[part 1 of 2: packages /EcuInstances to /CommunicationClusters/BODY3]
AUTOSAR XML (schema 00049)
# Copyright (c) 2023 Mercedes-Benz AG
package /EcuInstances
  ecu instance RBTM_FL:
    variation-point=post-build-variant-condition{matching-criterion=SideAllocation, value=0}
    associated-com-i-pdu-group=[TxMess_RBTM_FL_BODY3, RBTM_FL_BODY3_Tx_PNC_All_Active, RBTM_FL_BODY3_Tx_PNC_20, RBTM_FL_BODY3_Rx_PNC_All_Active, RBTM_FL_BODY3_Rx_PNC_20]
    com-configuration-gw-time-base=0.005
    com-configuration-rx-time-base=0.005
    com-configuration-tx-time-base=0.005
    pn-reset-time=1.1
    pnc-prepare-sleep-timer=1.3
    pnc-synchronous-wakeup=false
    sleep-mode-supported=true
    wake-up-over-bus-supported=true
    can communication controller RBTM_FL_BODY3: wake-up-by-controller-supported=true, can-controller-attributes=can-controller-configuration-requirements={max-number-of-time-quanta-per-bit=20, max-sample-point=81.25, max-sync-jump-width=20, min-number-of-time-quanta-per-bit=15, min-sample-point=80, min-sync-jump-width=18.75}
    can communication connector RBTM_FL_BODY3_8uqv9blm85ehm0msat385m76v: comm-controller=RBTM_FL_BODY3, create-ecu-wakeup-source=false, pnc-gateway-type=NONE, pnc-wakeup-data-mask=268435712
  ecu instance RBTM_FL:  # RBTM_FR
    variation-point=post-build-variant-condition{matching-criterion=SideAllocation, value=1}
    associated-com-i-pdu-group=[TxMess_RBTM_FR_BODY3, RBTM_FR_BODY3_Tx_PNC_All_Active, RBTM_FR_BODY3_Tx_PNC_20, RBTM_FR_BODY3_Rx_PNC_All_Active, RBTM_FR_BODY3_Rx_PNC_20]
    com-configuration-gw-time-base=0.005
    com-configuration-rx-time-base=0.005
    com-configuration-tx-time-base=0.005
    pn-reset-time=1.1
    pnc-prepare-sleep-timer=1.3
    pnc-synchronous-wakeup=false
    sleep-mode-supported=true
    wake-up-over-bus-supported=true
    can communication controller RBTM_FR_BODY3: wake-up-by-controller-supported=true, can-controller-attributes=can-controller-configuration-requirements={max-number-of-time-quanta-per-bit=20, max-sample-point=81.25, max-sync-jump-width=20, min-number-of-time-quanta-per-bit=15, min-sample-point=80, min-sync-jump-width=18.75}
    can communication connector RBTM_FR_BODY3_4xwwtd59665s787n6ctawh7k8: comm-controller=RBTM_FR_BODY3, create-ecu-wakeup-source=false, pnc-gateway-type=NONE, pnc-wakeup-data-mask=268435712
package /Systems
  system SYSTEM_XDIS: category=SYSTEM_EXTRACT, container-i-pdu-header-byte-order=big-endian, ecu-extract-version=2023.29.00, pnc-vector-length=7, pnc-vector-offset=1, system-version=2023.29.00
package /SystemSignals
  36 x system signal:
    CRC_DPC_Md_Rq_ESP_Pr5_ST3: data-constr=c16_CRC_woSNA  # CRC-Checksumme der Signal Gruppe gemäß AUTOSAR Profil 5 / CRC-checksum of signal group according to AUTOSAR Profile 5
    CRC_PT4_PTCoor9_Pr5_ST3: data-constr=c16_CRC_woSNA  # CRC-Checksumme der Signal Gruppe gemäß AUTOSAR Profil 5 / CRC-checksum of signal group according to AUTOSAR Profile 5
    DPC_GlobalMd_Rq_ST3: compu-method=c04_DPC_GlobalMd_Rq, data-constr=c04_DPC_GlobalMd_Rq  # Fahrprogrammwahl: Anforderung Global / Driving program control: global mode request
    DPC_GlobalMd_TrgRq_ST3: compu-method=c02_Ndef_False_True_ST3, data-constr=c02_Ndef_False_True_ST3  # Fahrprogrammwahl: Global erneut anfordern / Driving program control: global mode trigger request
    DPC_Md_ABC_Preview_Rq_ST3: compu-method=c02_NDef_On_Off, data-constr=c02_NDef_On_Off  # Fahrprogrammwahl: Anforderung ABC Preview / Driving program control mode: ABC Preview request
    DPC_Md_ESP_Rq_ST3: compu-method=c04_DPC_Md_ESP_Rq_ST3, data-constr=c04_DPC_Md_ESP_Rq_ST3  # Fahrprogrammwahl: Anforderung ESP / Driving program control ESP request
    DPC_Md_eSPC_Carv_Rq_ST3: compu-method=c02_NDef_On_Off, data-constr=c02_NDef_On_Off  # Fahrprogrammwahl: eSPC Carving Anforderung / Driving program control mode: eSPC Carving request
    DPC_Md_ExhstFlap_Rq_ST3: compu-method=c03_DPC_Md_ExhaustFlap, data-constr=c03_DPC_Md_ExhaustFlap  # Fahrprogrammwahl: Anforderung Abgasklappe Modus / Driving program control: ExhaustFlap mode request
    DPC_Md_Ht_Rq_ST3: compu-method=c02_NDef_ECO_Comfort, data-constr=c02_NDef_ECO_Comfort  # Fahrprogrammwahl: Anforderung Heizung / Driving program control: heating request
    DPC_Md_PwrFreeD_Plus_Rq_ST3: compu-method=c02_NDef_On_Off, data-constr=c02_NDef_On_Off  # Fahrprogrammwahl: Anforderung "Kraftfrei in D +" / Driving program control: "Power free in D +" request
    DPC_Md_SSA_Rq_ST3: compu-method=c02_DPC_Md_SSA, data-constr=c02_DPC_Md_SSA  # Fahrprogrammwahl: Anforderung Stopp/Start-Automatik / Driving program control: stop start automatic mode request
    DPC_Md_St_Rq_ST3: compu-method=c03_DPC_Md_St, data-constr=c03_DPC_Md_St  # Fahrprogrammwahl: Anforderung Lenkung / Driving program control: steering mode request
    DPC_Md_Susp_Rq_ST3: compu-method=c05_DPC_Md_Susp_V2, data-constr=c05_DPC_Md_Susp_V2  # Fahrprogrammwahl: Anforderung Federung/Dmpfung / Driving program control: suspension mode request
    DPC_Md_SuspLvl_Rq_ST3: compu-method=c03_m2_p3_1_Init, data-constr=c03_m2_p3_1_Init  # Fahrprogrammwahl: Anforderung Fahrzeugniveau / Driving program control: suspension level mode request
    DPC_Md_Tx_Rq_ST3: compu-method=c04_NDef_Man_Auto, data-constr=c04_NDef_Man_Auto  # Fahrprogrammwahl: Antwort Getriebe (nur AMG) / Driving program control: transmission mode response (only AMG)
    PT4_PTCoor_AccelPdlPosn_D_Raw_ST3: compu-method=c08_perc_0_100_0k4, data-constr=c08_perc_0_100_0k4  # Pedalrohwert Fahrer / Accelerator pedal possition raw value (Driver)
    PT4_PTCoor_ClutchPdlPosn_CPC_ST3: compu-method=c08_perc_0_100_0k5, data-constr=c08_perc_0_100_0k5  # Kupplungspedalweg-Sensor Position (Sensor Signal aber zwei Schalter für VAN) / Clutch pedal position (sensor signal, but VAN uses 2 switches to generate this signal in some variants)
    PT4_PTCoor_DAS_Health_Stat_ST3: compu-method=c10_PT4_PTCoor_DAS_Hlth_Stat
    PT4_PTCoor_EcoRcmnd_VehHighSpd_ST3: compu-method=c08_km_p_h_30_250_1_NoRcmnd, data-constr=c08_km_p_h_30_250_1_NoRcmnd  # ECO Fahrprogramm empfohlene Höchstgeschwindigkeit / ECO drive program recommended top speed
    PT4_PTCoor_EcoRcmnd_VehSpd_ST3: compu-method=c08_km_p_h_30_250_1_NoRcmnd, data-constr=c08_km_p_h_30_250_1_NoRcmnd  # ECO Fahrprogramm empfohlene Geschwindigkeit / ECO drive program recommended speed
    PT4_PTCoor_EmgPath_Enbl_ST3: compu-method=c02_Ndef_False_True_ST3, data-constr=c02_Ndef_False_True_ST3  # Notfallpfad Parksperre verfügbar / Park lock emergency path enabled
    PT4_PTCoor_EmgPath_Volt_ST3: compu-method=c08_V_0_25k4_0k1, data-constr=c08_V_0_25k4_0k1  # Spannung Notfallpfad Parksperre / Park lock emergency path voltage
    PT4_PTCoor_EngRPM_ST3: compu-method=c14_rpm_0_16382_1, data-constr=c14_rpm_0_16382_1  # Motordrehzahl / Actual engine rpm
    PT4_PTCoor_KickDnSw_Psd_ST3: compu-method=c02_Ndef_False_True_ST3, data-constr=c02_Ndef_False_True_ST3  # Kickdown betätigt / Kickdown switch pressed
    PT4_PTCoor_LHOM_PkLk_ST3: compu-method=c02_Ndef_False_True_ST3, data-constr=c02_Ndef_False_True_ST3  # Limp-Home Status Parksperre / limp-home mode park lock
    PT4_PTCoor_ShftTcase_Enbl_ST3: compu-method=c02_NDef_Off_On_ST3, data-constr=c02_NDef_Off_On_ST3  # Schaltvorgang Tcase seitens Schaltprogramm erlaubt / shifting process Tcase on the part of shift program permits
    PT4_PTCoor_SSA_StopWarn_ST3: compu-method=c02_Ndef_False_True_ST3, data-constr=c02_Ndef_False_True_ST3  # ASS Vorwarnung Motorstopp / Stop/Start automatic pre-warning engine stop
    PT4_PTCoor_TrsmCtrl_OutRPM_ST3: compu-method=c12_rpm_0_16376_4, data-constr=c12_rpm_0_16376_4  # Aktuelle Getriebeausgangsdrehzahl / Actual transmission output rpm
    PT4_PTCoor_TxBurnOut_Stat_ST3: compu-method=c02_TxBurnOut_Stat, data-constr=c02_TxBurnOut_Stat  # Burnout Status des Getriebes(Nur in AMG Modellen verfügbar) / Burnout state of Transmission(Only provided in AMG models)
    PT4_PTCoor_VehFixMaxSpd_ST3: compu-method=c09_km_p_h_0_500_1, data-constr=c09_km_p_h_0_500_1  # Antriebsstrangbedingte Fahrzeug-Maximalgeschwindigkeit (Anzeigegeschwindigkeit) / Powertrain dependant vehicle fixed maximum speed (display speed)
    PT4_PTCoor_VEPM_DCDC_BuckSuprt_Stat_ST3: compu-method=c03_DCDCBuckSuprtStat_ST3, data-constr=c03_DCDCBuckSuprtStat_ST3  # Status DCDC-Wandler LV-Unterstützung / DCDC converter buck support state
    Rsrv1_DPC_Md_Rq_ESP_Pr5_ST3: data-constr=Rsrv05  # Reserviert für zukünftige Verwendung / Reserved for future use
    Rsrv2_DPC_Md_Rq_ESP_Pr5_ST3: data-constr=Rsrv24  # Reserviert für zukünftige Verwendung / Reserved for future use
    Rsrv4_PT4_PTCoor9_Pr5_ST3: data-constr=Rsrv27  # Reserviert für zukünftige Verwendung / Reserved for future use
    SQC_DPC_Md_Rq_ESP_Pr5_ST3: compu-method=none_1_0, data-constr=c08_0_255_1_SNA_na  # Sequenzzähler / Sequence counter
    SQC_PT4_PTCoor9_Pr5_ST3: compu-method=none_1_0, data-constr=c08_0_255_1_SNA_na  # Sequenzzähler / Sequence counter
package /SystemSignalGroups
  60 x system signal group:
    ADAS_Meta_ST3: system-signal=[ADAS_Meta_CountryCode_ST3, ADAS_Meta_CycCnt_ST3, ADAS_Meta_DrvSide_ST3, ADAS_Meta_HwVer_ST3, ADAS_Meta_MapProvid_ST3, ADAS_Meta_MapVerQuar_ST3, ADAS_Meta_MapVerYear_ST3, ADAS_Meta_ProtVer_Major_ST3, ADAS_Meta_ProtVer_Minor_ST3, ADAS_Meta_ProtVer_MinorSub_ST3, ADAS_Meta_RegionCode_ST3, ADAS_Meta_SpdUnits_ST3]  # ADAS Metadaten / ADAS meta data
    ADAS_Meta_ST3_40sly585w5zu8pqjwib3nr7y7: system-signal=[ADAS_Meta_CountryCode_ST3, ADAS_Meta_CycCnt_ST3, ADAS_Meta_DrvSide_ST3, ADAS_Meta_HwVer_ST3, ADAS_Meta_MapProvid_ST3, ADAS_Meta_MapVerQuar_ST3, ADAS_Meta_MapVerYear_ST3, ADAS_Meta_ProtVer_Major_ST3, ADAS_Meta_ProtVer_Minor_ST3, ADAS_Meta_ProtVer_MinorSub_ST3, ADAS_Meta_RegionCode_ST3, ADAS_Meta_SpdUnits_ST3]  # ADAS Metadaten (degraded) / ADAS meta data (degraded)
    ADAS_Posn_ST3: system-signal=[ADAS_Posn_Age_ST3, ADAS_Posn_CurLane_ST3, ADAS_Posn_CycCnt_ST3, ADAS_Posn_Idx_ST3, ADAS_Posn_MsgTyp_ST3, ADAS_Posn_Offset_ST3, ADAS_Posn_PathIdx_ST3, ADAS_Posn_PosConfdc_ST3, ADAS_Posn_PosProbb_ST3, ADAS_Posn_RelHead_ST3, ADAS_Posn_Spd_ST3]  # ADAS Position
    ADAS_Posn_ST3_cre9f2x2lehhx0k4gxnl4u9sg: system-signal=[ADAS_Posn_Age_ST3, ADAS_Posn_CurLane_ST3, ADAS_Posn_CycCnt_ST3, ADAS_Posn_Idx_ST3, ADAS_Posn_MsgTyp_ST3, ADAS_Posn_Offset_ST3, ADAS_Posn_PathIdx_ST3, ADAS_Posn_PosConfdc_ST3, ADAS_Posn_PosProbb_ST3, ADAS_Posn_RelHead_ST3, ADAS_Posn_Spd_ST3]  # ADAS Position (degraded)
    ADAS_Profile_Short_CurvLn_ST3: system-signal=[ADAS_ProfShort_AccurClass_CL_ST3, ADAS_ProfShort_CtrlPoint_CL_ST3, ADAS_ProfShort_CycCnt_CL_ST3, ADAS_ProfShort_Dist1_CL_ST3, ADAS_ProfShort_MsgTyp_CL_ST3, ADAS_ProfShort_Offset_CL_ST3, ADAS_ProfShort_PathIdx_CL_ST3, ADAS_ProfShort_ReTr_CL_ST3, ADAS_ProfShort_Updt_CL_ST3, ADAS_ProfShort_Value0_CL_ST3, ADAS_ProfShort_Value1_CL_ST3]  # ADAS Kurzcharakteristik Curvature Linear / ADAS short profile Curvature Linear
    ADAS_Profile_Short_CurvLn_ST3_96e9ejcafisp13h7moqj5malh: system-signal=[ADAS_ProfShort_AccurClass_CL_ST3, ADAS_ProfShort_CtrlPoint_CL_ST3, ADAS_ProfShort_CycCnt_CL_ST3, ADAS_ProfShort_Dist1_CL_ST3, ADAS_ProfShort_MsgTyp_CL_ST3, ADAS_ProfShort_Offset_CL_ST3, ADAS_ProfShort_PathIdx_CL_ST3, ADAS_ProfShort_ReTr_CL_ST3, ADAS_ProfShort_Updt_CL_ST3, ADAS_ProfShort_Value0_CL_ST3, ADAS_ProfShort_Value1_CL_ST3]  # ADAS Kurzcharakteristik Curvature Linear (degraded) / ADAS short profile Curvature Linear (degraded)
    Bckl_Sw_Fx_Stat_Pr5_ST3: system-signal=[Bckl_Sw_D_Stat_ST3, Bckl_Sw_FP_Stat_ST3, CRC_Bckl_Sw_Fx_Stat_Pr5_ST3, Rsrv1_Bckl_Sw_Fx_Stat_ST3, SQC_Bckl_Sw_Fx_Stat_Pr5_ST3]  # Bckl Sw Fx Status ST3 / Bckl Sw Fx state ST3
    Bckl_Sw_Fx_Stat_Pr5_ST3_dihag5a55iw4h5qk539fx0kup: system-signal=[Bckl_Sw_D_Stat_ST3, Bckl_Sw_FP_Stat_ST3, CRC_Bckl_Sw_Fx_Stat_Pr5_ST3, Rsrv1_Bckl_Sw_Fx_Stat_ST3, SQC_Bckl_Sw_Fx_Stat_Pr5_ST3]  # Bckl Sw Fx Status ST3 (degraded) / Bckl Sw Fx state ST3 (degraded)
    CLkS_DrRltch_Stat_Pr5_ST3: system-signal=[CRC_CLkS_DrRltch_Stat_Pr5_ST3, DrRLtch_FL_Stat_ST3, DrRLtch_FR_Stat_ST3, DrRLtch_RL_Stat_ST3, DrRLtch_RR_Stat_ST3, SQC_CLkS_DrRltch_Stat_Pr5_ST3]  # Zentralverriegelung Status Drehfalle Türen / Central Locking System Rotary latch doors state
    CLkS_DrRltch_Stat_Pr5_ST3_7at68qvnk0r9npofyykyfq82v: system-signal=[CRC_CLkS_DrRltch_Stat_Pr5_ST3, DrRLtch_FL_Stat_ST3, DrRLtch_FR_Stat_ST3, DrRLtch_RL_Stat_ST3, DrRLtch_RR_Stat_ST3, SQC_CLkS_DrRltch_Stat_Pr5_ST3]  # Zentralverriegelung Status Drehfalle Türen (degraded) / Central Locking System Rotary latch doors state (degraded)
    Develop8_Rq_RBTM_FL_ST3: system-signal=[Develop_Rq_RBTM_FL_01_ST3, Develop_Rq_RBTM_FL_02_ST3, Develop_Rq_RBTM_FL_03_ST3, Develop_Rq_RBTM_FL_04_ST3, Develop_Rq_RBTM_FL_05_ST3, Develop_Rq_RBTM_FL_06_ST3, Develop_Rq_RBTM_FL_07_ST3, Develop_Rq_RBTM_FL_08_ST3]  # Development Request
    Develop8_Rq_RBTM_FL_ST3_48g6nu8rjjp9s4bhq1x3pz06u: system-signal=[Develop_Rq_RBTM_FL_01_ST3, Develop_Rq_RBTM_FL_02_ST3, Develop_Rq_RBTM_FL_03_ST3, Develop_Rq_RBTM_FL_04_ST3, Develop_Rq_RBTM_FL_05_ST3, Develop_Rq_RBTM_FL_06_ST3, Develop_Rq_RBTM_FL_07_ST3, Develop_Rq_RBTM_FL_08_ST3]  # Development Request (degraded)
    Develop8_Rs_RBTM_FL_ST3: system-signal=[Develop_Rs_RBTM_FL_01_ST3, Develop_Rs_RBTM_FL_02_ST3, Develop_Rs_RBTM_FL_03_ST3, Develop_Rs_RBTM_FL_04_ST3, Develop_Rs_RBTM_FL_05_ST3, Develop_Rs_RBTM_FL_06_ST3, Develop_Rs_RBTM_FL_07_ST3, Develop_Rs_RBTM_FL_08_ST3]  # Development Response
    Develop8_Rs_RBTM_FL_ST3_7jg1r8p1skn6yj1t9z2s157vt: system-signal=[Develop_Rs_RBTM_FL_01_ST3, Develop_Rs_RBTM_FL_02_ST3, Develop_Rs_RBTM_FL_03_ST3, Develop_Rs_RBTM_FL_04_ST3, Develop_Rs_RBTM_FL_05_ST3, Develop_Rs_RBTM_FL_06_ST3, Develop_Rs_RBTM_FL_07_ST3, Develop_Rs_RBTM_FL_08_ST3]  # Development Response (degraded)
    DI_Odo_Pr5_ST3: system-signal=[CRC_DI_Odo_Pr5_ST3, Odo_ST3, SQC_DI_Odo_Pr5_ST3]  # DriverInformation Odometer
    DI_Odo_Pr5_ST3_e68xmtlkywxgxsdwekdjjhw3t: system-signal=[CRC_DI_Odo_Pr5_ST3, Odo_ST3, SQC_DI_Odo_Pr5_ST3]  # DriverInformation Odometer (degraded)
    DPC_Md_Rq_ESP_Pr5_ST3: system-signal=[CRC_DPC_Md_Rq_ESP_Pr5_ST3, DPC_GlobalMd_Rq_ST3, DPC_GlobalMd_TrgRq_ST3, DPC_Md_ABC_Preview_Rq_ST3, DPC_Md_ESP_Rq_ST3, DPC_Md_eSPC_Carv_Rq_ST3, DPC_Md_ExhstFlap_Rq_ST3, DPC_Md_Ht_Rq_ST3, DPC_Md_PT_Rq_ST3, DPC_Md_PwrFreeD_Plus_Rq_ST3, DPC_Md_SSA_Rq_ST3, DPC_Md_St_Rq_ST3, DPC_Md_Susp_Rq_ST3, DPC_Md_SuspLvl_Rq_ST3, DPC_Md_Tx_Rq_ST3, Rsrv1_DPC_Md_Rq_ESP_Pr5_ST3, Rsrv2_DPC_Md_Rq_ESP_Pr5_ST3, SQC_DPC_Md_Rq_ESP_Pr5_ST3]  # Dynamic select Anforderung Pr 5 ST3 / Dynamic select request Pr 5 ST3
    DPC_Md_Rq_ESP_Pr5_ST3_dcsny138uwpesz5bmssj1scqi: system-signal=DPC_Md_PT_Rq_ST3  # Dynamic select Anforderung Pr 5 ST3 (degraded) / Dynamic select request Pr 5 ST3 (degraded)
    ELC_Lvr_Stat_Pr5_ST3: system-signal=[CRC_ELC_Lvr_Stat_Pr5_ST3, ELC_HiBmLvr_Stat_ST3, ELC_TurnIndLvr_Stat_ST3, Rsrv1_ELC_Lvr_Stat_Pr5_ST3, SQC_ELC_Lvr_Stat_Pr5_ST3]  # Status Bedienhebel Außenlicht / Exterior light lever state
    ELC_Lvr_Stat_Pr5_ST3_7b68ktfwrvsk1oyozi7cntryn: system-signal=[CRC_ELC_Lvr_Stat_Pr5_ST3, ELC_HiBmLvr_Stat_ST3, ELC_TurnIndLvr_Stat_ST3, Rsrv1_ELC_Lvr_Stat_Pr5_ST3, SQC_ELC_Lvr_Stat_Pr5_ST3]  # Status Bedienhebel Außenlicht (degraded) / Exterior light lever state (degraded)
    EVC_CfgList_01_08_Pr5_ST3: system-signal=[CRC_EVC_CfgList_01_08_Pr5_ST3, EVC_CfgList_01_08_Stat_ST3, EVC_List01_BodyStyle_ST3, EVC_List02_VehLine_ST3, EVC_List03_StStyle_ST3, EVC_List04_YrOfModf_2_ST3, EVC_List05_YrOfModf_1_ST3, EVC_List06_Country_ST3, EVC_List07_TxStyle_ST3, EVC_List08_HL_Style_ST3, SQC_EVC_CfgList_01_08_Pr5_ST3]  # EVC Cfg List 01 08 Pr 5 ST3
    EVC_CfgList_01_08_Pr5_ST3_co3q1mwsf7pwxo2ix5jryc04x: system-signal=[CRC_EVC_CfgList_01_08_Pr5_ST3, EVC_CfgList_01_08_Stat_ST3, EVC_List01_BodyStyle_ST3, EVC_List02_VehLine_ST3, EVC_List03_StStyle_ST3, EVC_List04_YrOfModf_2_ST3, EVC_List05_YrOfModf_1_ST3, EVC_List06_Country_ST3, EVC_List07_TxStyle_ST3, EVC_List08_HL_Style_ST3, SQC_EVC_CfgList_01_08_Pr5_ST3]  # EVC Cfg List 01 08 Pr 5 ST3 (degraded)
    Ign_Stat_Pr5_ST3: system-signal=[CRC_Ign_Stat_Pr5_ST3, ISw_Stat_ST3, KG_StartSw_Psd_ST3, SQC_Ign_Stat_Pr5_ST3, Veh_Op_Mode_ST3]  # Zuendungsstatus / Ignition state
    Ign_Stat_Pr5_ST3_csgs1dv6drms80o1i9p49677w: system-signal=[CRC_Ign_Stat_Pr5_ST3, ISw_Stat_ST3, KG_StartSw_Psd_ST3, SQC_Ign_Stat_Pr5_ST3, Veh_Op_Mode_ST3]  # Zuendungsstatus (degraded) / Ignition state (degraded)
    Meas8_RBTM_FL_ST3: system-signal=[Meas_RBTM_FL_01_ST3, Meas_RBTM_FL_02_ST3, Meas_RBTM_FL_03_ST3, Meas_RBTM_FL_04_ST3, Meas_RBTM_FL_05_ST3, Meas_RBTM_FL_06_ST3, Meas_RBTM_FL_07_ST3, Meas_RBTM_FL_08_ST3]  # Messbotschaft / Measurement
    Meas8_RBTM_FL_ST3_72jyquhuktrmjm0hkqempja37: system-signal=[Meas_RBTM_FL_01_ST3, Meas_RBTM_FL_02_ST3, Meas_RBTM_FL_03_ST3, Meas_RBTM_FL_04_ST3, Meas_RBTM_FL_05_ST3, Meas_RBTM_FL_06_ST3, Meas_RBTM_FL_07_ST3, Meas_RBTM_FL_08_ST3]  # Messbotschaft (degraded) / Measurement (degraded)
    ORC_Impact2_Pr5_ST3: system-signal=[CRC_ORC_Impact2_Pr5_ST3, Impact_minor_ST3, Impact_P_ST3, Impact_R1_ST3, Impact_R2_ST3, Impact_Y_ST3, SQC_ORC_Impact2_Pr5_ST3, VehPosn_ST3]  # ORC Impact 2 ST3
    ORC_Impact2_Pr5_ST3_b9l09rrslyv7vj3o92j69irnd: system-signal=[CRC_ORC_Impact2_Pr5_ST3, Impact_minor_ST3, Impact_P_ST3, Impact_R1_ST3, Impact_R2_ST3, Impact_Y_ST3, SQC_ORC_Impact2_Pr5_ST3, VehPosn_ST3]  # ORC Impact 2 ST3 (degraded)
    ORC_Impact3_Pr5_ST3: system-signal=[CRC_ORC_Impact3_Pr5_ST3, Impact_F1_ST3, Impact_F2_ST3, Impact_F3_ST3, Impact_RO_type1_ST3, Impact_RO_type2_ST3, Impact_S1_ST3, Impact_S2_ST3, Impact_X_ST3, SQC_ORC_Impact3_Pr5_ST3]  # ORC Impact 3 ST3
    ORC_Impact3_Pr5_ST3_c4pqnkonfjwv3uiohsxhe9dwu: system-signal=[CRC_ORC_Impact3_Pr5_ST3, Impact_F1_ST3, Impact_F2_ST3, Impact_F3_ST3, Impact_RO_type1_ST3, Impact_RO_type2_ST3, Impact_S1_ST3, Impact_S2_ST3, Impact_X_ST3, SQC_ORC_Impact3_Pr5_ST3]  # ORC Impact 3 ST3 (degraded)
    PresfAct_Adj_Pr5_ST3: system-signal=[CRC_PresfAct_Adj_Pr5_ST3, Presf_Enbl_ST3, Presf_Fric_Fctr_Lo_ST3, Presf_FricCoeff_Estim_ST3, Presf_Lvl_ST3, Presf_Snd_Rq_ST3, PresfAccelReset_NotExcd_ST3, PresfAct_Adj_Rq_ST3, PresfAct_TensSupp_Rq_ST3, Rsrv6_Presf_Adj_ST3, SQC_PresfAct_Adj_Pr5_ST3]  # Presf Aktor Steuerung ST3 / Presf Actuator adjustment ST3
    PresfAct_Adj_Pr5_ST3_2joar1a41xrgjqab60epnbplm: system-signal=[CRC_PresfAct_Adj_Pr5_ST3, Presf_Enbl_ST3, Presf_Fric_Fctr_Lo_ST3, Presf_FricCoeff_Estim_ST3, Presf_Lvl_ST3, Presf_Snd_Rq_ST3, PresfAccelReset_NotExcd_ST3, PresfAct_Adj_Rq_ST3, PresfAct_TensSupp_Rq_ST3, Rsrv6_Presf_Adj_ST3, SQC_PresfAct_Adj_Pr5_ST3]  # Presf Aktor Steuerung ST3 (degraded) / Presf Actuator adjustment ST3 (degraded)
    PT4_PTCoor4_Pr5_ST3: system-signal=[CRC_PT4_PTCoor4_Pr5_ST3, PT4_PTCoor_EngStartPN14_Stat_ST3, PT4_PTCoor_PT_Rdy_ST3, PT4_PTCoor_SSA_EngSp_ST3, Rsrv1_PT4_PTCoor_PT_Rdy_Pr5_ST3, SQC_PT4_PTCoor4_Pr5_ST3]
    PT4_PTCoor4_Pr5_ST3_af4fxb1ykieox3itqdfzs0kpb: system-signal=[CRC_PT4_PTCoor4_Pr5_ST3, PT4_PTCoor_EngStartPN14_Stat_ST3, PT4_PTCoor_PT_Rdy_ST3, PT4_PTCoor_SSA_EngSp_ST3, Rsrv1_PT4_PTCoor_PT_Rdy_Pr5_ST3, SQC_PT4_PTCoor4_Pr5_ST3]  # PT4_PTCoor4_Pr5_ST3 (degraded)
    PT4_PTCoor9_Pr5_ST3: system-signal=[CRC_PT4_PTCoor9_Pr5_ST3, PT4_PTCoor_Accel_Md_ST3, PT4_PTCoor_AccelPdlPosn_D_Raw_ST3, PT4_PTCoor_ClutchPdlPosn_CPC_ST3, PT4_PTCoor_DAS_Health_Stat_ST3, PT4_PTCoor_EcoRcmnd_VehHighSpd_ST3, PT4_PTCoor_EcoRcmnd_VehSpd_ST3, PT4_PTCoor_EmgPath_Enbl_ST3, PT4_PTCoor_EmgPath_Volt_ST3, PT4_PTCoor_EngRPM_ST3, PT4_PTCoor_KickDnSw_Psd_ST3, PT4_PTCoor_LHOM_PkLk_ST3, PT4_PTCoor_ShftTcase_Enbl_ST3, PT4_PTCoor_SSA_StopWarn_ST3, PT4_PTCoor_TrsmCtrl_OutRPM_ST3, PT4_PTCoor_TxBurnOut_Stat_ST3, PT4_PTCoor_VehFixMaxSpd_ST3, PT4_PTCoor_VEPM_DCDC_BuckSuprt_Stat_ST3, Rsrv4_PT4_PTCoor9_Pr5_ST3, SQC_PT4_PTCoor9_Pr5_ST3]  # PT4 PT Coor 9 Pr 5 ST3
    PT4_PTCoor9_Pr5_ST3_6r95o81sst3tk9w2lzz600cw3: system-signal=PT4_PTCoor_Accel_Md_ST3  # PT4 PT Coor 9 Pr 5 ST3 (degraded)
    PT4_PTCoor_DrvPosn_Gear_Pr5_ST3: system-signal=[CRC_PT4_PTCoor_DrvPosn_Gear_Pr5_ST3, PT4_PTCoor_DrvPosn_Disp_Rq_ST3, PT4_PTCoor_DrvPosn_N_Actv_ST3, PT4_PTCoor_DrvPosn_Stat_ST3, PT4_PTCoor_DrvPosn_Target_ST3, PT4_PTCoor_Gr_ST3, PT4_PTCoor_Gr_Target_ST3, PT4_PTCoor_ShW_MnTrctAxl_D_Allowed_ST3, PT4_PTCoor_ShW_MnTrctAxl_N_Allowed_ST3, PT4_PTCoor_ShW_MnTrctAxl_P_Allow_Drv_ST3, PT4_PTCoor_ShW_MnTrctAxl_P_Allowed_ST3, PT4_PTCoor_ShW_MnTrctAxl_R_Allowed_ST3, PT4_PTCoor_SSA_Standby_Stat_ST3, Rsrv1_PT4_PTCoor_DrvPosn_Gear_Pr5_ST3, SQC_PT4_PTCoor_DrvPosn_Gear_Pr5_ST3]  # PT4 PT Coor Drv Position Gear Pr 5 ST3 / PT4 PT Coor Drv position Gear Pr 5 ST3
    PT4_PTCoor_DrvPosn_Gear_Pr5_ST3_5p8cvrni3ypvuac33rj2asfy9: system-signal=[CRC_PT4_PTCoor_DrvPosn_Gear_Pr5_ST3, PT4_PTCoor_DrvPosn_Disp_Rq_ST3, PT4_PTCoor_DrvPosn_N_Actv_ST3, PT4_PTCoor_DrvPosn_Stat_ST3, PT4_PTCoor_DrvPosn_Target_ST3, PT4_PTCoor_Gr_ST3, PT4_PTCoor_Gr_Target_ST3, PT4_PTCoor_ShW_MnTrctAxl_D_Allowed_ST3, PT4_PTCoor_ShW_MnTrctAxl_N_Allowed_ST3, PT4_PTCoor_ShW_MnTrctAxl_P_Allow_Drv_ST3, PT4_PTCoor_ShW_MnTrctAxl_P_Allowed_ST3, PT4_PTCoor_ShW_MnTrctAxl_R_Allowed_ST3, PT4_PTCoor_SSA_Standby_Stat_ST3, Rsrv1_PT4_PTCoor_DrvPosn_Gear_Pr5_ST3, SQC_PT4_PTCoor_DrvPosn_Gear_Pr5_ST3]  # PT4 PT Coor Drv Position Gear Pr 5 ST3 (degraded) / PT4 PT Coor Drv position Gear Pr 5 ST3 (degraded)
    ROE_RBTM_FL_ST3: system-signal=[ROE_0_RBTM_FL_ST3, ROE_1_RBTM_FL_ST3, ROE_2_RBTM_FL_ST3, ROE_3_RBTM_FL_ST3, ROE_4_RBTM_FL_ST3, ROE_5_RBTM_FL_ST3, ROE_6_RBTM_FL_ST3, ROE_7_RBTM_FL_ST3]  # Ereignis-Antwort / Response on Event
    ROE_RBTM_FL_ST3_6e0rxnifai2txra0wamb18g4m: system-signal=[ROE_0_RBTM_FL_ST3, ROE_1_RBTM_FL_ST3, ROE_2_RBTM_FL_ST3, ROE_3_RBTM_FL_ST3, ROE_4_RBTM_FL_ST3, ROE_5_RBTM_FL_ST3, ROE_6_RBTM_FL_ST3, ROE_7_RBTM_FL_ST3]  # Ereignis-Antwort (degraded) / Response on Event (degraded)
    SBeltTens_SP_Lvl_Pr5_ST3: system-signal=[CRC_SBeltTens_SP_Lvl_Pr5_ST3, RBTMFL_SP_Lvl_Rq_ST35, RBTMFR_SP_Lvl_Rq_ST35, Rsrv0_SBeltTens_SP_Lvl_Pr5_ST3, SQC_SBeltTens_SP_Lvl_Pr5_ST3]  # Seat Belt Tensioner SP Lvl ST3
    SBeltTens_SP_Lvl_Pr5_ST3_4tqpkri37441o5ht9g9ekmyzh: system-signal=[CRC_SBeltTens_SP_Lvl_Pr5_ST3, RBTMFL_SP_Lvl_Rq_ST35, RBTMFR_SP_Lvl_Rq_ST35, Rsrv0_SBeltTens_SP_Lvl_Pr5_ST3, SQC_SBeltTens_SP_Lvl_Pr5_ST3]  # Seat Belt Tensioner SP Lvl ST3 (degraded)
    VSS_TP_Auth_ST3: system-signal=[VSS_TP_Auth_0_ST3, VSS_TP_Auth_1_ST3, VSS_TP_Auth_2_ST3, VSS_TP_Auth_3_ST3, VSS_TP_Auth_4_ST3, VSS_TP_Auth_5_ST3, VSS_TP_Auth_6_ST3, VSS_TP_Auth_7_ST3]  # VSS-Transportprotokoll für Authentifizierung / Vehicle Security System Transport Protocol for authentication broadcast
    VSS_TP_Auth_ST3_6j4id7sghlvlbroli4wjozjik: system-signal=[VSS_TP_Auth_0_ST3, VSS_TP_Auth_1_ST3, VSS_TP_Auth_2_ST3, VSS_TP_Auth_3_ST3, VSS_TP_Auth_4_ST3, VSS_TP_Auth_5_ST3, VSS_TP_Auth_6_ST3, VSS_TP_Auth_7_ST3]  # VSS-Transportprotokoll für Authentifizierung (degraded) / Vehicle Security System Transport Protocol for authentication broadcast (degraded)
    VSS_TP_RealTmOffset_ST3: system-signal=[VSS_TP_RealTmOffset_0_ST3, VSS_TP_RealTmOffset_1_ST3, VSS_TP_RealTmOffset_2_ST3, VSS_TP_RealTmOffset_3_ST3, VSS_TP_RealTmOffset_4_ST3, VSS_TP_RealTmOffset_5_ST3, VSS_TP_RealTmOffset_6_ST3, VSS_TP_RealTmOffset_7_ST3]  # VSS-Transportprotokoll für Echtzeit-Offset / Vehicle Security System Transport Protocol for real time offset broadcast
    VSS_TP_RealTmOffset_ST3_1t7vc44gftc0wv35k5kgc2in9: system-signal=[VSS_TP_RealTmOffset_0_ST3, VSS_TP_RealTmOffset_1_ST3, VSS_TP_RealTmOffset_2_ST3, VSS_TP_RealTmOffset_3_ST3, VSS_TP_RealTmOffset_4_ST3, VSS_TP_RealTmOffset_5_ST3, VSS_TP_RealTmOffset_6_ST3, VSS_TP_RealTmOffset_7_ST3]  # VSS-Transportprotokoll für Echtzeit-Offset (degraded) / Vehicle Security System Transport Protocol for real time offset broadcast (degraded)
    VSS_TP_SecTickCount_Lvl2_ST3: system-signal=[VSS_TP_SecTickCount_Lvl2_0_ST3, VSS_TP_SecTickCount_Lvl2_1_ST3, VSS_TP_SecTickCount_Lvl2_2_ST3, VSS_TP_SecTickCount_Lvl2_3_ST3, VSS_TP_SecTickCount_Lvl2_4_ST3, VSS_TP_SecTickCount_Lvl2_5_ST3, VSS_TP_SecTickCount_Lvl2_6_ST3, VSS_TP_SecTickCount_Lvl2_7_ST3]  # VSS-Transportprotokoll für sichere Zeit Stufe 2 / Vehicle Security System Transport Protocol for secure tick count level #2
    VSS_TP_SecTickCount_Lvl2_ST3_9eubq13iosat764o0lqh5xb6r: system-signal=[VSS_TP_SecTickCount_Lvl2_0_ST3, VSS_TP_SecTickCount_Lvl2_1_ST3, VSS_TP_SecTickCount_Lvl2_2_ST3, VSS_TP_SecTickCount_Lvl2_3_ST3, VSS_TP_SecTickCount_Lvl2_4_ST3, VSS_TP_SecTickCount_Lvl2_5_ST3, VSS_TP_SecTickCount_Lvl2_6_ST3, VSS_TP_SecTickCount_Lvl2_7_ST3]  # VSS-Transportprotokoll für sichere Zeit Stufe 2 (degraded) / Vehicle Security System Transport Protocol for secure tick count level #2 (degraded)
    VSS_TP_SharedSecret_ST3: system-signal=[VSS_TP_SharedSecret_0_ST3, VSS_TP_SharedSecret_1_ST3, VSS_TP_SharedSecret_2_ST3, VSS_TP_SharedSecret_3_ST3, VSS_TP_SharedSecret_4_ST3, VSS_TP_SharedSecret_5_ST3, VSS_TP_SharedSecret_6_ST3, VSS_TP_SharedSecret_7_ST3]  # VSS-Transportprotokoll für gemeinsames Geheimnis / Vehicle Security System Transport Protocol for shared secret broadcast
    VSS_TP_SharedSecret_ST3_8pj4t8t4rm3tw3pk5hj7vonti: system-signal=[VSS_TP_SharedSecret_0_ST3, VSS_TP_SharedSecret_1_ST3, VSS_TP_SharedSecret_2_ST3, VSS_TP_SharedSecret_3_ST3, VSS_TP_SharedSecret_4_ST3, VSS_TP_SharedSecret_5_ST3, VSS_TP_SharedSecret_6_ST3, VSS_TP_SharedSecret_7_ST3]  # VSS-Transportprotokoll für gemeinsames Geheimnis (degraded) / Vehicle Security System Transport Protocol for shared secret broadcast (degraded)
    VSS_TP_VIN_ST3: system-signal=[VSS_TP_VIN_0_ST3, VSS_TP_VIN_1_ST3, VSS_TP_VIN_2_ST3, VSS_TP_VIN_3_ST3, VSS_TP_VIN_4_ST3, VSS_TP_VIN_5_ST3, VSS_TP_VIN_6_ST3, VSS_TP_VIN_7_ST3]  # VSS-Transportprotokoll für Fahrzeugidentifikationsnummer / Vehicle Security System Transport Protocol for Vehicle Identification Number
    VSS_TP_VIN_ST3_bz1xsv84cxzl09j028gn39p69: system-signal=[VSS_TP_VIN_0_ST3, VSS_TP_VIN_1_ST3, VSS_TP_VIN_2_ST3, VSS_TP_VIN_3_ST3, VSS_TP_VIN_4_ST3, VSS_TP_VIN_5_ST3, VSS_TP_VIN_6_ST3, VSS_TP_VIN_7_ST3]  # VSS-Transportprotokoll für Fahrzeugidentifikationsnummer (degraded) / Vehicle Security System Transport Protocol for Vehicle Identification Number (degraded)
    Develop8_Rq_RBTM_FR_ST3: system-signal=[Develop_Rq_RBTM_FR_01_ST3, Develop_Rq_RBTM_FR_02_ST3, Develop_Rq_RBTM_FR_03_ST3, Develop_Rq_RBTM_FR_04_ST3, Develop_Rq_RBTM_FR_05_ST3, Develop_Rq_RBTM_FR_06_ST3, Develop_Rq_RBTM_FR_07_ST3, Develop_Rq_RBTM_FR_08_ST3]  # Development Request
    Develop8_Rq_RBTM_FR_ST3_bcqj2sqez8u9spf5qxmu4a35u: system-signal=[Develop_Rq_RBTM_FR_01_ST3, Develop_Rq_RBTM_FR_02_ST3, Develop_Rq_RBTM_FR_03_ST3, Develop_Rq_RBTM_FR_04_ST3, Develop_Rq_RBTM_FR_05_ST3, Develop_Rq_RBTM_FR_06_ST3, Develop_Rq_RBTM_FR_07_ST3, Develop_Rq_RBTM_FR_08_ST3]  # Development Request (degraded)
    Develop8_Rs_RBTM_FR_ST3: system-signal=[Develop_Rs_RBTM_FR_01_ST3, Develop_Rs_RBTM_FR_02_ST3, Develop_Rs_RBTM_FR_03_ST3, Develop_Rs_RBTM_FR_04_ST3, Develop_Rs_RBTM_FR_05_ST3, Develop_Rs_RBTM_FR_06_ST3, Develop_Rs_RBTM_FR_07_ST3, Develop_Rs_RBTM_FR_08_ST3]  # Development Response
    Develop8_Rs_RBTM_FR_ST3_5t18pq0a13t698v0vsj7yvmmm: system-signal=[Develop_Rs_RBTM_FR_01_ST3, Develop_Rs_RBTM_FR_02_ST3, Develop_Rs_RBTM_FR_03_ST3, Develop_Rs_RBTM_FR_04_ST3, Develop_Rs_RBTM_FR_05_ST3, Develop_Rs_RBTM_FR_06_ST3, Develop_Rs_RBTM_FR_07_ST3, Develop_Rs_RBTM_FR_08_ST3]  # Development Response (degraded)
    Meas8_RBTM_FR_ST3: system-signal=[Meas_RBTM_FR_01_ST3, Meas_RBTM_FR_02_ST3, Meas_RBTM_FR_03_ST3, Meas_RBTM_FR_04_ST3, Meas_RBTM_FR_05_ST3, Meas_RBTM_FR_06_ST3, Meas_RBTM_FR_07_ST3, Meas_RBTM_FR_08_ST3]  # Messbotschaft / Measurement
    Meas8_RBTM_FR_ST3_7ba3lhjy9fnhufd3n9dyw0p9p: system-signal=[Meas_RBTM_FR_01_ST3, Meas_RBTM_FR_02_ST3, Meas_RBTM_FR_03_ST3, Meas_RBTM_FR_04_ST3, Meas_RBTM_FR_05_ST3, Meas_RBTM_FR_06_ST3, Meas_RBTM_FR_07_ST3, Meas_RBTM_FR_08_ST3]  # Messbotschaft (degraded) / Measurement (degraded)
    ROE_RBTM_FR_ST3: system-signal=[ROE_0_RBTM_FR_ST3, ROE_1_RBTM_FR_ST3, ROE_2_RBTM_FR_ST3, ROE_3_RBTM_FR_ST3, ROE_4_RBTM_FR_ST3, ROE_5_RBTM_FR_ST3, ROE_6_RBTM_FR_ST3, ROE_7_RBTM_FR_ST3]  # Ereignis-Antwort / Response on Event
    ROE_RBTM_FR_ST3_3f1btonh6ivdn6ytgyuu9rtt1: system-signal=[ROE_0_RBTM_FR_ST3, ROE_1_RBTM_FR_ST3, ROE_2_RBTM_FR_ST3, ROE_3_RBTM_FR_ST3, ROE_4_RBTM_FR_ST3, ROE_5_RBTM_FR_ST3, ROE_6_RBTM_FR_ST3, ROE_7_RBTM_FR_ST3]  # Ereignis-Antwort (degraded) / Response on Event (degraded)
package /Pdus/BODY3/PKG_BODY3
  pdu Bckl_Sw_Fx_Stat_ST3: length=4, minimum-delay=0.02, transmission-mode-true-timing={cyclic-timing=time-period=0.2, event-controlled-timing=number-of-repetitions=0}, unused-bit-pattern=255  # Bckl Sw Fx Status ST3 / Bckl Sw Fx state ST3
    signal Bckl_Sw_D_Stat_ST3: start 24, 2 bit, little-endian, data-type-policy=OVERRIDE, i-signal-type=PRIMITIVE, init-value=3, base-type=uint8, invalid-value=3, compu-method=c02_Bckl_Sw_Stat, data-constr=c02_Bckl_Sw_Stat, transfer-property=TRIGGERED-ON-CHANGE, to RBTM_FL(timeout 1.1 s)  # Status Gurtschloss Fahrer / Buckle switch driver state
    signal Bckl_Sw_FP_Stat_ST3: start 26, 2 bit, little-endian, data-type-policy=OVERRIDE, i-signal-type=PRIMITIVE, init-value=3, base-type=uint8, invalid-value=3, compu-method=c02_Bckl_Sw_Stat, data-constr=c02_Bckl_Sw_Stat, transfer-property=TRIGGERED-ON-CHANGE, to RBTM_FL(timeout 1.1 s)  # Status Gurtschloss Beifahrer / Buckle switch front passenger state
    signal CRC_Bckl_Sw_Fx_Stat_Pr5_ST3: start 0, 16 bit, little-endian, data-type-policy=OVERRIDE, i-signal-type=PRIMITIVE, init-value=33522, base-type=uint16, data-constr=c16_CRC_woSNA, transfer-property=PENDING, to RBTM_FL(timeout 1.1 s)  # CRC-Checksumme der Signal Gruppe gemäß AUTOSAR Profil 5 / CRC-checksum of signal group according to AUTOSAR Profile 5
    signal SQC_Bckl_Sw_Fx_Stat_Pr5_ST3: start 16, 8 bit, little-endian, data-type-policy=OVERRIDE, i-signal-type=PRIMITIVE, init-value=0, base-type=uint8, compu-method=none_1_0, data-constr=c08_0_255_1_SNA_na, transfer-property=PENDING, to RBTM_FL(timeout 1.1 s)  # Sequenzzähler / Sequence counter
    signal Rsrv1_Bckl_Sw_Fx_Stat_ST3: start 28, 4 bit, little-endian, data-type-policy=OVERRIDE, i-signal-type=PRIMITIVE, init-value=15, base-type=uint8, invalid-value=15, data-constr=Rsrv04, transfer-property=PENDING, to RBTM_FL  # Reserviert für zukünftige Verwendung / Reserved for future use
    mapping Bckl_Sw_Fx_Stat_Pr5_ST3_dihag5a55iw4h5qk539fx0kup: i-signal-group=Bckl_Sw_Fx_Stat_Pr5_ST3_dihag5a55iw4h5qk539fx0kup, packing-byte-order=little-endian, transfer-property=TRIGGERED-ON-CHANGE
  pdu ELC_Lvr_Stat_ST3: length=4, minimum-delay=0.02, transmission-mode-true-timing={cyclic-timing=time-period=0.1, event-controlled-timing=number-of-repetitions=0}, unused-bit-pattern=255  # Status Bedienhebel Außenlicht / Exterior light lever state
    signal ELC_TurnIndLvr_Stat_ST3: start 24, 2 bit, little-endian, data-type-policy=OVERRIDE, i-signal-type=PRIMITIVE, init-value=0, base-type=uint8, invalid-value=3, compu-method=c02_TurnIndLvr_Stat, data-constr=c02_TurnIndLvr_Stat, to RBTM_FL(timeout 1.1 s)  # Status Blinkerhebel / Turn indicator lever state
    signal CRC_ELC_Lvr_Stat_Pr5_ST3: start 0, 16 bit, little-endian, data-type-policy=OVERRIDE, i-signal-type=PRIMITIVE, init-value=40318, base-type=uint16, data-constr=c16_CRC_woSNA, transfer-property=PENDING  # CRC-Checksumme der Signal Gruppe gemäß AUTOSAR Profil 5 / CRC-checksum of signal group according to AUTOSAR Profile 5
    signal ELC_HiBmLvr_Stat_ST3: start 26, 2 bit, little-endian, data-type-policy=OVERRIDE, i-signal-type=PRIMITIVE, init-value=0, base-type=uint8, invalid-value=3, compu-method=c02_HiBmLvr_Stat, data-constr=c02_HiBmLvr_Stat, transfer-property=PENDING  # Fernlichthebel Betätigung / High beam lever state
    signal Rsrv1_ELC_Lvr_Stat_Pr5_ST3: start 28, 4 bit, little-endian, data-type-policy=OVERRIDE, i-signal-type=PRIMITIVE, init-value=15, base-type=uint8, invalid-value=15, data-constr=Rsrv04, transfer-property=PENDING  # Reserviert für zukünftige Verwendung / Reserved for future use
    signal SQC_ELC_Lvr_Stat_Pr5_ST3: start 16, 8 bit, little-endian, data-type-policy=OVERRIDE, i-signal-type=PRIMITIVE, init-value=0, base-type=uint8, compu-method=none_1_0, data-constr=c08_0_255_1_SNA_na, transfer-property=PENDING  # Sequenzzähler / Sequence counter
    mapping ELC_Lvr_Stat_Pr5_ST3_7b68ktfwrvsk1oyozi7cntryn: i-signal-group=ELC_Lvr_Stat_Pr5_ST3_7b68ktfwrvsk1oyozi7cntryn, packing-byte-order=little-endian, transfer-property=TRIGGERED-ON-CHANGE
  pdu Ign_Stat_ST3: length=4, minimum-delay=0.02, transmission-mode-true-timing={cyclic-timing=time-period=0.1, event-controlled-timing=number-of-repetitions=0}, unused-bit-pattern=255  # Zuendungsstatus / Ignition state
    signal CRC_Ign_Stat_Pr5_ST3: start 0, 16 bit, little-endian, data-type-policy=OVERRIDE, i-signal-type=PRIMITIVE, init-value=20886, base-type=uint16, data-constr=c16_CRC_woSNA, transfer-property=PENDING, to RBTM_FL(timeout 1.05 s)  # CRC-Checksumme der Signal Gruppe gemäß AUTOSAR Profil 5 / CRC-checksum of signal group according to AUTOSAR Profile 5
    signal ISw_Stat_ST3: start 24, 3 bit, little-endian, data-type-policy=OVERRIDE, i-signal-type=PRIMITIVE, init-value=7, base-type=uint8, invalid-value=7, compu-method=c03_ISw_Stat, data-constr=c03_ISw_Stat, transfer-property=TRIGGERED-ON-CHANGE, to RBTM_FL(timeout 1.05 s)  # Klemmenstatus / Ignition switch state
    signal SQC_Ign_Stat_Pr5_ST3: start 16, 8 bit, little-endian, data-type-policy=OVERRIDE, i-signal-type=PRIMITIVE, init-value=0, base-type=uint8, compu-method=none_1_0, data-constr=c08_0_255_1_SNA_na, transfer-property=PENDING, to RBTM_FL(timeout 1.05 s)  # Sequenzzähler / Sequence counter
    signal KG_StartSw_Psd_ST3: start 31, 1 bit, little-endian, data-type-policy=OVERRIDE, i-signal-type=PRIMITIVE, init-value=0, base-type=boolean, transfer-property=PENDING, to RBTM_FL  # Keyless Go Starttaster betätigt / Keyless Go start switch pressed
    signal Veh_Op_Mode_ST3: start 27, 4 bit, little-endian, data-type-policy=OVERRIDE, i-signal-type=PRIMITIVE, init-value=0, base-type=uint8, invalid-value=15, compu-method=c04_VehOpMode, data-constr=c04_VehOpMode, transfer-property=PENDING, to RBTM_FL  # Fahrzeug Betriebsmodus / Operating Mode Vehicle
    mapping Ign_Stat_Pr5_ST3_csgs1dv6drms80o1i9p49677w: i-signal-group=Ign_Stat_Pr5_ST3_csgs1dv6drms80o1i9p49677w, packing-byte-order=little-endian, transfer-property=TRIGGERED-ON-CHANGE
  pdu Impact2_ST3: length=4, minimum-delay=0.02, transmission-mode-condition{data-filter={data-filter-type=MASKED-NEW-DIFFERS-X, mask=1, x=0}, i-signal-in-i-pdu=Impact_Y_ST3}, transmission-mode-false-timing=cyclic-timing=time-period=0.5, transmission-mode-true-timing=cyclic-timing=time-period=0.02, unused-bit-pattern=255  # ORC Impact 2 ST3
    signal Impact_Y_ST3: start 24, 1 bit, little-endian, data-type-policy=OVERRIDE, i-signal-type=PRIMITIVE, init-value=0, base-type=boolean, to RBTM_FL  # Beliebiges Crashereignis vorhanden (Red) / Any impact event (Redundancy)
    signal CRC_ORC_Impact2_Pr5_ST3: start 0, 16 bit, little-endian, data-type-policy=OVERRIDE, i-signal-type=PRIMITIVE, init-value=38142, base-type=uint16, data-constr=c16_CRC_woSNA  # CRC-Checksumme der Signal Gruppe gemäß AUTOSAR Profil 5 / CRC-checksum of signal group according to AUTOSAR Profile 5
    signal Impact_minor_ST3: start 25, 1 bit, little-endian, data-type-policy=OVERRIDE, i-signal-type=PRIMITIVE, init-value=0, base-type=boolean  # Bagatellunfall / minor impact
    signal Impact_P_ST3: start 28, 1 bit, little-endian, data-type-policy=OVERRIDE, i-signal-type=PRIMITIVE, init-value=0, base-type=boolean  # Fußgängeranprall / pedestrian collision
    signal Impact_R1_ST3: start 27, 1 bit, little-endian, data-type-policy=OVERRIDE, i-signal-type=PRIMITIVE, init-value=0, base-type=boolean  # Heckaufprall Stufe 1 / Collision rear level 1
    signal Impact_R2_ST3: start 26, 1 bit, little-endian, data-type-policy=OVERRIDE, i-signal-type=PRIMITIVE, init-value=0, base-type=boolean  # Heckaufprall Stufe 2 / Collision rear level 2
    signal SQC_ORC_Impact2_Pr5_ST3: start 16, 8 bit, little-endian, data-type-policy=OVERRIDE, i-signal-type=PRIMITIVE, init-value=0, base-type=uint8, compu-method=none_1_0, data-constr=c08_0_255_1_SNA_na  # Sequenzzähler / Sequence counter
    signal VehPosn_ST3: start 29, 3 bit, little-endian, data-type-policy=OVERRIDE, i-signal-type=PRIMITIVE, init-value=0, base-type=uint8, invalid-value=7, compu-method=c03_VehPos_ST3, data-constr=c03_VehPos_ST3  # Fahrzeugendlage / Vehicle Position
    mapping ORC_Impact2_Pr5_ST3_b9l09rrslyv7vj3o92j69irnd: i-signal-group=ORC_Impact2_Pr5_ST3_b9l09rrslyv7vj3o92j69irnd, packing-byte-order=little-endian, transfer-property=PENDING
  pdu ADAS_PREDICTION_ST3_6: length=8, transmission-mode-condition{data-filter={data-filter-type=MASKED-NEW-EQUALS-X, mask=7, x=6}, i-signal-in-i-pdu=ADAS_Prediction_MsgTyp_ST36}, transmission-mode-true-timing=cyclic-timing=time-period=0.1, unused-bit-pattern=255
    signal ADAS_Meta_RegionCode_ST36: start 33, 15 bit, little-endian, data-type-policy=OVERRIDE, i-signal-type=PRIMITIVE, init-value=32767, base-type=uint16, invalid-value=32767, compu-method=c15_ADAS_RegionCode, data-constr=c15_ADAS_RegionCode, to RBTM_FL(timeout 10.1 s)  # Gebietscode / Region Code
    signal ADAS_Meta_CountryCode_ST36: start 6, 10 bit, little-endian, data-type-policy=OVERRIDE, i-signal-type=PRIMITIVE, init-value=0, base-type=uint16, invalid-value=1023, compu-method=c10_ADAS_CountryCode, data-constr=c10_ADAS_CountryCode, to RBTM_FL(timeout 10.1 s)  # Ländercode / Country Code
    signal ADAS_Prediction_MsgTyp_ST36: start 0, 3 bit, little-endian, data-type-policy=OVERRIDE, i-signal-type=PRIMITIVE, init-value=7, base-type=uint8, invalid-value=7, compu-method=c03_MsgTyp_1_to_7, data-constr=c03_MsgTyp_1_to_7, transfer-property=PENDING, to RBTM_FL  # ADAS Prediction: Message Type
    signal ADAS_Meta_ProtVer_MinorSub_ST36: start 17, 3 bit, little-endian, data-type-policy=OVERRIDE, i-signal-type=PRIMITIVE, init-value=0, base-type=uint8, compu-method=c03_0_to_7_1_no_SNA, data-constr=c03_0_to_7_1_no_SNA  # (Subunter-) Protokoll-Version / Protocol Version (Sub-Minor)
    signal ADAS_Meta_MapVerYear_ST36: start 48, 6 bit, little-endian, data-type-policy=OVERRIDE, i-signal-type=PRIMITIVE, init-value=63, base-type=uint8, invalid-value=63, compu-method=c06_ADAS_MapVerYear, data-constr=c06_ADAS_MapVerYear  # Kartenversion (Jahr) / Map Version (Year)
    signal ADAS_Meta_ProtVer_Minor_ST36: start 56, 4 bit, little-endian, data-type-policy=OVERRIDE, i-signal-type=PRIMITIVE, init-value=0, base-type=uint8, compu-method=c04_0_15_1_SNA_na, data-constr=c04_0_15_1_SNA_na  # (Unter-) Protokoll-Version / Protocol Version (Minor)
    signal ADAS_Meta_CycCnt_ST36: start 22, 2 bit, little-endian, data-type-policy=OVERRIDE, i-signal-type=PRIMITIVE, init-value=0, base-type=uint8, compu-method=c02_0_3_1_nSNA, data-constr=c02_0_3_1_nSNA  # zyklischer Zähler / Cyclic Counter
    signal ADAS_Meta_SpdUnits_ST36: start 60, 1 bit, little-endian, data-type-policy=OVERRIDE, i-signal-type=PRIMITIVE, init-value=0, base-type=uint8, compu-method=c01_UnitVehSpd, data-constr=c01_UnitVehSpd  # Angabe Geschwindigkeitseinheit / Definition Speed Unit
    signal ADAS_Meta_MapProvid_ST36: start 3, 3 bit, little-endian, data-type-policy=OVERRIDE, i-signal-type=PRIMITIVE, init-value=7, base-type=uint8, invalid-value=7, compu-method=c03_ADAS_MapProvid, data-constr=c03_ADAS_MapProvid  # Kartenanbieter / Map Provider
    signal ADAS_Meta_ProtVer_Major_ST36: start 20, 2 bit, little-endian, data-type-policy=OVERRIDE, i-signal-type=PRIMITIVE, init-value=0, base-type=uint8, compu-method=c02_0_3_1_nSNA, data-constr=c02_0_3_1_nSNA  # (Haupt-) Protokoll-Version / Protocol Version (Major)
    signal ADAS_Meta_MapVerQuar_ST36: start 54, 2 bit, little-endian, data-type-policy=OVERRIDE, i-signal-type=PRIMITIVE, init-value=0, base-type=uint8, compu-method=c02_ADAS_MapVerQuar, data-constr=c02_ADAS_MapVerQuar  # Kartenversion (Quartal) / Map Version (Quarter)
    signal ADAS_Meta_DrvSide_ST36: start 16, 1 bit, little-endian, data-type-policy=OVERRIDE, i-signal-type=PRIMITIVE, init-value=1, base-type=uint8, compu-method=c01_Right_Left, data-constr=c01_Right_Left  # Seite auf der gefahren wird / Driving Side
    signal ADAS_Meta_HwVer_ST36: start 24, 9 bit, little-endian, data-type-policy=OVERRIDE, i-signal-type=PRIMITIVE, init-value=0, base-type=uint16, compu-method=c09_ADAS_HwVer, data-constr=c09_ADAS_HwVer  # Hardware Version
    mapping ADAS_Meta_ST3_40sly585w5zu8pqjwib3nr7y7: i-signal-group=ADAS_Meta_ST3_40sly585w5zu8pqjwib3nr7y7_6, packing-byte-order=little-endian, transfer-property=PENDING
  pdu ADAS_PREDICTION_ST3_7: length=8, transmission-mode-condition{data-filter={data-filter-type=MASKED-NEW-EQUALS-X, mask=7, x=7}, i-signal-in-i-pdu=ADAS_Prediction_MsgTyp_ST37}, transmission-mode-true-timing=cyclic-timing=time-period=0.1, unused-bit-pattern=255
    signal ADAS_Prediction_MsgTyp_ST37: start 0, 3 bit, little-endian, data-type-policy=OVERRIDE, i-signal-type=PRIMITIVE, init-value=7, base-type=uint8, invalid-value=7, compu-method=c03_MsgTyp_1_to_7, data-constr=c03_MsgTyp_1_to_7, transfer-property=PENDING, to RBTM_FL  # ADAS Prediction: Message Type
  pdu ADAS_PROFILE_SHORT_ST3_1: length=8, transmission-mode-condition{data-filter={data-filter-type=MASKED-NEW-EQUALS-X, mask=31, x=1}, i-signal-in-i-pdu=ADAS_ProfShort_ProfTyp_ST31}, transmission-mode-true-timing=cyclic-timing=time-period=0.1, unused-bit-pattern=255
    signal ADAS_ProfShort_ProfTyp_ST31: start 27, 5 bit, little-endian, data-type-policy=OVERRIDE, i-signal-type=PRIMITIVE, init-value=31, base-type=uint8, invalid-value=31, compu-method=c05_ADAS_ProfShort_ProfTyp, data-constr=c05_ADAS_ProfShort_ProfTyp, transfer-property=PENDING, to RBTM_FL  # Profile Short Message: Profiltyp / Profile Short Message: Profile Type
    signal ADAS_ProfShort_Value1_CL_ST31: start 54, 10 bit, little-endian, data-type-policy=OVERRIDE, i-signal-type=PRIMITIVE, init-value=0, base-type=uint16, invalid-value=1023, compu-method=c10_to_1022_1, data-constr=c10_to_1022_1, to RBTM_FL(timeout 1.1 s)  # Profile Short Message: Value1 Curvature Linear
    signal ADAS_ProfShort_PathIdx_CL_ST31: start 16, 6 bit, little-endian, data-type-policy=OVERRIDE, i-signal-type=PRIMITIVE, init-value=0, base-type=uint8, compu-method=c06_Idx_0_to_63_1, data-constr=c06_Idx_0_to_63_1, to RBTM_FL(timeout 1.1 s)  # Profile Short Message: Pfadnummer Curvature Linear (LongValue=false) / Profile Short Message: Index of path Curvature Linear (LongValue=false)
    signal ADAS_ProfShort_Value0_CL_ST31: start 34, 10 bit, little-endian, data-type-policy=OVERRIDE, i-signal-type=PRIMITIVE, init-value=1023, base-type=uint16, invalid-value=1023, compu-method=c10_to_1022_1, data-constr=c10_to_1022_1, to RBTM_FL(timeout 1.1 s)  # Profile Short Message: Value0 Curvature Linear
    signal ADAS_ProfShort_ReTr_CL_ST31: start 25, 1 bit, little-endian, data-type-policy=OVERRIDE, i-signal-type=PRIMITIVE, init-value=0, base-type=uint8, compu-method=c01_FalseTrue, data-constr=c01_FalseTrue, to RBTM_FL(timeout 1.1 s)  # Profile Short Message: Wiederholte Übertragung Curvature Linear (LongValue=false) / Profile Short Message: Retransmission Curvature Linear (LongValue=false)
    signal ADAS_ProfShort_Offset_CL_ST31: start 3, 13 bit, little-endian, data-type-policy=OVERRIDE, i-signal-type=PRIMITIVE, init-value=8191, base-type=uint16, invalid-value=8191, compu-method=c13_m_0_8190_1, data-constr=c13_m_0_8190_1, to RBTM_FL(timeout 1.1 s)  # Profile Short Message: Offset des Ortes des ersten Profils zum Startort Curvature Linear (LongValue=false) / Profile Short Message: Offset of position of first profile spot from start position Curvature Linear (LongValue=false)
    signal ADAS_ProfShort_Dist1_CL_ST31: start 44, 10 bit, little-endian, data-type-policy=OVERRIDE, i-signal-type=PRIMITIVE, init-value=0, base-type=uint16, invalid-value=1023, compu-method=c10_m_0_510_1, data-constr=c10_m_0_510_1, to RBTM_FL(timeout 1.1 s)  # Profile Short Message: Distance1 Curvature Linear
    signal ADAS_ProfShort_AccurClass_CL_ST31: start 32, 2 bit, little-endian, data-type-policy=OVERRIDE, i-signal-type=PRIMITIVE, init-value=0, base-type=uint8, compu-method=c02_0_3_1_nSNA, data-constr=c02_0_3_1_nSNA  # Profile Short Message: Genauigkeitsklasse Curvature Linear (LongValue=false) / Profile Short Message: Accuracy class Curvature Linear (LongValue=false)
    signal ADAS_ProfShort_CtrlPoint_CL_ST31: start 26, 1 bit, little-endian, data-type-policy=OVERRIDE, i-signal-type=PRIMITIVE, init-value=0, base-type=uint8, compu-method=c01_FalseTrue, data-constr=c01_FalseTrue  # Profile Short Message: Zusätzlicher Kontrollpunkt Curvature Linear (LongValue=false) / Profile Short Message: Additional control point Curvature Linear (LongValue=false)
    signal ADAS_ProfShort_MsgTyp_CL_ST31: start 0, 3 bit, little-endian, data-type-policy=OVERRIDE, i-signal-type=PRIMITIVE, init-value=4, base-type=uint8, invalid-value=7, compu-method=c03_MsgTyp_1_to_7, data-constr=c03_MsgTyp_1_to_7  # Profile Short Message: Messagetyp Curvature Linear (LongValue=false) / Profile Short Message: Message Type Curvature Linear (LongValue=false)
    signal ADAS_ProfShort_CycCnt_CL_ST31: start 22, 2 bit, little-endian, data-type-policy=OVERRIDE, i-signal-type=PRIMITIVE, init-value=0, base-type=uint8, compu-method=c02_0_3_1_nSNA, data-constr=c02_0_3_1_nSNA  # Profile Short Message: Zyklischer Zähler Curvature Linear (LongValue=false) / Profile Short Message: Cyclic Counter Curvature Linear (LongValue=false)
    signal ADAS_ProfShort_Updt_CL_ST31: start 24, 1 bit, little-endian, data-type-policy=OVERRIDE, i-signal-type=PRIMITIVE, init-value=0, base-type=uint8, compu-method=c01_FalseTrue, data-constr=c01_FalseTrue  # Profile Short Message: Update Curvature Linear (LongValue=false)
    mapping ADAS_Profile_Short_CurvLn_ST3_96e9ejcafisp13h7moqj5malh: i-signal-group=ADAS_Profile_Short_CurvLn_ST3_96e9ejcafisp13h7moqj5malh_1, packing-byte-order=little-endian, transfer-property=PENDING
  pdu ADAS_PROFILE_SHORT_ST3_31: length=8, transmission-mode-condition{data-filter={data-filter-type=MASKED-NEW-EQUALS-X, mask=31, x=31}, i-signal-in-i-pdu=ADAS_ProfShort_ProfTyp_ST331}, transmission-mode-true-timing=cyclic-timing=time-period=0.1, unused-bit-pattern=255
    signal ADAS_ProfShort_ProfTyp_ST331: start 27, 5 bit, little-endian, data-type-policy=OVERRIDE, i-signal-type=PRIMITIVE, init-value=31, base-type=uint8, invalid-value=31, compu-method=c05_ADAS_ProfShort_ProfTyp, data-constr=c05_ADAS_ProfShort_ProfTyp, transfer-property=PENDING, to RBTM_FL  # Profile Short Message: Profiltyp / Profile Short Message: Profile Type
  dcm i pdu SDU_DIAG_GLOBAL_ExtCAN_RQ_BODY3_ST3: length=7, diag-pdu-type=DIAG-REQUEST
  dcm i pdu SDU_DIAG_GLOBAL_ExtEth_RQ_BODY3_ST3: length=7, diag-pdu-type=DIAG-REQUEST
  dcm i pdu SDU_DIAG_GLOBAL_IntEth_RQ_BODY3_ST3: length=7, diag-pdu-type=DIAG-REQUEST
  dcm i pdu SDU_DIAG_RBTM_FL_03_ExtCAN_RQ_BODY3_ST3: length=4095, diag-pdu-type=DIAG-REQUEST
  dcm i pdu SDU_DIAG_RBTM_FL_03_ExtCAN_RS_BODY3_ST3: length=4095, diag-pdu-type=DIAG-RESPONSE
  dcm i pdu SDU_DIAG_RBTM_FL_03_ExtEth_RQ_BODY3_ST3: length=4095, diag-pdu-type=DIAG-REQUEST
  dcm i pdu SDU_DIAG_RBTM_FL_03_ExtEth_RS_BODY3_ST3: length=4095, diag-pdu-type=DIAG-RESPONSE
  dcm i pdu SDU_DIAG_RBTM_FL_03_IntEth_RQ_BODY3_ST3: length=4095, diag-pdu-type=DIAG-REQUEST
  dcm i pdu SDU_DIAG_RBTM_FL_03_IntEth_RS_BODY3_ST3: length=4095, diag-pdu-type=DIAG-RESPONSE
  dcm i pdu SDU_DIAG_RBTM_FR_03_ExtCAN_RQ_BODY3_ST3: length=4095, diag-pdu-type=DIAG-REQUEST
  dcm i pdu SDU_DIAG_RBTM_FR_03_ExtCAN_RS_BODY3_ST3: length=4095, diag-pdu-type=DIAG-RESPONSE
  dcm i pdu SDU_DIAG_RBTM_FR_03_ExtEth_RQ_BODY3_ST3: length=4095, diag-pdu-type=DIAG-REQUEST
  dcm i pdu SDU_DIAG_RBTM_FR_03_ExtEth_RS_BODY3_ST3: length=4095, diag-pdu-type=DIAG-RESPONSE
  dcm i pdu SDU_DIAG_RBTM_FR_03_IntEth_RQ_BODY3_ST3: length=4095, diag-pdu-type=DIAG-REQUEST
  dcm i pdu SDU_DIAG_RBTM_FR_03_IntEth_RS_BODY3_ST3: length=4095, diag-pdu-type=DIAG-RESPONSE
package /DataTransformations
  data transformation set DATATRANSFORMATION_SET
    4 x data transformation, all with execute-despite-data-unavailability=true:
      BaseTrans_Profile_5_4: transformer-chain=[ComBasedTransformer4, E2E_Profile_5]  # Base Transformer Base Profile 5
      BaseTrans_Profile_5_8: transformer-chain=[ComBasedTransformer8, E2E_Profile_5]  # Base Transformer Base Profile 5
      BaseTrans_Profile_5_5: transformer-chain=[ComBasedTransformer5, E2E_Profile_5]  # Base Transformer Base Profile 5
      BaseTrans_Profile_5_6: transformer-chain=[ComBasedTransformer6, E2E_Profile_5]  # Base Transformer Base Profile 5
    5 x transformation technology:
      ComBasedTransformer4: buffer-properties={buffer-computation=compu-rational-coeffs={compu-numerator=4, compu-denominator=1}, header-length=0, in-place=false}, protocol=COMBased, transformer-class=SERIALIZER, version=1
      E2E_Profile_5:  # E2E Profile 5
        buffer-properties={header-length=0, in-place=true}
        has-internal-state=true
        needs-original-data=false
        protocol=E2E
        end-to-end-transformation-description{e-2-e-profile-compatibility-props=E_2_E_PROFILE_COMPATIBILITY_PROPS_true, max-delta-counter=3, max-error-state-init=0, max-error-state-invalid=0, max-error-state-valid=0, min-ok-state-init=1, min-ok-state-invalid=1, min-ok-state-valid=1, offset=0, profile-name=PROFILE_05, upper-header-bits-to-shift=0, window-size=10}
        transformer-class=SAFETY
        version=1.0.0
      ComBasedTransformer8: buffer-properties={buffer-computation=compu-rational-coeffs={compu-numerator=8, compu-denominator=1}, header-length=0, in-place=false}, protocol=COMBased, transformer-class=SERIALIZER, version=1
      ComBasedTransformer5: buffer-properties={buffer-computation=compu-rational-coeffs={compu-numerator=5, compu-denominator=1}, header-length=0, in-place=false}, protocol=COMBased, transformer-class=SERIALIZER, version=1
      ComBasedTransformer6: buffer-properties={buffer-computation=compu-rational-coeffs={compu-numerator=6, compu-denominator=1}, header-length=0, in-place=false}, protocol=COMBased, transformer-class=SERIALIZER, version=1
package /ISignalGroups/BODY3/PKG_BODY3/ADAS_POSITION_ST3
  i signal group ADAS_Posn_ST3_cre9f2x2lehhx0k4gxnl4u9sg: i-signal=[ADAS_Posn_Age_ST3, ADAS_Posn_CurLane_ST3, ADAS_Posn_CycCnt_ST3, ADAS_Posn_Idx_ST3, ADAS_Posn_MsgTyp_ST3, ADAS_Posn_Offset_ST3, ADAS_Posn_PathIdx_ST3, ADAS_Posn_PosConfdc_ST3, ADAS_Posn_PosProbb_ST3, ADAS_Posn_RelHead_ST3, ADAS_Posn_Spd_ST3], system-signal-group=ADAS_Posn_ST3_cre9f2x2lehhx0k4gxnl4u9sg  # ADAS Position (degraded)
package /ISignalGroups/BODY3/PKG_BODY3/Bckl_Sw_Fx_Stat_ST3
  i signal group Bckl_Sw_Fx_Stat_Pr5_ST3_dihag5a55iw4h5qk539fx0kup: com-based-signal-group-transformations=BaseTrans_Profile_5_4, i-signal=[Bckl_Sw_D_Stat_ST3, Bckl_Sw_FP_Stat_ST3, CRC_Bckl_Sw_Fx_Stat_Pr5_ST3, Rsrv1_Bckl_Sw_Fx_Stat_ST3, SQC_Bckl_Sw_Fx_Stat_Pr5_ST3], system-signal-group=Bckl_Sw_Fx_Stat_Pr5_ST3_dihag5a55iw4h5qk539fx0kup, end-to-end-transformation-i-signal-props{transformer=E2E_Profile_5, data-ids=52, data-length=32}  # Bckl Sw Fx Status ST3 (degraded) / Bckl Sw Fx state ST3 (degraded)
package /ISignalGroups/BODY3/PKG_BODY3/CLkS_Dr_State_ST3
  i signal group CLkS_DrRltch_Stat_Pr5_ST3_7at68qvnk0r9npofyykyfq82v: com-based-signal-group-transformations=BaseTrans_Profile_5_4, i-signal=[CRC_CLkS_DrRltch_Stat_Pr5_ST3, DrRLtch_FL_Stat_ST3, DrRLtch_FR_Stat_ST3, DrRLtch_RL_Stat_ST3, DrRLtch_RR_Stat_ST3, SQC_CLkS_DrRltch_Stat_Pr5_ST3], system-signal-group=CLkS_DrRltch_Stat_Pr5_ST3_7at68qvnk0r9npofyykyfq82v, end-to-end-transformation-i-signal-props{transformer=E2E_Profile_5, data-ids=16, data-length=32}  # Zentralverriegelung Status Drehfalle Türen (degraded) / Central Locking System Rotary latch doors state (degraded)
package /ISignalGroups/BODY3/PKG_BODY3/Develop8_Rq_RBTM_FL_ST3
  i signal group Develop8_Rq_RBTM_FL_ST3_48g6nu8rjjp9s4bhq1x3pz06u: i-signal=[Develop_Rq_RBTM_FL_01_ST3, Develop_Rq_RBTM_FL_02_ST3, Develop_Rq_RBTM_FL_03_ST3, Develop_Rq_RBTM_FL_04_ST3, Develop_Rq_RBTM_FL_05_ST3, Develop_Rq_RBTM_FL_06_ST3, Develop_Rq_RBTM_FL_07_ST3, Develop_Rq_RBTM_FL_08_ST3], system-signal-group=Develop8_Rq_RBTM_FL_ST3_48g6nu8rjjp9s4bhq1x3pz06u  # Development Request (degraded)
package /ISignalGroups/BODY3/PKG_BODY3/Develop8_Rs_RBTM_FL_ST3
  i signal group Develop8_Rs_RBTM_FL_ST3_7jg1r8p1skn6yj1t9z2s157vt: i-signal=[Develop_Rs_RBTM_FL_01_ST3, Develop_Rs_RBTM_FL_02_ST3, Develop_Rs_RBTM_FL_03_ST3, Develop_Rs_RBTM_FL_04_ST3, Develop_Rs_RBTM_FL_05_ST3, Develop_Rs_RBTM_FL_06_ST3, Develop_Rs_RBTM_FL_07_ST3, Develop_Rs_RBTM_FL_08_ST3], system-signal-group=Develop8_Rs_RBTM_FL_ST3_7jg1r8p1skn6yj1t9z2s157vt  # Development Response (degraded)
package /ISignalGroups/BODY3/PKG_BODY3/DI_OdoSpeedometer_ST3
  i signal group DI_Odo_Pr5_ST3_e68xmtlkywxgxsdwekdjjhw3t: com-based-signal-group-transformations=BaseTrans_Profile_5_6, i-signal=[CRC_DI_Odo_Pr5_ST3, Odo_ST3, SQC_DI_Odo_Pr5_ST3], system-signal-group=DI_Odo_Pr5_ST3_e68xmtlkywxgxsdwekdjjhw3t, end-to-end-transformation-i-signal-props{transformer=E2E_Profile_5, data-ids=186, data-length=48}  # DriverInformation Odometer (degraded)
package /ISignalGroups/BODY3/PKG_BODY3/DPC_Md_Rq_ESP_d1_ST3
  i signal group DPC_Md_Rq_ESP_Pr5_ST3_dcsny138uwpesz5bmssj1scqi: i-signal=DPC_Md_PT_Rq_ST3, system-signal-group=DPC_Md_Rq_ESP_Pr5_ST3_dcsny138uwpesz5bmssj1scqi  # Dynamic select Anforderung Pr 5 ST3 (degraded) / Dynamic select request Pr 5 ST3 (degraded)
package /ISignalGroups/BODY3/PKG_BODY3/ELC_Lvr_Stat_ST3
  i signal group ELC_Lvr_Stat_Pr5_ST3_7b68ktfwrvsk1oyozi7cntryn: com-based-signal-group-transformations=BaseTrans_Profile_5_4, i-signal=[CRC_ELC_Lvr_Stat_Pr5_ST3, ELC_HiBmLvr_Stat_ST3, ELC_TurnIndLvr_Stat_ST3, Rsrv1_ELC_Lvr_Stat_Pr5_ST3, SQC_ELC_Lvr_Stat_Pr5_ST3], system-signal-group=ELC_Lvr_Stat_Pr5_ST3_7b68ktfwrvsk1oyozi7cntryn, end-to-end-transformation-i-signal-props{transformer=E2E_Profile_5, data-ids=218, data-length=32}  # Status Bedienhebel Außenlicht (degraded) / Exterior light lever state (degraded)
package /ISignalGroups/BODY3/PKG_BODY3/EVC_CfgList_01_08_Pr5_ST3
  i signal group EVC_CfgList_01_08_Pr5_ST3_co3q1mwsf7pwxo2ix5jryc04x:  # EVC Cfg List 01 08 Pr 5 ST3 (degraded)
    com-based-signal-group-transformations=BaseTrans_Profile_5_8
    i-signal=[CRC_EVC_CfgList_01_08_Pr5_ST3, EVC_CfgList_01_08_Stat_ST3, EVC_List01_BodyStyle_ST3, EVC_List02_VehLine_ST3, EVC_List03_StStyle_ST3, EVC_List04_YrOfModf_2_ST3, EVC_List05_YrOfModf_1_ST3, EVC_List06_Country_ST3, EVC_List07_TxStyle_ST3, EVC_List08_HL_Style_ST3, SQC_EVC_CfgList_01_08_Pr5_ST3]
    system-signal-group=EVC_CfgList_01_08_Pr5_ST3_co3q1mwsf7pwxo2ix5jryc04x
    end-to-end-transformation-i-signal-props{transformer=E2E_Profile_5, data-ids=6, data-length=64}
package /ISignalGroups/BODY3/PKG_BODY3/Ign_Stat_ST3
  i signal group Ign_Stat_Pr5_ST3_csgs1dv6drms80o1i9p49677w: com-based-signal-group-transformations=BaseTrans_Profile_5_4, i-signal=[CRC_Ign_Stat_Pr5_ST3, ISw_Stat_ST3, KG_StartSw_Psd_ST3, SQC_Ign_Stat_Pr5_ST3, Veh_Op_Mode_ST3], system-signal-group=Ign_Stat_Pr5_ST3_csgs1dv6drms80o1i9p49677w, end-to-end-transformation-i-signal-props{transformer=E2E_Profile_5, data-ids=51, data-length=32}  # Zuendungsstatus (degraded) / Ignition state (degraded)
package /ISignalGroups/BODY3/PKG_BODY3/Impact2_ST3
  i signal group ORC_Impact2_Pr5_ST3_b9l09rrslyv7vj3o92j69irnd: com-based-signal-group-transformations=BaseTrans_Profile_5_4, i-signal=[CRC_ORC_Impact2_Pr5_ST3, Impact_minor_ST3, Impact_P_ST3, Impact_R1_ST3, Impact_R2_ST3, Impact_Y_ST3, SQC_ORC_Impact2_Pr5_ST3, VehPosn_ST3], system-signal-group=ORC_Impact2_Pr5_ST3_b9l09rrslyv7vj3o92j69irnd, end-to-end-transformation-i-signal-props{transformer=E2E_Profile_5, data-ids=15, data-length=32}  # ORC Impact 2 ST3 (degraded)
package /ISignalGroups/BODY3/PKG_BODY3/Impact3_ST3
  i signal group ORC_Impact3_Pr5_ST3_c4pqnkonfjwv3uiohsxhe9dwu:  # ORC Impact 3 ST3 (degraded)
    com-based-signal-group-transformations=BaseTrans_Profile_5_4
    i-signal=[CRC_ORC_Impact3_Pr5_ST3, Impact_F1_ST3, Impact_F2_ST3, Impact_F3_ST3, Impact_RO_type1_ST3, Impact_RO_type2_ST3, Impact_S1_ST3, Impact_S2_ST3, Impact_X_ST3, SQC_ORC_Impact3_Pr5_ST3]
    system-signal-group=ORC_Impact3_Pr5_ST3_c4pqnkonfjwv3uiohsxhe9dwu
    end-to-end-transformation-i-signal-props{transformer=E2E_Profile_5, data-ids=54, data-length=32}
package /ISignalGroups/BODY3/PKG_BODY3/Meas8_RBTM_FL_ST3
  i signal group Meas8_RBTM_FL_ST3_72jyquhuktrmjm0hkqempja37: i-signal=[Meas_RBTM_FL_01_ST3, Meas_RBTM_FL_02_ST3, Meas_RBTM_FL_03_ST3, Meas_RBTM_FL_04_ST3, Meas_RBTM_FL_05_ST3, Meas_RBTM_FL_06_ST3, Meas_RBTM_FL_07_ST3, Meas_RBTM_FL_08_ST3], system-signal-group=Meas8_RBTM_FL_ST3_72jyquhuktrmjm0hkqempja37  # Messbotschaft (degraded) / Measurement (degraded)
package /ISignalGroups/BODY3/PKG_BODY3/PresfAct_Adj_ST3
  i signal group PresfAct_Adj_Pr5_ST3_2joar1a41xrgjqab60epnbplm:  # Presf Aktor Steuerung ST3 (degraded) / Presf Actuator adjustment ST3 (degraded)
    com-based-signal-group-transformations=BaseTrans_Profile_5_8
    i-signal=[CRC_PresfAct_Adj_Pr5_ST3, Presf_Enbl_ST3, Presf_Fric_Fctr_Lo_ST3, Presf_FricCoeff_Estim_ST3, Presf_Lvl_ST3, Presf_Snd_Rq_ST3, PresfAccelReset_NotExcd_ST3, PresfAct_Adj_Rq_ST3, PresfAct_TensSupp_Rq_ST3, Rsrv6_Presf_Adj_ST3, SQC_PresfAct_Adj_Pr5_ST3]
    system-signal-group=PresfAct_Adj_Pr5_ST3_2joar1a41xrgjqab60epnbplm
    end-to-end-transformation-i-signal-props{transformer=E2E_Profile_5, data-ids=270, data-length=64}
package /ISignalGroups/BODY3/PKG_BODY3/PT4_PTCoor4_ST3
  i signal group PT4_PTCoor4_Pr5_ST3_af4fxb1ykieox3itqdfzs0kpb: com-based-signal-group-transformations=BaseTrans_Profile_5_4, i-signal=[CRC_PT4_PTCoor4_Pr5_ST3, PT4_PTCoor_EngStartPN14_Stat_ST3, PT4_PTCoor_PT_Rdy_ST3, PT4_PTCoor_SSA_EngSp_ST3, Rsrv1_PT4_PTCoor_PT_Rdy_Pr5_ST3, SQC_PT4_PTCoor4_Pr5_ST3], system-signal-group=PT4_PTCoor4_Pr5_ST3_af4fxb1ykieox3itqdfzs0kpb, end-to-end-transformation-i-signal-props{transformer=E2E_Profile_5, data-ids=196, data-length=32}  # PT4_PTCoor4_Pr5_ST3 (degraded)
package /ISignalGroups/BODY3/PKG_BODY3/PT4_PTCoor9_d1_BC_F_ST3
  i signal group PT4_PTCoor9_Pr5_ST3_6r95o81sst3tk9w2lzz600cw3: i-signal=PT4_PTCoor_Accel_Md_ST3, system-signal-group=PT4_PTCoor9_Pr5_ST3_6r95o81sst3tk9w2lzz600cw3  # PT4 PT Coor 9 Pr 5 ST3 (degraded)
package /ISignalGroups/BODY3/PKG_BODY3/PT4_PTCoor_DrvPosn_Gear_ST3
  i signal group PT4_PTCoor_DrvPosn_Gear_Pr5_ST3_5p8cvrni3ypvuac33rj2asfy9:  # PT4 PT Coor Drv Position Gear Pr 5 ST3 (degraded) / PT4 PT Coor Drv position Gear Pr 5 ST3 (degraded)
    com-based-signal-group-transformations=BaseTrans_Profile_5_8
    i-signal=[CRC_PT4_PTCoor_DrvPosn_Gear_Pr5_ST3, PT4_PTCoor_DrvPosn_Disp_Rq_ST3, PT4_PTCoor_DrvPosn_N_Actv_ST3, PT4_PTCoor_DrvPosn_Stat_ST3, PT4_PTCoor_DrvPosn_Target_ST3, PT4_PTCoor_Gr_ST3, PT4_PTCoor_Gr_Target_ST3, PT4_PTCoor_ShW_MnTrctAxl_D_Allowed_ST3, PT4_PTCoor_ShW_MnTrctAxl_N_Allowed_ST3, PT4_PTCoor_ShW_MnTrctAxl_P_Allow_Drv_ST3, PT4_PTCoor_ShW_MnTrctAxl_P_Allowed_ST3, PT4_PTCoor_ShW_MnTrctAxl_R_Allowed_ST3, PT4_PTCoor_SSA_Standby_Stat_ST3, Rsrv1_PT4_PTCoor_DrvPosn_Gear_Pr5_ST3, SQC_PT4_PTCoor_DrvPosn_Gear_Pr5_ST3]
    system-signal-group=PT4_PTCoor_DrvPosn_Gear_Pr5_ST3_5p8cvrni3ypvuac33rj2asfy9
    end-to-end-transformation-i-signal-props{transformer=E2E_Profile_5, data-ids=234, data-length=64}
package /ISignalGroups/BODY3/PKG_BODY3/ROE_RBTM_FL_ST3
  i signal group ROE_RBTM_FL_ST3_6e0rxnifai2txra0wamb18g4m: i-signal=[ROE_0_RBTM_FL_ST3, ROE_1_RBTM_FL_ST3, ROE_2_RBTM_FL_ST3, ROE_3_RBTM_FL_ST3, ROE_4_RBTM_FL_ST3, ROE_5_RBTM_FL_ST3, ROE_6_RBTM_FL_ST3, ROE_7_RBTM_FL_ST3], system-signal-group=ROE_RBTM_FL_ST3_6e0rxnifai2txra0wamb18g4m  # Ereignis-Antwort (degraded) / Response on Event (degraded)
package /ISignalGroups/BODY3/PKG_BODY3/SBeltTens_SP_Lvl_ST3
  i signal group SBeltTens_SP_Lvl_Pr5_ST3_4tqpkri37441o5ht9g9ekmyzh: com-based-signal-group-transformations=BaseTrans_Profile_5_5, i-signal=[CRC_SBeltTens_SP_Lvl_Pr5_ST3, RBTMFL_SP_Lvl_Rq_ST35, RBTMFR_SP_Lvl_Rq_ST35, Rsrv0_SBeltTens_SP_Lvl_Pr5_ST3, SQC_SBeltTens_SP_Lvl_Pr5_ST3], system-signal-group=SBeltTens_SP_Lvl_Pr5_ST3_4tqpkri37441o5ht9g9ekmyzh, end-to-end-transformation-i-signal-props{transformer=E2E_Profile_5, data-ids=826, data-length=40}  # Seat Belt Tensioner SP Lvl ST3 (degraded)
package /ISignalGroups/BODY3/PKG_BODY3/VSS_TP_Auth_ST3
  i signal group VSS_TP_Auth_ST3_6j4id7sghlvlbroli4wjozjik: i-signal=[VSS_TP_Auth_0_ST3, VSS_TP_Auth_1_ST3, VSS_TP_Auth_2_ST3, VSS_TP_Auth_3_ST3, VSS_TP_Auth_4_ST3, VSS_TP_Auth_5_ST3, VSS_TP_Auth_6_ST3, VSS_TP_Auth_7_ST3], system-signal-group=VSS_TP_Auth_ST3_6j4id7sghlvlbroli4wjozjik  # VSS-Transportprotokoll für Authentifizierung (degraded) / Vehicle Security System Transport Protocol for authentication broadcast (degraded)
package /ISignalGroups/BODY3/PKG_BODY3/VSS_TP_RealTmOffset_ST3
  i signal group VSS_TP_RealTmOffset_ST3_1t7vc44gftc0wv35k5kgc2in9: i-signal=[VSS_TP_RealTmOffset_0_ST3, VSS_TP_RealTmOffset_1_ST3, VSS_TP_RealTmOffset_2_ST3, VSS_TP_RealTmOffset_3_ST3, VSS_TP_RealTmOffset_4_ST3, VSS_TP_RealTmOffset_5_ST3, VSS_TP_RealTmOffset_6_ST3, VSS_TP_RealTmOffset_7_ST3], system-signal-group=VSS_TP_RealTmOffset_ST3_1t7vc44gftc0wv35k5kgc2in9  # VSS-Transportprotokoll für Echtzeit-Offset (degraded) / Vehicle Security System Transport Protocol for real time offset broadcast (degraded)
package /ISignalGroups/BODY3/PKG_BODY3/VSS_TP_SecTickCount_Lvl2_ST3
  i signal group VSS_TP_SecTickCount_Lvl2_ST3_9eubq13iosat764o0lqh5xb6r: i-signal=[VSS_TP_SecTickCount_Lvl2_0_ST3, VSS_TP_SecTickCount_Lvl2_1_ST3, VSS_TP_SecTickCount_Lvl2_2_ST3, VSS_TP_SecTickCount_Lvl2_3_ST3, VSS_TP_SecTickCount_Lvl2_4_ST3, VSS_TP_SecTickCount_Lvl2_5_ST3, VSS_TP_SecTickCount_Lvl2_6_ST3, VSS_TP_SecTickCount_Lvl2_7_ST3], system-signal-group=VSS_TP_SecTickCount_Lvl2_ST3_9eubq13iosat764o0lqh5xb6r  # VSS-Transportprotokoll für sichere Zeit Stufe 2 (degraded) / Vehicle Security System Transport Protocol for secure tick count level #2 (degraded)
package /ISignalGroups/BODY3/PKG_BODY3/VSS_TP_SharedSecret_ST3
  i signal group VSS_TP_SharedSecret_ST3_8pj4t8t4rm3tw3pk5hj7vonti: i-signal=[VSS_TP_SharedSecret_0_ST3, VSS_TP_SharedSecret_1_ST3, VSS_TP_SharedSecret_2_ST3, VSS_TP_SharedSecret_3_ST3, VSS_TP_SharedSecret_4_ST3, VSS_TP_SharedSecret_5_ST3, VSS_TP_SharedSecret_6_ST3, VSS_TP_SharedSecret_7_ST3], system-signal-group=VSS_TP_SharedSecret_ST3_8pj4t8t4rm3tw3pk5hj7vonti  # VSS-Transportprotokoll für gemeinsames Geheimnis (degraded) / Vehicle Security System Transport Protocol for shared secret broadcast (degraded)
package /ISignalGroups/BODY3/PKG_BODY3/VSS_TP_VIN_ST3
  i signal group VSS_TP_VIN_ST3_bz1xsv84cxzl09j028gn39p69: i-signal=[VSS_TP_VIN_0_ST3, VSS_TP_VIN_1_ST3, VSS_TP_VIN_2_ST3, VSS_TP_VIN_3_ST3, VSS_TP_VIN_4_ST3, VSS_TP_VIN_5_ST3, VSS_TP_VIN_6_ST3, VSS_TP_VIN_7_ST3], system-signal-group=VSS_TP_VIN_ST3_bz1xsv84cxzl09j028gn39p69  # VSS-Transportprotokoll für Fahrzeugidentifikationsnummer (degraded) / Vehicle Security System Transport Protocol for Vehicle Identification Number (degraded)
package /ISignalGroups/BODY3/PKG_BODY3/ADAS_PREDICTION_ST3
  i signal group ADAS_Meta_ST3_40sly585w5zu8pqjwib3nr7y7_6: i-signal=[ADAS_Meta_MapVerYear_ST36, ADAS_Meta_HwVer_ST36, ADAS_Meta_MapVerQuar_ST36, ADAS_Meta_MapProvid_ST36, ADAS_Meta_CountryCode_ST36, ADAS_Meta_DrvSide_ST36, ADAS_Meta_SpdUnits_ST36, ADAS_Meta_ProtVer_Major_ST36, ADAS_Meta_ProtVer_Minor_ST36, ADAS_Meta_CycCnt_ST36, ADAS_Meta_ProtVer_MinorSub_ST36, ADAS_Meta_RegionCode_ST36], system-signal-group=ADAS_Meta_ST3_40sly585w5zu8pqjwib3nr7y7  # ADAS Metadaten (degraded) / ADAS meta data (degraded)
package /ISignalGroups/BODY3/PKG_BODY3/ADAS_PROFILE_SHORT_ST3
  i signal group ADAS_Profile_Short_CurvLn_ST3_96e9ejcafisp13h7moqj5malh_1: i-signal=[ADAS_ProfShort_Value0_CL_ST31, ADAS_ProfShort_AccurClass_CL_ST31, ADAS_ProfShort_CycCnt_CL_ST31, ADAS_ProfShort_Dist1_CL_ST31, ADAS_ProfShort_Updt_CL_ST31, ADAS_ProfShort_Value1_CL_ST31, ADAS_ProfShort_Offset_CL_ST31, ADAS_ProfShort_CtrlPoint_CL_ST31, ADAS_ProfShort_ReTr_CL_ST31, ADAS_ProfShort_PathIdx_CL_ST31, ADAS_ProfShort_MsgTyp_CL_ST31], system-signal-group=ADAS_Profile_Short_CurvLn_ST3_96e9ejcafisp13h7moqj5malh  # ADAS Kurzcharakteristik Curvature Linear (degraded) / ADAS short profile Curvature Linear (degraded)
package /ISignalGroups/BODY3/PKG_BODY3/Develop8_Rq_RBTM_FR_ST3
  i signal group Develop8_Rq_RBTM_FR_ST3_bcqj2sqez8u9spf5qxmu4a35u: i-signal=[Develop_Rq_RBTM_FR_01_ST3, Develop_Rq_RBTM_FR_02_ST3, Develop_Rq_RBTM_FR_03_ST3, Develop_Rq_RBTM_FR_04_ST3, Develop_Rq_RBTM_FR_05_ST3, Develop_Rq_RBTM_FR_06_ST3, Develop_Rq_RBTM_FR_07_ST3, Develop_Rq_RBTM_FR_08_ST3], system-signal-group=Develop8_Rq_RBTM_FR_ST3_bcqj2sqez8u9spf5qxmu4a35u  # Development Request (degraded)
package /ISignalGroups/BODY3/PKG_BODY3/Develop8_Rs_RBTM_FR_ST3
  i signal group Develop8_Rs_RBTM_FR_ST3_5t18pq0a13t698v0vsj7yvmmm: i-signal=[Develop_Rs_RBTM_FR_01_ST3, Develop_Rs_RBTM_FR_02_ST3, Develop_Rs_RBTM_FR_03_ST3, Develop_Rs_RBTM_FR_04_ST3, Develop_Rs_RBTM_FR_05_ST3, Develop_Rs_RBTM_FR_06_ST3, Develop_Rs_RBTM_FR_07_ST3, Develop_Rs_RBTM_FR_08_ST3], system-signal-group=Develop8_Rs_RBTM_FR_ST3_5t18pq0a13t698v0vsj7yvmmm  # Development Response (degraded)
package /ISignalGroups/BODY3/PKG_BODY3/Meas8_RBTM_FR_ST3
  i signal group Meas8_RBTM_FR_ST3_7ba3lhjy9fnhufd3n9dyw0p9p: i-signal=[Meas_RBTM_FR_01_ST3, Meas_RBTM_FR_02_ST3, Meas_RBTM_FR_03_ST3, Meas_RBTM_FR_04_ST3, Meas_RBTM_FR_05_ST3, Meas_RBTM_FR_06_ST3, Meas_RBTM_FR_07_ST3, Meas_RBTM_FR_08_ST3], system-signal-group=Meas8_RBTM_FR_ST3_7ba3lhjy9fnhufd3n9dyw0p9p  # Messbotschaft (degraded) / Measurement (degraded)
package /ISignalGroups/BODY3/PKG_BODY3/ROE_RBTM_FR_ST3
  i signal group ROE_RBTM_FR_ST3_3f1btonh6ivdn6ytgyuu9rtt1: i-signal=[ROE_0_RBTM_FR_ST3, ROE_1_RBTM_FR_ST3, ROE_2_RBTM_FR_ST3, ROE_3_RBTM_FR_ST3, ROE_4_RBTM_FR_ST3, ROE_5_RBTM_FR_ST3, ROE_6_RBTM_FR_ST3, ROE_7_RBTM_FR_ST3], system-signal-group=ROE_RBTM_FR_ST3_3f1btonh6ivdn6ytgyuu9rtt1  # Ereignis-Antwort (degraded) / Response on Event (degraded)
package /SecureCommunicationPropsSet
  secure communication props set XDIS_singleton_SecCommPropsSet
    secure communication authentication props SECOC_AP_CMAC_AES_128_24: auth-info-tx-length=24
    secure communication freshness props SECOC_FP_10000_40_8_true: freshness-timestamp-time-period-factor=10000, freshness-value-length=40, freshness-value-tx-length=8, use-freshness-timestamp=true
package /CommunicationClusters/BODY3
  can cluster BODY3: baudrate=250000, protocol-name=CAN, protocol-version=can2.0b
    can physical channel BODY3
      comm-connectors:
        {communication-connector=RBTM_FL_BODY3_8uqv9blm85ehm0msat385m76v, variation-point=post-build-variant-condition{matching-criterion=SideAllocation, value=0}}
        {communication-connector=RBTM_FR_BODY3_4xwwtd59665s787n6ctawh7k8, variation-point=post-build-variant-condition{matching-criterion=SideAllocation, value=1}}
      frame GTS_Main_CAN_ST3: id 0x79, to RBTM_FL, frame-length=8, variation-point=post-build-variant-condition{matching-criterion=SideAllocation, value=0}, can-addressing-mode=STANDARD  # Status Uhrsynchronisation / Clock synchronisation state
        carries pdu GTS_Main_CAN_ST3: packing-byte-order=big-endian, start-position=7
        general purpose pdu GTS_Main_CAN_ST3: category=GLOBAL_TIME, length=8  # Status Uhrsynchronisation / Clock synchronisation state
      frame Ign_Stat_ST3: id 0x7F, to RBTM_FL, frame-length=8, variation-point=post-build-variant-condition{matching-criterion=SideAllocation, value=0}, can-addressing-mode=STANDARD  # Zuendungsstatus / Ignition state
        secured i pdu Ign_Stat_ST3_secured: length=8, authentication-props=SECOC_AP_CMAC_AES_128_24, freshness-props=SECOC_FP_10000_40_8_true, payload=BODY3/Ign_Stat_ST3_c09z9xhxqu9sge34n30m1bi02, secure-communication-props={authentication-retries=0, data-id=28212, freshness-value-id=1}
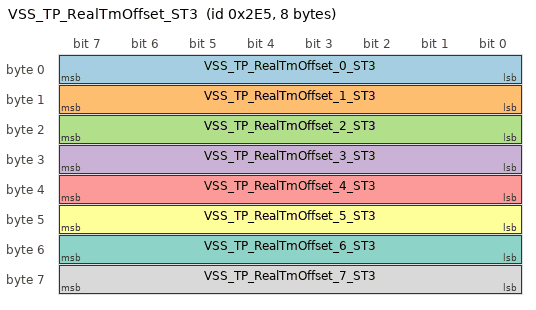
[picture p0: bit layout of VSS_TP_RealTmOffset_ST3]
      frame VSS_TP_RealTmOffset_ST3: id 0x2E5, to RBTM_FL, frame-length=8, variation-point=post-build-variant-condition{matching-criterion=SideAllocation, value=0}, can-addressing-mode=STANDARD  # VSS-Transportprotokoll für Echtzeit-Offset / Vehicle Security System Transport Protocol for real time offset broadcast
        pdu VSS_TP_RealTmOffset_ST3: length=8, minimum-delay=0.02, transmission-mode-true-timing=event-controlled-timing=number-of-repetitions=0, unused-bit-pattern=255  # VSS-Transportprotokoll für Echtzeit-Offset / Vehicle Security System Transport Protocol for real time offset broadcast
          signal VSS_TP_RealTmOffset_0_ST3: start 0, 8 bit, little-endian, data-type-policy=OVERRIDE, i-signal-type=PRIMITIVE, init-value=255, base-type=uint8, data-constr=c08_UInt_SNA_na, to RBTM_FL  # VSS-Transportprotokoll für Echtzeit-Offset, Byte 0 / Vehicle Security System Transport Protocol for real time offset broadcast, Byte 0
          signal VSS_TP_RealTmOffset_1_ST3: start 8, 8 bit, little-endian, data-type-policy=OVERRIDE, i-signal-type=PRIMITIVE, init-value=255, base-type=uint8, data-constr=c08_UInt_SNA_na, to RBTM_FL  # VSS-Transportprotokoll für Echtzeit-Offset, Byte 1 / Vehicle Security System Transport Protocol for real time offset broadcast, Byte 1
          signal VSS_TP_RealTmOffset_2_ST3: start 16, 8 bit, little-endian, data-type-policy=OVERRIDE, i-signal-type=PRIMITIVE, init-value=255, base-type=uint8, data-constr=c08_UInt_SNA_na, to RBTM_FL  # VSS-Transportprotokoll für Echtzeit-Offset, Byte 2 / Vehicle Security System Transport Protocol for real time offset broadcast, Byte 2
          signal VSS_TP_RealTmOffset_3_ST3: start 24, 8 bit, little-endian, data-type-policy=OVERRIDE, i-signal-type=PRIMITIVE, init-value=255, base-type=uint8, data-constr=c08_UInt_SNA_na, to RBTM_FL  # VSS-Transportprotokoll für Echtzeit-Offset, Byte 3 / Vehicle Security System Transport Protocol for real time offset broadcast, Byte 3
          signal VSS_TP_RealTmOffset_4_ST3: start 32, 8 bit, little-endian, data-type-policy=OVERRIDE, i-signal-type=PRIMITIVE, init-value=255, base-type=uint8, data-constr=c08_UInt_SNA_na, to RBTM_FL  # VSS-Transportprotokoll für Echtzeit-Offset, Byte 4 / Vehicle Security System Transport Protocol for real time offset broadcast, Byte 4
          signal VSS_TP_RealTmOffset_5_ST3: start 40, 8 bit, little-endian, data-type-policy=OVERRIDE, i-signal-type=PRIMITIVE, init-value=255, base-type=uint8, data-constr=c08_UInt_SNA_na, to RBTM_FL  # VSS-Transportprotokoll für Echtzeit-Offset, Byte 5 / Vehicle Security System Transport Protocol for real time offset broadcast, Byte 5
          signal VSS_TP_RealTmOffset_6_ST3: start 48, 8 bit, little-endian, data-type-policy=OVERRIDE, i-signal-type=PRIMITIVE, init-value=255, base-type=uint8, data-constr=c08_UInt_SNA_na, to RBTM_FL  # VSS-Transportprotokoll für Echtzeit-Offset, Byte 6 / Vehicle Security System Transport Protocol for real time offset broadcast, Byte 6
          signal VSS_TP_RealTmOffset_7_ST3: start 56, 8 bit, little-endian, data-type-policy=OVERRIDE, i-signal-type=PRIMITIVE, init-value=255, base-type=uint8, data-constr=c08_UInt_SNA_na, to RBTM_FL  # VSS-Transportprotokoll für Echtzeit-Offset, Byte 7 / Vehicle Security System Transport Protocol for real time offset broadcast, Byte 7
          mapping VSS_TP_RealTmOffset_ST3_1t7vc44gftc0wv35k5kgc2in9: i-signal-group=VSS_TP_RealTmOffset_ST3_1t7vc44gftc0wv35k5kgc2in9, packing-byte-order=little-endian, transfer-property=TRIGGERED
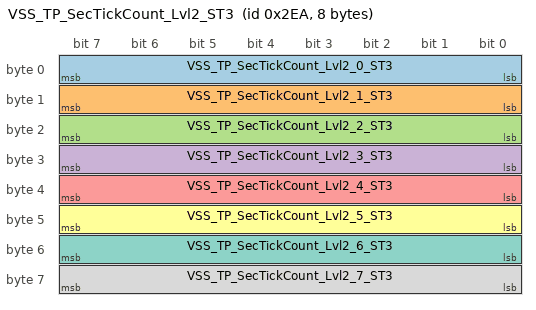
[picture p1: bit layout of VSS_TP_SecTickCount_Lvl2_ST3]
      frame VSS_TP_SecTickCount_Lvl2_ST3: id 0x2EA, to RBTM_FL, frame-length=8, variation-point=post-build-variant-condition{matching-criterion=SideAllocation, value=0}, can-addressing-mode=STANDARD  # VSS-Transportprotokoll für sichere Zeit Stufe 2 / Vehicle Security System Transport Protocol for secure tick count level #2
        pdu VSS_TP_SecTickCount_Lvl2_ST3: length=8, minimum-delay=0.02, transmission-mode-true-timing=event-controlled-timing=number-of-repetitions=0, unused-bit-pattern=255  # VSS-Transportprotokoll für sichere Zeit Stufe 2 / Vehicle Security System Transport Protocol for secure tick count level #2
          signal VSS_TP_SecTickCount_Lvl2_0_ST3: start 0, 8 bit, little-endian, data-type-policy=OVERRIDE, i-signal-type=PRIMITIVE, init-value=255, base-type=uint8, data-constr=c08_UInt_SNA_na, to RBTM_FL  # VSS-Transportprotokoll für sichere Zeit Stufe 2, Byte 0 / Vehicle Security System Transport Protocol for secure tick count level #2, Byte 0
          signal VSS_TP_SecTickCount_Lvl2_1_ST3: start 8, 8 bit, little-endian, data-type-policy=OVERRIDE, i-signal-type=PRIMITIVE, init-value=255, base-type=uint8, data-constr=c08_UInt_SNA_na, to RBTM_FL  # VSS-Transportprotokoll für sichere Zeit Stufe 2, Byte 1 / Vehicle Security System Transport Protocol for secure tick count level #2, Byte 1
          signal VSS_TP_SecTickCount_Lvl2_2_ST3: start 16, 8 bit, little-endian, data-type-policy=OVERRIDE, i-signal-type=PRIMITIVE, init-value=255, base-type=uint8, data-constr=c08_UInt_SNA_na, to RBTM_FL  # VSS-Transportprotokoll für sichere Zeit Stufe 2, Byte 2 / Vehicle Security System Transport Protocol for secure tick count level #2, Byte 2
          signal VSS_TP_SecTickCount_Lvl2_3_ST3: start 24, 8 bit, little-endian, data-type-policy=OVERRIDE, i-signal-type=PRIMITIVE, init-value=255, base-type=uint8, data-constr=c08_UInt_SNA_na, to RBTM_FL  # VSS-Transportprotokoll für sichere Zeit Stufe 2, Byte 3 / Vehicle Security System Transport Protocol for secure tick count level #2, Byte 3
          signal VSS_TP_SecTickCount_Lvl2_4_ST3: start 32, 8 bit, little-endian, data-type-policy=OVERRIDE, i-signal-type=PRIMITIVE, init-value=255, base-type=uint8, data-constr=c08_UInt_SNA_na, to RBTM_FL  # VSS-Transportprotokoll für sichere Zeit Stufe 2, Byte 4 / Vehicle Security System Transport Protocol for secure tick count level #2, Byte 4
          signal VSS_TP_SecTickCount_Lvl2_5_ST3: start 40, 8 bit, little-endian, data-type-policy=OVERRIDE, i-signal-type=PRIMITIVE, init-value=255, base-type=uint8, data-constr=c08_UInt_SNA_na, to RBTM_FL  # VSS-Transportprotokoll für sichere Zeit Stufe 2, Byte 5 / Vehicle Security System Transport Protocol for secure tick count level #2, Byte 5
          signal VSS_TP_SecTickCount_Lvl2_6_ST3: start 48, 8 bit, little-endian, data-type-policy=OVERRIDE, i-signal-type=PRIMITIVE, init-value=255, base-type=uint8, data-constr=c08_UInt_SNA_na, to RBTM_FL  # VSS-Transportprotokoll für sichere Zeit Stufe 2, Byte 6 / Vehicle Security System Transport Protocol for secure tick count level #2, Byte 6
          signal VSS_TP_SecTickCount_Lvl2_7_ST3: start 56, 8 bit, little-endian, data-type-policy=OVERRIDE, i-signal-type=PRIMITIVE, init-value=255, base-type=uint8, data-constr=c08_UInt_SNA_na, to RBTM_FL  # VSS-Transportprotokoll für sichere Zeit Stufe 2, Byte 7 / Vehicle Security System Transport Protocol for secure tick count level #2, Byte 7
          mapping VSS_TP_SecTickCount_Lvl2_ST3_9eubq13iosat764o0lqh5xb6r: i-signal-group=VSS_TP_SecTickCount_Lvl2_ST3_9eubq13iosat764o0lqh5xb6r, packing-byte-order=little-endian, transfer-property=TRIGGERED
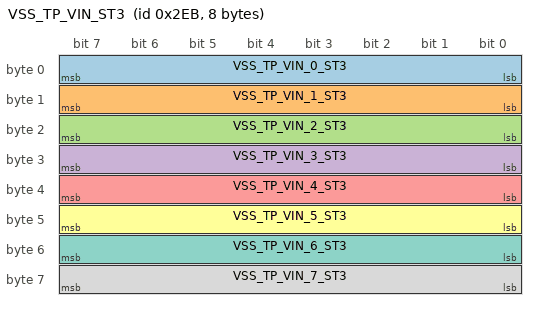
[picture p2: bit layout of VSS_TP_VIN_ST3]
      frame VSS_TP_VIN_ST3: id 0x2EB, to RBTM_FL, frame-length=8, variation-point=post-build-variant-condition{matching-criterion=SideAllocation, value=0}, can-addressing-mode=STANDARD  # VSS-Transportprotokoll für Fahrzeugidentifikationsnummer / Vehicle Security System Transport Protocol for Vehicle Identification Number
        pdu VSS_TP_VIN_ST3: length=8, minimum-delay=0.02, transmission-mode-true-timing=event-controlled-timing=number-of-repetitions=0, unused-bit-pattern=255  # VSS-Transportprotokoll für Fahrzeugidentifikationsnummer / Vehicle Security System Transport Protocol for Vehicle Identification Number
          signal VSS_TP_VIN_0_ST3: start 0, 8 bit, little-endian, data-type-policy=OVERRIDE, i-signal-type=PRIMITIVE, init-value=63, base-type=uint8, data-constr=c08_UInt_SNA_na, to RBTM_FL  # VSS-Transportprotokoll für Fahrzeugidentifikationsnummer, Byte 0 / Vehicle Security System Transport Protocol for Vehicle Identification Number, Byte 0
          signal VSS_TP_VIN_1_ST3: start 8, 8 bit, little-endian, data-type-policy=OVERRIDE, i-signal-type=PRIMITIVE, init-value=63, base-type=uint8, data-constr=c08_UInt_SNA_na, to RBTM_FL  # VSS-Transportprotokoll für Fahrzeugidentifikationsnummer, Byte 1 / Vehicle Security System Transport Protocol for Vehicle Identification Number, Byte 1
          signal VSS_TP_VIN_2_ST3: start 16, 8 bit, little-endian, data-type-policy=OVERRIDE, i-signal-type=PRIMITIVE, init-value=63, base-type=uint8, data-constr=c08_UInt_SNA_na, to RBTM_FL  # VSS-Transportprotokoll für Fahrzeugidentifikationsnummer, Byte 2 / Vehicle Security System Transport Protocol for Vehicle Identification Number, Byte 2
          signal VSS_TP_VIN_3_ST3: start 24, 8 bit, little-endian, data-type-policy=OVERRIDE, i-signal-type=PRIMITIVE, init-value=63, base-type=uint8, data-constr=c08_UInt_SNA_na, to RBTM_FL  # VSS-Transportprotokoll für Fahrzeugidentifikationsnummer, Byte 3 / Vehicle Security System Transport Protocol for Vehicle Identification Number, Byte 3
          signal VSS_TP_VIN_4_ST3: start 32, 8 bit, little-endian, data-type-policy=OVERRIDE, i-signal-type=PRIMITIVE, init-value=63, base-type=uint8, data-constr=c08_UInt_SNA_na, to RBTM_FL  # VSS-Transportprotokoll für Fahrzeugidentifikationsnummer, Byte 4 / Vehicle Security System Transport Protocol for Vehicle Identification Number, Byte 4
          signal VSS_TP_VIN_5_ST3: start 40, 8 bit, little-endian, data-type-policy=OVERRIDE, i-signal-type=PRIMITIVE, init-value=63, base-type=uint8, data-constr=c08_UInt_SNA_na, to RBTM_FL  # VSS-Transportprotokoll für Fahrzeugidentifikationsnummer, Byte 5 / Vehicle Security System Transport Protocol for Vehicle Identification Number, Byte 5
          signal VSS_TP_VIN_6_ST3: start 48, 8 bit, little-endian, data-type-policy=OVERRIDE, i-signal-type=PRIMITIVE, init-value=63, base-type=uint8, data-constr=c08_UInt_SNA_na, to RBTM_FL  # VSS-Transportprotokoll für Fahrzeugidentifikationsnummer, Byte 6 / Vehicle Security System Transport Protocol for Vehicle Identification Number, Byte 6
          signal VSS_TP_VIN_7_ST3: start 56, 8 bit, little-endian, data-type-policy=OVERRIDE, i-signal-type=PRIMITIVE, init-value=63, base-type=uint8, data-constr=c08_UInt_SNA_na, to RBTM_FL  # VSS-Transportprotokoll für Fahrzeugidentifikationsnummer, Byte 7 / Vehicle Security System Transport Protocol for Vehicle Identification Number, Byte 7
          mapping VSS_TP_VIN_ST3_bz1xsv84cxzl09j028gn39p69: i-signal-group=VSS_TP_VIN_ST3_bz1xsv84cxzl09j028gn39p69, packing-byte-order=little-endian, transfer-property=TRIGGERED
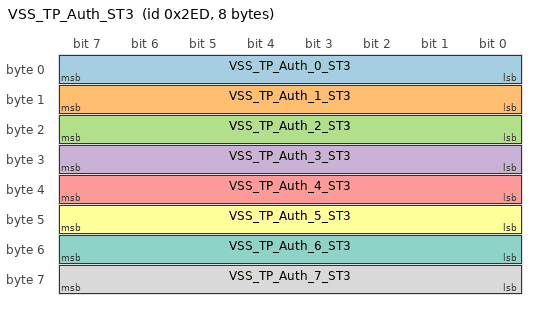
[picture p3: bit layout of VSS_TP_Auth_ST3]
      frame VSS_TP_Auth_ST3: id 0x2ED, to RBTM_FL, frame-length=8, variation-point=post-build-variant-condition{matching-criterion=SideAllocation, value=0}, can-addressing-mode=STANDARD  # VSS-Transportprotokoll für Authentifizierung / Vehicle Security System Transport Protocol for authentication broadcast
        pdu VSS_TP_Auth_ST3: length=8, minimum-delay=0.02, transmission-mode-true-timing=event-controlled-timing=number-of-repetitions=0, unused-bit-pattern=255  # VSS-Transportprotokoll für Authentifizierung / Vehicle Security System Transport Protocol for authentication broadcast
          signal VSS_TP_Auth_0_ST3: start 0, 8 bit, little-endian, data-type-policy=OVERRIDE, i-signal-type=PRIMITIVE, init-value=255, base-type=uint8, data-constr=c08_UInt_SNA_na, to RBTM_FL  # VSS-Transportprotokoll für Authentifizierung, Byte 0 / Vehicle Security System Transport Protocol for authentication broadcast, Byte 0
          signal VSS_TP_Auth_1_ST3: start 8, 8 bit, little-endian, data-type-policy=OVERRIDE, i-signal-type=PRIMITIVE, init-value=255, base-type=uint8, data-constr=c08_UInt_SNA_na, to RBTM_FL  # VSS-Transportprotokoll für Authentifizierung, Byte 1 / Vehicle Security System Transport Protocol for authentication broadcast, Byte 1
          signal VSS_TP_Auth_2_ST3: start 16, 8 bit, little-endian, data-type-policy=OVERRIDE, i-signal-type=PRIMITIVE, init-value=255, base-type=uint8, data-constr=c08_UInt_SNA_na, to RBTM_FL  # VSS-Transportprotokoll für Authentifizierung, Byte 2 / Vehicle Security System Transport Protocol for authentication broadcast, Byte 2
          signal VSS_TP_Auth_3_ST3: start 24, 8 bit, little-endian, data-type-policy=OVERRIDE, i-signal-type=PRIMITIVE, init-value=255, base-type=uint8, data-constr=c08_UInt_SNA_na, to RBTM_FL  # VSS-Transportprotokoll für Authentifizierung, Byte 3 / Vehicle Security System Transport Protocol for authentication broadcast, Byte 3
          signal VSS_TP_Auth_4_ST3: start 32, 8 bit, little-endian, data-type-policy=OVERRIDE, i-signal-type=PRIMITIVE, init-value=255, base-type=uint8, data-constr=c08_UInt_SNA_na, to RBTM_FL  # VSS-Transportprotokoll für Authentifizierung, Byte 4 / Vehicle Security System Transport Protocol for authentication broadcast, Byte 4
          signal VSS_TP_Auth_5_ST3: start 40, 8 bit, little-endian, data-type-policy=OVERRIDE, i-signal-type=PRIMITIVE, init-value=255, base-type=uint8, data-constr=c08_UInt_SNA_na, to RBTM_FL  # VSS-Transportprotokoll für Authentifizierung, Byte 5 / Vehicle Security System Transport Protocol for authentication broadcast, Byte 5
          signal VSS_TP_Auth_6_ST3: start 48, 8 bit, little-endian, data-type-policy=OVERRIDE, i-signal-type=PRIMITIVE, init-value=255, base-type=uint8, data-constr=c08_UInt_SNA_na, to RBTM_FL  # VSS-Transportprotokoll für Authentifizierung, Byte 6 / Vehicle Security System Transport Protocol for authentication broadcast, Byte 6
          signal VSS_TP_Auth_7_ST3: start 56, 8 bit, little-endian, data-type-policy=OVERRIDE, i-signal-type=PRIMITIVE, init-value=255, base-type=uint8, data-constr=c08_UInt_SNA_na, to RBTM_FL  # VSS-Transportprotokoll für Authentifizierung, Byte 7 / Vehicle Security System Transport Protocol for authentication broadcast, Byte 7
          mapping VSS_TP_Auth_ST3_6j4id7sghlvlbroli4wjozjik: i-signal-group=VSS_TP_Auth_ST3_6j4id7sghlvlbroli4wjozjik, packing-byte-order=little-endian, transfer-property=TRIGGERED
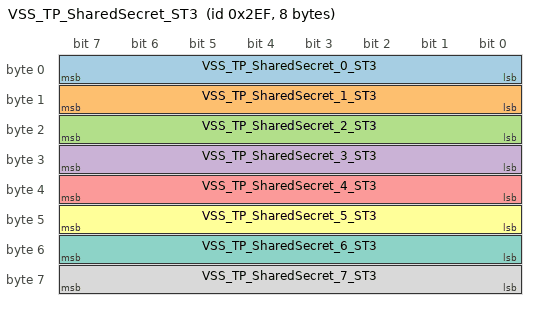
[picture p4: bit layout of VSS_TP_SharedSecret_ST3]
      frame VSS_TP_SharedSecret_ST3: id 0x2EF, to RBTM_FL, frame-length=8, variation-point=post-build-variant-condition{matching-criterion=SideAllocation, value=0}, can-addressing-mode=STANDARD  # VSS-Transportprotokoll für gemeinsames Geheimnis / Vehicle Security System Transport Protocol for shared secret broadcast
        pdu VSS_TP_SharedSecret_ST3: length=8, minimum-delay=0.02, transmission-mode-true-timing=event-controlled-timing=number-of-repetitions=0, unused-bit-pattern=255  # VSS-Transportprotokoll für gemeinsames Geheimnis / Vehicle Security System Transport Protocol for shared secret broadcast
          signal VSS_TP_SharedSecret_0_ST3: start 0, 8 bit, little-endian, data-type-policy=OVERRIDE, i-signal-type=PRIMITIVE, init-value=255, base-type=uint8, data-constr=c08_UInt_SNA_na, to RBTM_FL  # VSS-Transportprotokoll für gemeinsames Geheimnis, Byte 0 / Vehicle Security System Transport Protocol for shared secret broadcast, Byte 0
          signal VSS_TP_SharedSecret_1_ST3: start 8, 8 bit, little-endian, data-type-policy=OVERRIDE, i-signal-type=PRIMITIVE, init-value=255, base-type=uint8, data-constr=c08_UInt_SNA_na, to RBTM_FL  # VSS-Transportprotokoll für gemeinsames Geheimnis, Byte 1 / Vehicle Security System Transport Protocol for shared secret broadcast, Byte 1
          signal VSS_TP_SharedSecret_2_ST3: start 16, 8 bit, little-endian, data-type-policy=OVERRIDE, i-signal-type=PRIMITIVE, init-value=255, base-type=uint8, data-constr=c08_UInt_SNA_na, to RBTM_FL  # VSS-Transportprotokoll für gemeinsames Geheimnis, Byte 2 / Vehicle Security System Transport Protocol for shared secret broadcast, Byte 2
          signal VSS_TP_SharedSecret_3_ST3: start 24, 8 bit, little-endian, data-type-policy=OVERRIDE, i-signal-type=PRIMITIVE, init-value=255, base-type=uint8, data-constr=c08_UInt_SNA_na, to RBTM_FL  # VSS-Transportprotokoll für gemeinsames Geheimnis, Byte 3 / Vehicle Security System Transport Protocol for shared secret broadcast, Byte 3
          signal VSS_TP_SharedSecret_4_ST3: start 32, 8 bit, little-endian, data-type-policy=OVERRIDE, i-signal-type=PRIMITIVE, init-value=255, base-type=uint8, data-constr=c08_UInt_SNA_na, to RBTM_FL  # VSS-Transportprotokoll für gemeinsames Geheimnis, Byte 4 / Vehicle Security System Transport Protocol for shared secret broadcast, Byte 4
          signal VSS_TP_SharedSecret_5_ST3: start 40, 8 bit, little-endian, data-type-policy=OVERRIDE, i-signal-type=PRIMITIVE, init-value=255, base-type=uint8, data-constr=c08_UInt_SNA_na, to RBTM_FL  # VSS-Transportprotokoll für gemeinsames Geheimnis, Byte 5 / Vehicle Security System Transport Protocol for shared secret broadcast, Byte 5
          signal VSS_TP_SharedSecret_6_ST3: start 48, 8 bit, little-endian, data-type-policy=OVERRIDE, i-signal-type=PRIMITIVE, init-value=255, base-type=uint8, data-constr=c08_UInt_SNA_na, to RBTM_FL  # VSS-Transportprotokoll für gemeinsames Geheimnis, Byte 6 / Vehicle Security System Transport Protocol for shared secret broadcast, Byte 6
          signal VSS_TP_SharedSecret_7_ST3: start 56, 8 bit, little-endian, data-type-policy=OVERRIDE, i-signal-type=PRIMITIVE, init-value=255, base-type=uint8, data-constr=c08_UInt_SNA_na, to RBTM_FL  # VSS-Transportprotokoll für gemeinsames Geheimnis, Byte 7 / Vehicle Security System Transport Protocol for shared secret broadcast, Byte 7
          mapping VSS_TP_SharedSecret_ST3_8pj4t8t4rm3tw3pk5hj7vonti: i-signal-group=VSS_TP_SharedSecret_ST3_8pj4t8t4rm3tw3pk5hj7vonti, packing-byte-order=little-endian, transfer-property=TRIGGERED
      frame PT4_PTCoor9_d1_BC_F_ST3: id 0x304, to RBTM_FL, frame-length=1, variation-point=post-build-variant-condition{matching-criterion=SideAllocation, value=0}, can-addressing-mode=STANDARD  # PT4 PT Coor 9 ST3 - Degraded PDU
        pdu PT4_PTCoor9_d1_BC_F_ST3: length=1, minimum-delay=0.02, transmission-mode-true-timing={cyclic-timing={time-offset=0.005, time-period=1}, event-controlled-timing=number-of-repetitions=0}, unused-bit-pattern=255  # PT4 PT Coor 9 ST3 - Degraded PDU
          signal PT4_PTCoor_Accel_Md_ST3: start 0, 3 bit, little-endian, data-type-policy=OVERRIDE, i-signal-type=PRIMITIVE, init-value=7, base-type=uint8, invalid-value=7, compu-method=c03_Accel_Md_ST3, data-constr=c03_Accel_Md_ST3, to RBTM_FL(timeout 5.1 s)  # Aktueller Beschleunigungsmodus(Nur in AMG Modellen verfügbar) / Acceleration Modes(Only provided in AMG models)
          mapping PT4_PTCoor9_Pr5_ST3_6r95o81sst3tk9w2lzz600cw3: i-signal-group=PT4_PTCoor9_Pr5_ST3_6r95o81sst3tk9w2lzz600cw3, packing-byte-order=little-endian, transfer-property=TRIGGERED-ON-CHANGE, update-indication-bit-position=7
      frame SBeltTens_SP_Lvl_ST3: id 0x30E, to RBTM_FL, frame-length=8, variation-point=post-build-variant-condition{matching-criterion=SideAllocation, value=0}, can-addressing-mode=STANDARD  # Seat Belt Tensioner SP Lvl ST3
        pdu SBeltTens_SP_Lvl_ST3: length=8, minimum-delay=0.02, transmission-mode-true-timing={cyclic-timing={time-offset=0.08, time-period=0.2}, event-controlled-timing=number-of-repetitions=0}, unused-bit-pattern=255  # Seat Belt Tensioner SP Lvl ST3
          signal CRC_SBeltTens_SP_Lvl_Pr5_ST3: start 0, 16 bit, little-endian, data-type-policy=OVERRIDE, i-signal-type=PRIMITIVE, init-value=10339, base-type=uint16, data-constr=c16_CRC_woSNA, transfer-property=PENDING, to RBTM_FL(timeout 2 s)  # CRC-Checksumme der Signal Gruppe gemäß AUTOSAR Profil 5 / CRC-checksum of signal group according to AUTOSAR Profile 5
          signal RBTMFL_SP_Lvl_Rq_ST35: start 24, 6 bit, little-endian, data-type-policy=OVERRIDE, i-signal-type=PRIMITIVE, init-value=0, base-type=uint8, invalid-value=63, compu-method=c06_RBTM_LVL_Rq, data-constr=c06_RBTM_LVL_Rq, transfer-property=TRIGGERED-ON-CHANGE, variation-point=post-build-variant-condition{matching-criterion=SideAllocation, value=0}, to RBTM_FL(timeout 2 s) RBTM_FL  # Straffprofil Anforderung durch Seatbelt Service Provider vorne links / Tensioning profile request from Seatbelt Service Provider front left
          signal SQC_SBeltTens_SP_Lvl_Pr5_ST3: start 16, 8 bit, little-endian, data-type-policy=OVERRIDE, i-signal-type=PRIMITIVE, init-value=0, base-type=uint8, compu-method=none_1_0, data-constr=c08_0_255_1_SNA_na, transfer-property=PENDING, to RBTM_FL(timeout 2 s)  # Sequenzzähler / Sequence counter
          signal RBTMFR_SP_Lvl_Rq_ST35: start 30, 6 bit, little-endian, data-type-policy=OVERRIDE, i-signal-type=PRIMITIVE, init-value=0, base-type=uint8, invalid-value=63, compu-method=c06_RBTM_LVL_Rq, data-constr=c06_RBTM_LVL_Rq, transfer-property=PENDING, variation-point=post-build-variant-condition{matching-criterion=SideAllocation, value=0}, to RBTM_FL RBTM_FL(timeout 2 s)  # Straffprofil Anforderung durch Seatbelt Service Provider vorne rechts / Tensioning profile request from Seatbelt Service Provider front right
          signal Rsrv0_SBeltTens_SP_Lvl_Pr5_ST3: start 36, 4 bit, little-endian, data-type-policy=OVERRIDE, i-signal-type=PRIMITIVE, init-value=15, base-type=uint8, invalid-value=15, data-constr=Rsrv04, transfer-property=PENDING, to RBTM_FL  # Reserviert für zukünftige Verwendung / Reserved for future use
          mapping SBeltTens_SP_Lvl_Pr5_ST3_4tqpkri37441o5ht9g9ekmyzh: i-signal-group=SBeltTens_SP_Lvl_Pr5_ST3_4tqpkri37441o5ht9g9ekmyzh, packing-byte-order=little-endian, transfer-property=TRIGGERED-ON-CHANGE
          signal RBTMFR_SP_Lvl_Rq_ST35: start 30, 6 bit, little-endian, data-type-policy=OVERRIDE, i-signal-type=PRIMITIVE, init-value=0, base-type=uint8, invalid-value=63, compu-method=c06_RBTM_LVL_Rq, data-constr=c06_RBTM_LVL_Rq, transfer-property=TRIGGERED-ON-CHANGE, variation-point=post-build-variant-condition{matching-criterion=SideAllocation, value=1}, to RBTM_FL RBTM_FL(timeout 2 s)  # Straffprofil Anforderung durch Seatbelt Service Provider vorne rechts / Tensioning profile request from Seatbelt Service Provider front right
          signal RBTMFL_SP_Lvl_Rq_ST35: start 24, 6 bit, little-endian, data-type-policy=OVERRIDE, i-signal-type=PRIMITIVE, init-value=0, base-type=uint8, invalid-value=63, compu-method=c06_RBTM_LVL_Rq, data-constr=c06_RBTM_LVL_Rq, transfer-property=PENDING, variation-point=post-build-variant-condition{matching-criterion=SideAllocation, value=1}, to RBTM_FL(timeout 2 s) RBTM_FL  # Straffprofil Anforderung durch Seatbelt Service Provider vorne links / Tensioning profile request from Seatbelt Service Provider front left
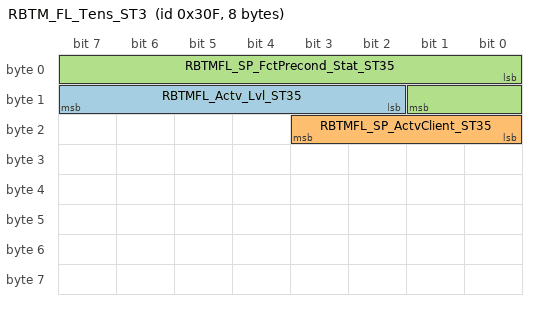
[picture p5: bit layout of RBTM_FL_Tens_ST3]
      frame RBTM_FL_Tens_ST3: id 0x30F, from RBTM_FL, frame-length=8, variation-point=post-build-variant-condition{matching-criterion=SideAllocation, value=0}, can-addressing-mode=STANDARD  # RBTM Vorne Links Tens ST3 / RBTM Front Left Tens ST3
        pdu RBTM_FL_Tens_ST3: length=8, minimum-delay=0.02, transmission-mode-true-timing={cyclic-timing={time-offset=0.005, time-period=0.5}, event-controlled-timing=number-of-repetitions=0}, unused-bit-pattern=255  # RBTM Vorne Links Tens ST3 / RBTM Front Left Tens ST3
          signal RBTMFL_Actv_Lvl_ST35: start 10, 6 bit, little-endian, data-type-policy=OVERRIDE, i-signal-type=PRIMITIVE, init-value=0, base-type=uint8, invalid-value=63, compu-method=c06_RBTM_Lvl_Stat, data-constr=c06_RBTM_Lvl_Stat, transfer-property=TRIGGERED-ON-CHANGE  # aktives Straffprofil vorne links / active seatbelt tensioning profile front left
          signal RBTMFL_SP_ActvClient_ST35: start 16, 4 bit, little-endian, data-type-policy=OVERRIDE, i-signal-type=PRIMITIVE, init-value=0, base-type=uint8, invalid-value=15, compu-method=c04_RBTM_ActvClient, data-constr=c04_RBTM_ActvClient, transfer-property=TRIGGERED-ON-CHANGE  # Anforderungsquelle aktive Gurtstraffung vorne links / Active seatbelt tensioning request source front left
          signal RBTMFL_SP_FctPrecond_Stat_ST35: start 0, 10 bit, little-endian, data-type-policy=OVERRIDE, i-signal-type=PRIMITIVE, init-value=0, base-type=uint16, compu-method=c10_RBTM_Fct_Precond, transfer-property=TRIGGERED-ON-CHANGE  # Nicht erfüllten Funktionsbedingungen für rev. Gurtstraffung vorne links / List of unfulfilled preconditions for rev. seatbelt tensioning front left
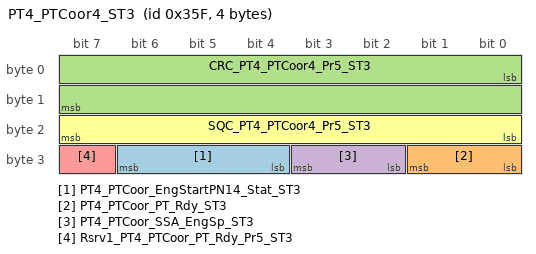
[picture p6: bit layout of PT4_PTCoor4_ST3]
      frame PT4_PTCoor4_ST3: id 0x35F, to RBTM_FL, frame-length=4, variation-point=post-build-variant-condition{matching-criterion=SideAllocation, value=0}, can-addressing-mode=STANDARD
        pdu PT4_PTCoor4_ST3: length=4, minimum-delay=0.01, transmission-mode-true-timing={cyclic-timing=time-period=0.1, event-controlled-timing=number-of-repetitions=0}, unused-bit-pattern=255
          signal PT4_PTCoor_EngStartPN14_Stat_ST3: start 28, 3 bit, little-endian, data-type-policy=OVERRIDE, i-signal-type=PRIMITIVE, init-value=0, base-type=uint8, invalid-value=7, compu-method=c03_EngStartPN14_Stat, data-constr=c03_EngStartPN14_Stat, to RBTM_FL(timeout 1.05 s)  # Status PN14 bei Motorstart / PT4 Engine Start PN14 State
          signal PT4_PTCoor_PT_Rdy_ST3: start 24, 2 bit, little-endian, data-type-policy=OVERRIDE, i-signal-type=PRIMITIVE, init-value=0, base-type=uint8, invalid-value=3, compu-method=c02_PT_Rdy_V2, data-constr=c02_PT_Rdy_V2, to RBTM_FL(timeout 1.05 s)  # Antrieb bereit / Powertrain ready
          signal CRC_PT4_PTCoor4_Pr5_ST3: start 0, 16 bit, little-endian, data-type-policy=OVERRIDE, i-signal-type=PRIMITIVE, init-value=4203, base-type=uint16, data-constr=c16_CRC_woSNA, transfer-property=PENDING  # CRC-Checksumme der Signal Gruppe gemäß AUTOSAR Profil 5 / CRC-checksum of signal group according to AUTOSAR Profile 5
          signal PT4_PTCoor_SSA_EngSp_ST3: start 26, 2 bit, little-endian, data-type-policy=OVERRIDE, i-signal-type=PRIMITIVE, init-value=3, base-type=uint8, invalid-value=3, compu-method=c02_Ndef_False_True_ST3, data-constr=c02_Ndef_False_True_ST3, transfer-property=PENDING  # ASS Motorstopp / Stop/start automatic has engine stopped
          signal Rsrv1_PT4_PTCoor_PT_Rdy_Pr5_ST3: start 31, 1 bit, little-endian, data-type-policy=OVERRIDE, i-signal-type=PRIMITIVE, init-value=1, base-type=uint8, invalid-value=1, data-constr=Rsrv01, transfer-property=PENDING  # Reserviert für zukünftige Verwendung / Reserved for future use
          signal SQC_PT4_PTCoor4_Pr5_ST3: start 16, 8 bit, little-endian, data-type-policy=OVERRIDE, i-signal-type=PRIMITIVE, init-value=0, base-type=uint8, compu-method=none_1_0, data-constr=c08_0_255_1_SNA_na, transfer-property=PENDING  # Sequenzzähler / Sequence counter
          mapping PT4_PTCoor4_Pr5_ST3_af4fxb1ykieox3itqdfzs0kpb: i-signal-group=PT4_PTCoor4_Pr5_ST3_af4fxb1ykieox3itqdfzs0kpb, packing-byte-order=little-endian, transfer-property=TRIGGERED-ON-CHANGE
      frame Impact2_ST3: id 0x463, to RBTM_FL, frame-length=8, variation-point=post-build-variant-condition{matching-criterion=SideAllocation, value=0}, can-addressing-mode=STANDARD  # ORC Impact 2 ST3
        secured i pdu Impact2_ST3_secured: length=8, authentication-props=SECOC_AP_CMAC_AES_128_24, freshness-props=SECOC_FP_10000_40_8_true, payload=BODY3/Impact2_ST3_tiwfvn1jg3r3k32jv8naa5uv, secure-communication-props={authentication-retries=0, data-id=27103, freshness-value-id=1}
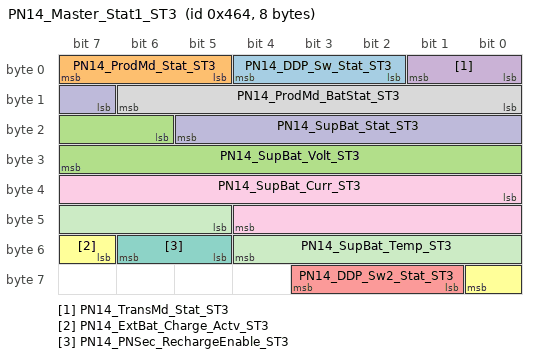
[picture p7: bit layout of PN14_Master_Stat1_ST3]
      frame PN14_Master_Stat1_ST3: id 0x464, to RBTM_FL, frame-length=8, variation-point=post-build-variant-condition{matching-criterion=SideAllocation, value=0}, can-addressing-mode=STANDARD  # Status 12V Bordnetz Master / Powernetwork 12V master state
        pdu PN14_Master_Stat1_ST3: length=8, transmission-mode-true-timing=cyclic-timing={time-offset=0, time-period=0.2}, unused-bit-pattern=255  # Status 12V Bordnetz Master / Powernetwork 12V master state
          signal PN14_DDP_Sw_Stat_ST3: start 2, 3 bit, little-endian, data-type-policy=OVERRIDE, i-signal-type=PRIMITIVE, init-value=0, base-type=uint8, invalid-value=7, compu-method=c03_PN14_TDP_Sw_Stat, data-constr=c03_PN14_TDP_Sw_Stat, transfer-property=PENDING, to RBTM_FL  # Schalterstatus Tiefentladeschutz / Deep discharge protection switch state
          signal PN14_ProdMd_Stat_ST3: start 5, 3 bit, little-endian, data-type-policy=OVERRIDE, i-signal-type=PRIMITIVE, init-value=7, base-type=uint8, invalid-value=7, compu-method=c03_PN14_ProdMd_Stat_ST3, data-constr=c03_PN14_ProdMd_Stat_ST3, transfer-property=PENDING, to RBTM_FL  # Status des Bordnetz Produktionsmodus / Powernet production mode state
          signal PN14_SupBat_Volt_ST3: start 22, 10 bit, little-endian, data-type-policy=OVERRIDE, i-signal-type=PRIMITIVE, init-value=1023, base-type=uint16, invalid-value=1023, compu-method=c10_V_0_25k55_0k025, data-constr=c10_V_0_25k55_0k025, transfer-property=PENDING, to RBTM_FL  # Versorgungsbatterie Istspannung / Supply battery voltage
          signal PN14_TransMd_Stat_ST3: start 0, 2 bit, little-endian, data-type-policy=OVERRIDE, i-signal-type=PRIMITIVE, init-value=3, base-type=uint8, invalid-value=3, compu-method=c02_TransMd_Stat, data-constr=c02_TransMd_Stat, transfer-property=PENDING, to RBTM_FL  # Bordnetz Status Transportmodus / Powernet transport mode status
          signal PN14_DDP_Sw2_Stat_ST3: start 57, 3 bit, little-endian, data-type-policy=OVERRIDE, i-signal-type=PRIMITIVE, init-value=7, base-type=uint8, invalid-value=7, compu-method=c03_PN14_TDP_Sw_Stat, data-constr=c03_PN14_TDP_Sw_Stat, transfer-property=PENDING  # Schalterstatus DDP Switch 2 (Always On Switch) / State of DDP Switch2 (Always On Switch)
          signal PN14_ExtBat_Charge_Actv_ST3: start 55, 2 bit, little-endian, data-type-policy=OVERRIDE, i-signal-type=PRIMITIVE, init-value=3, base-type=uint8, invalid-value=3, compu-method=c02_Ndef_False_True_ST3, data-constr=c02_Ndef_False_True_ST3, transfer-property=PENDING  # Externe Batterieladung erkannt / external barttery charging detected
          signal PN14_PNSec_RechargeEnable_ST3: start 53, 2 bit, little-endian, data-type-policy=OVERRIDE, i-signal-type=PRIMITIVE, init-value=3, base-type=uint8, invalid-value=3, compu-method=c02_Ndef_False_True_ST3, data-constr=c02_Ndef_False_True_ST3, transfer-property=PENDING  # Freigabe zum Nachladen der Sekundärbatterie / Enable for Recharge Secondary-Batterie
          signal PN14_ProdMd_BatStat_ST3: start 8, 7 bit, little-endian, data-type-policy=OVERRIDE, i-signal-type=PRIMITIVE, init-value=127, base-type=uint8, invalid-value=127, compu-method=c07_per_0to100_1_SNA, data-constr=c07_per_0to100_1_SNA, transfer-property=PENDING  # Der aktuelle Status der 12V Versorgungsbatterie während Produktions-Mode. / Actual 12V battery state during production mode
          signal PN14_SupBat_Curr_ST3: start 32, 13 bit, little-endian, data-type-policy=OVERRIDE, i-signal-type=PRIMITIVE, init-value=8191, base-type=uint16, invalid-value=8191, compu-method=c13_A_m409k6_409k4_0k1, data-constr=c13_A_m409k6_409k4_0k1, transfer-property=PENDING  # Versorgungsbatterie Iststrom / Supply battery current
          signal PN14_SupBat_Stat_ST3: start 15, 7 bit, little-endian, data-type-policy=OVERRIDE, i-signal-type=PRIMITIVE, init-value=127, base-type=uint8, invalid-value=127, compu-method=c07_0_111_1_SNA, data-constr=c07_0_111_1_SNA, transfer-property=PENDING  # Status Versorgungsbatterie / Supply battery state
          signal PN14_SupBat_Temp_ST3: start 45, 8 bit, little-endian, data-type-policy=OVERRIDE, i-signal-type=PRIMITIVE, init-value=255, base-type=uint8, invalid-value=255, compu-method=c08_degC_m40_85_0k5, data-constr=c08_degC_m40_85_0k5, transfer-property=PENDING  # Temperatur Versorgungsbatterie / Supply battery temperature
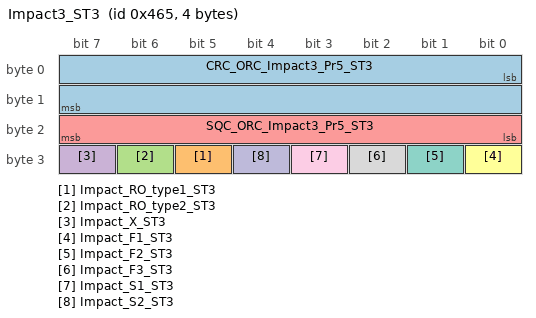
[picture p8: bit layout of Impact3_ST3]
      frame Impact3_ST3: id 0x465, to RBTM_FL, frame-length=4, variation-point=post-build-variant-condition{matching-criterion=SideAllocation, value=0}, can-addressing-mode=STANDARD  # ORC Impact 3 ST3
        pdu Impact3_ST3: length=4, minimum-delay=0.02, transmission-mode-false-timing=cyclic-timing=time-period=0.05, transmission-mode-true-timing=cyclic-timing=time-period=0.02, unused-bit-pattern=255  # ORC Impact 3 ST3
          transmission-mode-conditions:
            {data-filter={data-filter-type=MASKED-NEW-DIFFERS-X, mask=1, x=0}, i-signal-in-i-pdu=Impact_RO_type1_ST3}
            {data-filter={data-filter-type=MASKED-NEW-DIFFERS-X, mask=1, x=0}, i-signal-in-i-pdu=Impact_RO_type2_ST3}
            {data-filter={data-filter-type=MASKED-NEW-DIFFERS-X, mask=1, x=0}, i-signal-in-i-pdu=Impact_X_ST3}
          signal CRC_ORC_Impact3_Pr5_ST3: start 0, 16 bit, little-endian, data-type-policy=OVERRIDE, i-signal-type=PRIMITIVE, init-value=11251, base-type=uint16, data-constr=c16_CRC_woSNA, to RBTM_FL  # CRC-Checksumme der Signal Gruppe gemäß AUTOSAR Profil 5 / CRC-checksum of signal group according to AUTOSAR Profile 5
          signal Impact_RO_type1_ST3: start 29, 1 bit, little-endian, data-type-policy=OVERRIDE, i-signal-type=PRIMITIVE, init-value=0, base-type=boolean, to RBTM_FL  # Rollover mittels Drehratensensorik / rollover type 1
          signal Impact_RO_type2_ST3: start 30, 1 bit, little-endian, data-type-policy=OVERRIDE, i-signal-type=PRIMITIVE, init-value=0, base-type=boolean, to RBTM_FL  # Rollover mittels Beschleunigungssensorik / rollover type 2
          signal Impact_X_ST3: start 31, 1 bit, little-endian, data-type-policy=OVERRIDE, i-signal-type=PRIMITIVE, init-value=0, base-type=boolean, to RBTM_FL  # Beliebiges Crashereignis vorhanden / Any impact event
          signal SQC_ORC_Impact3_Pr5_ST3: start 16, 8 bit, little-endian, data-type-policy=OVERRIDE, i-signal-type=PRIMITIVE, init-value=0, base-type=uint8, compu-method=none_1_0, data-constr=c08_0_255_1_SNA_na, to RBTM_FL  # Sequenzzähler / Sequence counter
          signal Impact_F1_ST3: start 24, 1 bit, little-endian, data-type-policy=OVERRIDE, i-signal-type=PRIMITIVE, init-value=0, base-type=boolean, to RBTM_FL  # Frontalaufprall Stufe 1 / Collision front level 1
          signal Impact_F2_ST3: start 25, 1 bit, little-endian, data-type-policy=OVERRIDE, i-signal-type=PRIMITIVE, init-value=0, base-type=boolean, to RBTM_FL  # Frontalaufprall Stufe 2 / Collision front level 2
          signal Impact_F3_ST3: start 26, 1 bit, little-endian, data-type-policy=OVERRIDE, i-signal-type=PRIMITIVE, init-value=0, base-type=boolean, to RBTM_FL  # Frontalaufprall Stufe 3 / Collision front level 3
          signal Impact_S1_ST3: start 27, 1 bit, little-endian, data-type-policy=OVERRIDE, i-signal-type=PRIMITIVE, init-value=0, base-type=boolean, to RBTM_FL  # Seitenaufprall Stufe 1 / Collision side level 1
          signal Impact_S2_ST3: start 28, 1 bit, little-endian, data-type-policy=OVERRIDE, i-signal-type=PRIMITIVE, init-value=0, base-type=boolean, to RBTM_FL  # Seitenaufprall Stufe 2 / Collision side level 2
          mapping ORC_Impact3_Pr5_ST3_c4pqnkonfjwv3uiohsxhe9dwu: i-signal-group=ORC_Impact3_Pr5_ST3_c4pqnkonfjwv3uiohsxhe9dwu, packing-byte-order=little-endian, transfer-property=PENDING
      frame ADAS_PROFILE_SHORT_ST3: id 0x53D, to RBTM_FL, frame-length=8, variation-point=post-build-variant-condition{matching-criterion=SideAllocation, value=0}, can-addressing-mode=STANDARD
        multiplexed i pdu ADAS_PROFILE_SHORT_ST3:
          length=8
          dynamic-part{segment-position{segment-byte-order=little-endian, segment-length=64, segment-position=0}, dynamic-part-alternatives=[{i-pdu=ADAS_PROFILE_SHORT_ST3_1, initial-dynamic-part=false, selector-field-code=1}, {i-pdu=ADAS_PROFILE_SHORT_ST3_31, initial-dynamic-part=true, selector-field-code=31}]}
          selector-field-byte-order=little-endian
          selector-field-length=5
          selector-field-start-position=27
          trigger-mode=DYNAMIC-PART-TRIGGER
          unused-bit-pattern=255
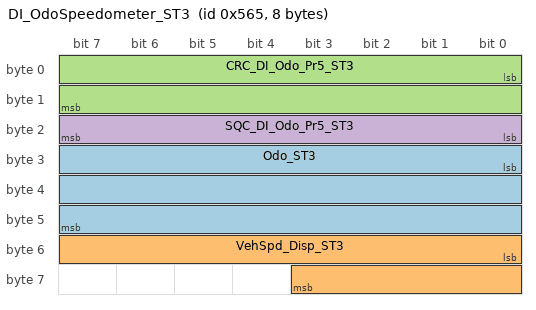
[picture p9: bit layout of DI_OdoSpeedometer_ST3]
      frame DI_OdoSpeedometer_ST3: id 0x565, to RBTM_FL, frame-length=8, variation-point=post-build-variant-condition{matching-criterion=SideAllocation, value=0}, can-addressing-mode=STANDARD  # Fahrerinformation Odometer und Tacho / DriverInformation Odometer and speedometer
        pdu DI_OdoSpeedometer_ST3: length=8, minimum-delay=0.1, transmission-mode-true-timing={cyclic-timing=time-period=1, event-controlled-timing=number-of-repetitions=0}, unused-bit-pattern=255  # Fahrerinformation Odometer und Tacho / DriverInformation Odometer and speedometer
          signal Odo_ST3: start 24, 24 bit, little-endian, data-type-policy=OVERRIDE, i-signal-type=PRIMITIVE, init-value=16777215, base-type=uint32, invalid-value=16777215, compu-method=c24_km_0_999999k9_0k1_Invld_SNA, data-constr=c24_km_0_999999k9_0k1_Invld_SNA, to RBTM_FL  # Kilometerstand (für alle) / Odometer (for everyone)
          signal VehSpd_Disp_ST3: start 48, 12 bit, little-endian, data-type-policy=OVERRIDE, i-signal-type=PRIMITIVE, init-value=4095, base-type=uint16, invalid-value=4095, compu-method=c12_km_p_h_0_409k4_0k1, data-constr=c12_km_p_h_0_409k4_0k1, transfer-property=TRIGGERED-ON-CHANGE, to RBTM_FL(timeout 10.5 s)  # Angezeigte Geschwindigkeit (ohne Zeigerdämpfung) / Displayed vehicle speed (without attenuation)
          signal CRC_DI_Odo_Pr5_ST3: start 0, 16 bit, little-endian, data-type-policy=OVERRIDE, i-signal-type=PRIMITIVE, init-value=8633, base-type=uint16, data-constr=c16_CRC_woSNA, transfer-property=PENDING  # CRC-Checksumme der Signal Gruppe gemäß AUTOSAR Profil 5 / CRC-checksum of signal group according to AUTOSAR Profile 5
          signal SQC_DI_Odo_Pr5_ST3: start 16, 8 bit, little-endian, data-type-policy=OVERRIDE, i-signal-type=PRIMITIVE, init-value=0, base-type=uint8, compu-method=none_1_0, data-constr=c08_0_255_1_SNA_na, transfer-property=PENDING  # Sequenzzähler / Sequence counter
          mapping DI_Odo_Pr5_ST3_e68xmtlkywxgxsdwekdjjhw3t: i-signal-group=DI_Odo_Pr5_ST3_e68xmtlkywxgxsdwekdjjhw3t, packing-byte-order=little-endian, transfer-property=TRIGGERED-ON-CHANGE, update-indication-bit-position=63
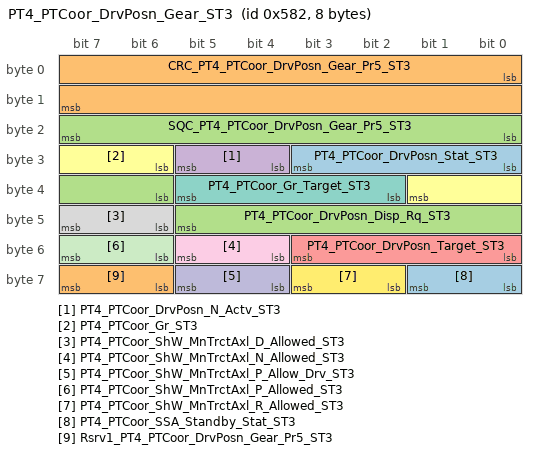
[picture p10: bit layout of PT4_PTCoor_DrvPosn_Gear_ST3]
      frame PT4_PTCoor_DrvPosn_Gear_ST3: id 0x582, to RBTM_FL, frame-length=8, variation-point=post-build-variant-condition{matching-criterion=SideAllocation, value=0}, can-addressing-mode=STANDARD  # PT4 PT Coor Drv Position Gear / PT4 PT Coor Drv position Gear
        pdu PT4_PTCoor_DrvPosn_Gear_ST3: length=8, minimum-delay=0.02, transmission-mode-true-timing={cyclic-timing={time-offset=0.03, time-period=0.1}, event-controlled-timing=number-of-repetitions=0}, unused-bit-pattern=255  # PT4 PT Coor Drv Position Gear ST3 / PT4 PT Coor Drv position Gear ST3
          signal PT4_PTCoor_DrvPosn_Stat_ST3: start 24, 4 bit, little-endian, data-type-policy=OVERRIDE, i-signal-type=PRIMITIVE, init-value=15, base-type=uint8, invalid-value=15, compu-method=c04_DrvPosn_ST3, data-constr=c04_DrvPosn_ST3, to RBTM_FL  # Powertrain Fahrstufe / Powertrain Driving Position
          signal CRC_PT4_PTCoor_DrvPosn_Gear_Pr5_ST3: start 0, 16 bit, little-endian, data-type-policy=OVERRIDE, i-signal-type=PRIMITIVE, init-value=47286, base-type=uint16, data-constr=c16_CRC_woSNA, transfer-property=PENDING  # CRC-Checksumme der Signal Gruppe gemäß AUTOSAR Profil 5 / CRC-checksum of signal group according to AUTOSAR Profile 5
          signal PT4_PTCoor_DrvPosn_Disp_Rq_ST3: start 38, 8 bit, little-endian, data-type-policy=OVERRIDE, i-signal-type=PRIMITIVE, init-value=255, base-type=uint8, invalid-value=255, compu-method=c08_TxDrvPosn, data-constr=c08_TxDrvPosn, transfer-property=PENDING  # Anforderung Anzeige Getriebefahrstufe / Transmission driving position display request
          signal PT4_PTCoor_DrvPosn_N_Actv_ST3: start 28, 2 bit, little-endian, data-type-policy=OVERRIDE, i-signal-type=PRIMITIVE, init-value=3, base-type=uint8, invalid-value=3, compu-method=c02_Inact_Act_ST3, data-constr=c02_Inact_Act_ST3, transfer-property=PENDING  # Fahrerwunsch "N" einlegen / Transmission neutral position request by driver
          signal PT4_PTCoor_DrvPosn_Target_ST3: start 48, 4 bit, little-endian, data-type-policy=OVERRIDE, i-signal-type=PRIMITIVE, init-value=15, base-type=uint8, invalid-value=15, compu-method=c04_DrvPosn_ST3, data-constr=c04_DrvPosn_ST3, transfer-property=PENDING  # Powertrain Zielfahrstufe / Powertrain commanded driving position
          signal PT4_PTCoor_Gr_ST3: start 30, 4 bit, little-endian, data-type-policy=OVERRIDE, i-signal-type=PRIMITIVE, init-value=15, base-type=uint8, invalid-value=15, compu-method=c04_Gr, data-constr=c04_Gr, transfer-property=PENDING  # Ist-Gang Powertrain zu Fahrzeug / Actual gear
          signal PT4_PTCoor_Gr_Target_ST3: start 34, 4 bit, little-endian, data-type-policy=OVERRIDE, i-signal-type=PRIMITIVE, init-value=15, base-type=uint8, invalid-value=15, compu-method=c04_Gr_Target, data-constr=c04_Gr_Target, transfer-property=PENDING  # Ziel-Gang / Target gear
          signal PT4_PTCoor_ShW_MnTrctAxl_D_Allowed_ST3: start 46, 2 bit, little-endian, data-type-policy=OVERRIDE, i-signal-type=PRIMITIVE, init-value=3, base-type=uint8, invalid-value=3, compu-method=c02_Ndef_False_True_ST3, data-constr=c02_Ndef_False_True_ST3, transfer-property=PENDING  # Hauptantriebsachse: Fahrposition D erlaubt / Main traction axle driving position D is allowed
          signal PT4_PTCoor_ShW_MnTrctAxl_N_Allowed_ST3: start 52, 2 bit, little-endian, data-type-policy=OVERRIDE, i-signal-type=PRIMITIVE, init-value=3, base-type=uint8, invalid-value=3, compu-method=c02_Ndef_False_True_ST3, data-constr=c02_Ndef_False_True_ST3, transfer-property=PENDING  # Hauptantriebsachse: Fahrposition N erlaubt / Main traction axle driving position N is allowed
          signal PT4_PTCoor_ShW_MnTrctAxl_P_Allow_Drv_ST3: start 60, 2 bit, little-endian, data-type-policy=OVERRIDE, i-signal-type=PRIMITIVE, init-value=3, base-type=uint8, invalid-value=3, compu-method=c02_Ndef_False_True_ST3, data-constr=c02_Ndef_False_True_ST3, transfer-property=PENDING  # Hauptantriebsachse: Fahrposition P für Fahrer zum Einlegen erlaubt / Main traction axle driving position P is allowed for driver to engange
          signal PT4_PTCoor_ShW_MnTrctAxl_P_Allowed_ST3: start 54, 2 bit, little-endian, data-type-policy=OVERRIDE, i-signal-type=PRIMITIVE, init-value=3, base-type=uint8, invalid-value=3, compu-method=c02_Ndef_False_True_ST3, data-constr=c02_Ndef_False_True_ST3, transfer-property=PENDING  # Hauptantriebsachse: Fahrposition P erlaubt / Main traction axle driving position P is allowed
          signal PT4_PTCoor_ShW_MnTrctAxl_R_Allowed_ST3: start 58, 2 bit, little-endian, data-type-policy=OVERRIDE, i-signal-type=PRIMITIVE, init-value=3, base-type=uint8, invalid-value=3, compu-method=c02_Ndef_False_True_ST3, data-constr=c02_Ndef_False_True_ST3, transfer-property=PENDING  # Hauptantriebsachse: Fahrposition R erlaubt / Main traction axle driving position R is allowed
          signal PT4_PTCoor_SSA_Standby_Stat_ST3: start 56, 2 bit, little-endian, data-type-policy=OVERRIDE, i-signal-type=PRIMITIVE, init-value=0, base-type=uint8, invalid-value=3, compu-method=c02_SSA_Standby_Stat, data-constr=c02_SSA_Standby_Stat, transfer-property=PENDING  # Stop Start Standby Status
          signal Rsrv1_PT4_PTCoor_DrvPosn_Gear_Pr5_ST3: start 62, 2 bit, little-endian, data-type-policy=OVERRIDE, i-signal-type=PRIMITIVE, init-value=3, base-type=uint8, invalid-value=3, data-constr=Rsrv02, transfer-property=PENDING  # Reserviert für zukünftige Verwendung / Reserved for future use
          signal SQC_PT4_PTCoor_DrvPosn_Gear_Pr5_ST3: start 16, 8 bit, little-endian, data-type-policy=OVERRIDE, i-signal-type=PRIMITIVE, init-value=0, base-type=uint8, compu-method=none_1_0, data-constr=c08_0_255_1_SNA_na, transfer-property=PENDING  # Sequenzzähler / Sequence counter
          mapping PT4_PTCoor_DrvPosn_Gear_Pr5_ST3_5p8cvrni3ypvuac33rj2asfy9: i-signal-group=PT4_PTCoor_DrvPosn_Gear_Pr5_ST3_5p8cvrni3ypvuac33rj2asfy9, packing-byte-order=little-endian, transfer-property=TRIGGERED-ON-CHANGE
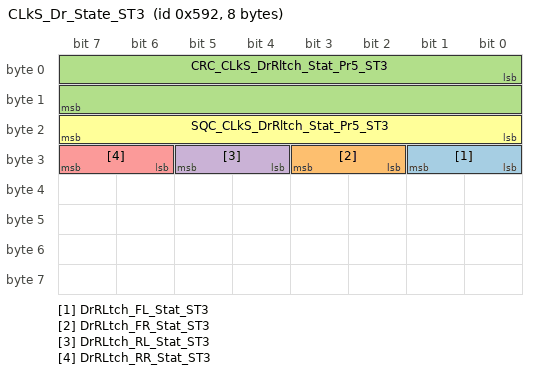
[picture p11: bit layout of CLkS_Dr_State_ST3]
      frame CLkS_Dr_State_ST3: id 0x592, to RBTM_FL, frame-length=8, variation-point=post-build-variant-condition{matching-criterion=SideAllocation, value=0}, can-addressing-mode=STANDARD  # Status Zentralverriegelung Türen / Central Locking System door state
        pdu CLkS_Dr_State_ST3: length=8, minimum-delay=0.02, transmission-mode-true-timing={cyclic-timing=time-period=0.1, event-controlled-timing=number-of-repetitions=0}, unused-bit-pattern=255  # Status Zentralverriegelung Türen / Central Locking System door state
          signal DrRLtch_FL_Stat_ST3: start 24, 2 bit, little-endian, data-type-policy=OVERRIDE, i-signal-type=PRIMITIVE, init-value=3, base-type=uint8, invalid-value=3, compu-method=c02_Dr_Stat, data-constr=c02_Dr_Stat, to RBTM_FL  # Status Drehfalle Tür vorne links / Rotary latch door front left state
          signal DrRLtch_FR_Stat_ST3: start 26, 2 bit, little-endian, data-type-policy=OVERRIDE, i-signal-type=PRIMITIVE, init-value=3, base-type=uint8, invalid-value=3, compu-method=c02_Dr_Stat, data-constr=c02_Dr_Stat, to RBTM_FL  # Status Drehfalle Tür vorne rechts / Rotary latch door front right state
          signal CRC_CLkS_DrRltch_Stat_Pr5_ST3: start 0, 16 bit, little-endian, data-type-policy=OVERRIDE, i-signal-type=PRIMITIVE, init-value=18640, base-type=uint16, data-constr=c16_CRC_woSNA, transfer-property=PENDING  # CRC-Checksumme der Signal Gruppe gemäß AUTOSAR Profil 5 / CRC-checksum of signal group according to AUTOSAR Profile 5
          signal DrRLtch_RL_Stat_ST3: start 28, 2 bit, little-endian, data-type-policy=OVERRIDE, i-signal-type=PRIMITIVE, init-value=3, base-type=uint8, invalid-value=3, compu-method=c02_Dr_Stat, data-constr=c02_Dr_Stat, transfer-property=PENDING  # Status Drehfalle Tür hinten links / Rotary latch door rear left state
          signal DrRLtch_RR_Stat_ST3: start 30, 2 bit, little-endian, data-type-policy=OVERRIDE, i-signal-type=PRIMITIVE, init-value=3, base-type=uint8, invalid-value=3, compu-method=c02_Dr_Stat, data-constr=c02_Dr_Stat, transfer-property=PENDING  # Status Drehfalle Tür hinten rechts / Rotary latch door rear right state
          signal SQC_CLkS_DrRltch_Stat_Pr5_ST3: start 16, 8 bit, little-endian, data-type-policy=OVERRIDE, i-signal-type=PRIMITIVE, init-value=0, base-type=uint8, compu-method=none_1_0, data-constr=c08_0_255_1_SNA_na, transfer-property=PENDING  # Sequenzzähler / Sequence counter
          mapping CLkS_DrRltch_Stat_Pr5_ST3_7at68qvnk0r9npofyykyfq82v: i-signal-group=CLkS_DrRltch_Stat_Pr5_ST3_7at68qvnk0r9npofyykyfq82v, packing-byte-order=little-endian, transfer-property=TRIGGERED-ON-CHANGE
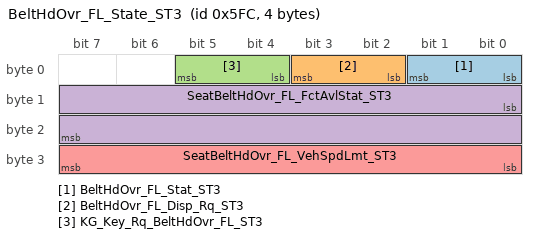
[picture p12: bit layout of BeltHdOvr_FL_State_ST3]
      frame BeltHdOvr_FL_State_ST3: id 0x5FC, to RBTM_FL, frame-length=4, variation-point=post-build-variant-condition{matching-criterion=SideAllocation, value=0}, can-addressing-mode=STANDARD  # Status Gurtbringer vorne links / Belt hand over front left state
        pdu BeltHdOvr_FL_State_ST3: length=4, minimum-delay=0.04, transmission-mode-true-timing={cyclic-timing=time-period=0.5, event-controlled-timing=number-of-repetitions=0}, unused-bit-pattern=255  # Status Gurtbringer vorne links / Belt hand over front left state
          signal BeltHdOvr_FL_Stat_ST3: start 0, 2 bit, little-endian, data-type-policy=OVERRIDE, i-signal-type=PRIMITIVE, init-value=3, base-type=uint8, invalid-value=3, compu-method=c02_BeltHdOvr_Stat, data-constr=c02_BeltHdOvr_Stat, transfer-property=TRIGGERED-ON-CHANGE, to RBTM_FL(timeout 5.25 s)  # Status Gurtbringer vorne links / Belt hand over front left state
          signal BeltHdOvr_FL_Disp_Rq_ST3: start 2, 2 bit, little-endian, data-type-policy=OVERRIDE, i-signal-type=PRIMITIVE, init-value=3, base-type=uint8, invalid-value=3, compu-method=c02_Ndef_False_True_ST3, data-constr=c02_Ndef_False_True_ST3, transfer-property=PENDING  # Gurtbringer vorne links Anzeigeanforderung / Belt hand over front left display request
          signal KG_Key_Rq_BeltHdOvr_FL_ST3: start 4, 2 bit, little-endian, data-type-policy=OVERRIDE, i-signal-type=PRIMITIVE, init-value=3, base-type=uint8, invalid-value=3, compu-method=c02_Ndef_False_True_ST3, data-constr=c02_Ndef_False_True_ST3, transfer-property=PENDING  # Abfrage Keyless Go Schlüssel / Keyless go key request
          signal SeatBeltHdOvr_FL_FctAvlStat_ST3: start 8, 16 bit, little-endian, data-type-policy=OVERRIDE, i-signal-type=PRIMITIVE, init-value=0, base-type=uint16, compu-method=c16_SeatBeltHdOvr_FctAvlStat_ST3, transfer-property=PENDING  # nicht erfüllte Funktionsbedingungen Gurtbringer vorne links / unfulfilled preconditions for belt handover front left
          signal SeatBeltHdOvr_FL_VehSpdLmt_ST3: start 24, 8 bit, little-endian, data-type-policy=OVERRIDE, i-signal-type=PRIMITIVE, init-value=255, base-type=uint8, invalid-value=255, compu-method=c08_km_p_h_0_250_1_Blank, data-constr=c08_km_p_h_0_250_1_Blank, transfer-property=PENDING  # Geschwindigkeitsschwelle für die Funktion Gurtbringer vorne links / vehicle speed threshold for seatbelt handover front left
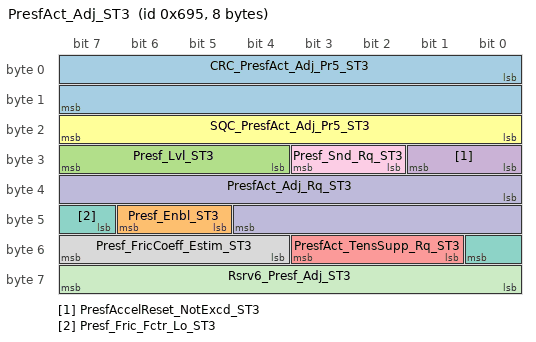
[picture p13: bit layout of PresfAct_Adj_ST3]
      frame PresfAct_Adj_ST3: id 0x695, to RBTM_FL, frame-length=8, variation-point=post-build-variant-condition{matching-criterion=SideAllocation, value=0}, can-addressing-mode=STANDARD  # Presf Aktor Steuerung ST3 / Presf Actuator adjustment ST3
        pdu PresfAct_Adj_ST3: length=8, minimum-delay=0.02, transmission-mode-condition{data-filter={data-filter-type=MASKED-NEW-DIFFERS-X, mask=15, x=0}, i-signal-in-i-pdu=Presf_Lvl_ST3}, transmission-mode-false-timing=cyclic-timing={time-offset=0.01, time-period=0.2}, transmission-mode-true-timing=cyclic-timing={time-offset=0.01, time-period=0.02}, unused-bit-pattern=255  # Presf Aktor Steuerung ST3 / Presf Actuator adjustment ST3
          signal CRC_PresfAct_Adj_Pr5_ST3: start 0, 16 bit, little-endian, data-type-policy=OVERRIDE, i-signal-type=PRIMITIVE, init-value=56639, base-type=uint16, data-constr=c16_CRC_woSNA, to RBTM_FL(timeout 2.1 s)  # CRC-Checksumme der Signal Gruppe gemäß AUTOSAR Profil 5 / CRC-checksum of signal group according to AUTOSAR Profile 5
          signal Presf_Enbl_ST3: start 45, 2 bit, little-endian, data-type-policy=OVERRIDE, i-signal-type=PRIMITIVE, init-value=3, base-type=uint8, invalid-value=3, compu-method=c02_false_true_sna, data-constr=c02_false_true_sna, to RBTM_FL(timeout 2.1 s)  # Presafe ermöglicht / Presafe enabled
          signal Presf_Lvl_ST3: start 28, 4 bit, little-endian, data-type-policy=OVERRIDE, i-signal-type=PRIMITIVE, init-value=0, base-type=uint8, invalid-value=15, compu-method=c04_Presf_Lvl_V2, data-constr=c04_Presf_Lvl_V2, to RBTM_FL(timeout 2.1 s)  # Presafe-Level / Presafe level
          signal PresfAccelReset_NotExcd_ST3: start 24, 2 bit, little-endian, data-type-policy=OVERRIDE, i-signal-type=PRIMITIVE, init-value=2, base-type=uint8, invalid-value=3, compu-method=c02_Ndef_False_True_ST3, data-constr=c02_Ndef_False_True_ST3, to RBTM_FL(timeout 2.1 s)  # Presafe Beschleunigungs-Schwelle für Rücksetzen nicht überschritten / Presafe acceleration treshold for reset not exceeded
          signal PresfAct_TensSupp_Rq_ST3: start 49, 3 bit, little-endian, data-type-policy=OVERRIDE, i-signal-type=PRIMITIVE, init-value=7, base-type=uint8, invalid-value=7, compu-method=c03_No_Lt_Rt_Both, data-constr=c03_No_Lt_Rt_Both, to RBTM_FL(timeout 2.1 s)  # Unterdrückung Gurtstraffung / Presafe actuator tensioning suppress request
          signal SQC_PresfAct_Adj_Pr5_ST3: start 16, 8 bit, little-endian, data-type-policy=OVERRIDE, i-signal-type=PRIMITIVE, init-value=0, base-type=uint8, compu-method=none_1_0, data-constr=c08_0_255_1_SNA_na, to RBTM_FL(timeout 2.1 s)  # Sequenzzähler / Sequence counter
          signal Presf_Fric_Fctr_Lo_ST3: start 47, 2 bit, little-endian, data-type-policy=OVERRIDE, i-signal-type=PRIMITIVE, init-value=3, base-type=uint8, invalid-value=3, compu-method=c02_false_true_sna, data-constr=c02_false_true_sna, to RBTM_FL  # Presafe detektiert niedrigen Reibwert / Presafe detects low friction factor
          signal Presf_FricCoeff_Estim_ST3: start 52, 4 bit, little-endian, data-type-policy=OVERRIDE, i-signal-type=PRIMITIVE, init-value=15, base-type=uint8, invalid-value=15, compu-method=c04_Presf_Frct_ST3, data-constr=c04_Presf_Frct_ST3, to RBTM_FL  # Presafe Reibwertschätzung / Presafe Friction Coefficient estimated
          signal Presf_Snd_Rq_ST3: start 26, 2 bit, little-endian, data-type-policy=OVERRIDE, i-signal-type=PRIMITIVE, init-value=0, base-type=uint8, invalid-value=3, compu-method=c02_Presf_Snd, data-constr=c02_Presf_Snd, to RBTM_FL  # Anforderung Presafe sound / Presafe sound request
          signal PresfAct_Adj_Rq_ST3: start 32, 13 bit, little-endian, data-type-policy=OVERRIDE, i-signal-type=PRIMITIVE, init-value=0, base-type=uint32, compu-method=c13_PresfAct_Adj_Rq, to RBTM_FL  # Presf Aktor Steuerung Rq / Presf Actuator adjustment Rq
          signal Rsrv6_Presf_Adj_ST3: start 56, 8 bit, little-endian, data-type-policy=OVERRIDE, i-signal-type=PRIMITIVE, init-value=255, base-type=uint8, invalid-value=255, data-constr=Rsrv08, to RBTM_FL  # Reserviert für zukünftige Verwendung / Reserved for future use
          mapping PresfAct_Adj_Pr5_ST3_2joar1a41xrgjqab60epnbplm: i-signal-group=PresfAct_Adj_Pr5_ST3_2joar1a41xrgjqab60epnbplm, packing-byte-order=little-endian, transfer-property=PENDING
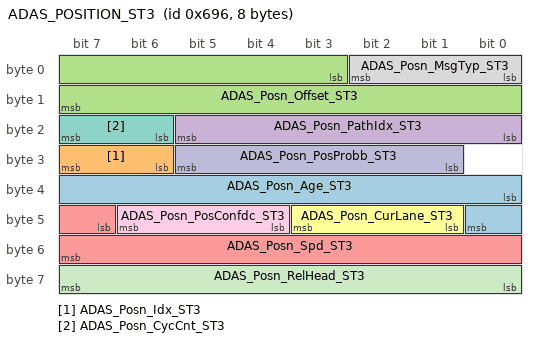
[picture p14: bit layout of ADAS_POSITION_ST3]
      frame ADAS_POSITION_ST3: id 0x696, to RBTM_FL, frame-length=8, variation-point=post-build-variant-condition{matching-criterion=SideAllocation, value=0}, can-addressing-mode=STANDARD
        pdu ADAS_POSITION_ST3: length=8, transmission-mode-true-timing=cyclic-timing=time-period=0.5, unused-bit-pattern=255
          signal ADAS_Posn_Age_ST3: start 32, 9 bit, little-endian, data-type-policy=OVERRIDE, i-signal-type=PRIMITIVE, init-value=511, base-type=uint32, invalid-value=511, compu-method=c09_ms_0_510_5, data-constr=c09_ms_0_510_5, to RBTM_FL(timeout 5.1 s)  # Age of the position relative to timestamp of last received GPS message. / Position Age
          signal ADAS_Posn_Idx_ST3: start 30, 2 bit, little-endian, data-type-policy=OVERRIDE, i-signal-type=PRIMITIVE, init-value=0, base-type=uint8, compu-method=c03_ADAS_Posn_Idx, data-constr=c03_ADAS_Posn_Idx, to RBTM_FL(timeout 5.1 s)  # Index des Postionkandidaten / index of this Position Candidate
          signal ADAS_Posn_Offset_ST3: start 3, 13 bit, little-endian, data-type-policy=OVERRIDE, i-signal-type=PRIMITIVE, init-value=8191, base-type=uint16, invalid-value=8191, compu-method=c13_m_0_8190_1, data-constr=c13_m_0_8190_1, to RBTM_FL(timeout 5.1 s)  # Offeset derzeitigen Position ab dem Startpunkt modulo 8191 / Position Message: Offset of current position from the start point modulo 8191i
          signal ADAS_Posn_PathIdx_ST3: start 16, 6 bit, little-endian, data-type-policy=OVERRIDE, i-signal-type=PRIMITIVE, init-value=0, base-type=uint8, compu-method=c06_Idx_0_to_63_1, data-constr=c06_Idx_0_to_63_1, to RBTM_FL(timeout 5.1 s)  # Position Message: Index derzeitigen Path / Position Message: Index of current path
          signal ADAS_Posn_Spd_ST3: start 47, 9 bit, little-endian, data-type-policy=OVERRIDE, i-signal-type=PRIMITIVE, init-value=511, base-type=uint16, invalid-value=511, compu-method=c09_m_p_s_m12k8_89k2_0k2, data-constr=c09_m_p_s_m12k8_89k2_0k2, to RBTM_FL(timeout 5.1 s)  # Geschwindigkeit des Fahrzeuges / Speed of the vehicle projected to the link
          signal ADAS_Posn_CurLane_ST3: start 41, 3 bit, little-endian, data-type-policy=OVERRIDE, i-signal-type=PRIMITIVE, init-value=0, base-type=uint8, invalid-value=7, compu-method=c03_ADAS_Posn_CurLane, data-constr=c03_ADAS_Posn_CurLane  # derzeitige Fahrspur / Current lane
          signal ADAS_Posn_CycCnt_ST3: start 22, 2 bit, little-endian, data-type-policy=OVERRIDE, i-signal-type=PRIMITIVE, init-value=0, base-type=uint8, compu-method=c02_0_3_1_nSNA, data-constr=c02_0_3_1_nSNA  # Position Message: Zyklischer Zähler / Position Message: Cyclic Counter
          signal ADAS_Posn_MsgTyp_ST3: start 0, 3 bit, little-endian, data-type-policy=OVERRIDE, i-signal-type=PRIMITIVE, init-value=1, base-type=uint8, invalid-value=7, compu-method=c03_MsgTyp_1_to_7, data-constr=c03_MsgTyp_1_to_7  # Position Message: Messagetype / Position Message: Message Typ
          signal ADAS_Posn_PosConfdc_ST3: start 44, 3 bit, little-endian, data-type-policy=OVERRIDE, i-signal-type=PRIMITIVE, init-value=7, base-type=uint8, invalid-value=7, compu-method=c03_0_6_1, data-constr=c03_0_6_1  # Position Confidence
          signal ADAS_Posn_PosProbb_ST3: start 25, 5 bit, little-endian, data-type-policy=OVERRIDE, i-signal-type=PRIMITIVE, init-value=31, base-type=uint8, invalid-value=31, compu-method=c05_perc_0_31_3k333, data-constr=c05_perc_0_31_3k333  # Positionmöglichkeit / Position Probability
          signal ADAS_Posn_RelHead_ST3: start 56, 8 bit, little-endian, data-type-policy=OVERRIDE, i-signal-type=PRIMITIVE, init-value=255, base-type=uint8, invalid-value=255, compu-method=c08_deg_0_358k5_1k417, data-constr=c08_deg_0_358k5_1k417  # Richtung / Heading relative to path: 0 in path dir., 1..126 right from, 253..128 left from, 127 in opp. dir.
          mapping ADAS_Posn_ST3_cre9f2x2lehhx0k4gxnl4u9sg: i-signal-group=ADAS_Posn_ST3_cre9f2x2lehhx0k4gxnl4u9sg, packing-byte-order=little-endian, transfer-property=PENDING
      frame RBTM_FL_Stat_ST3: id 0x698, from RBTM_FL, frame-length=8, variation-point=post-build-variant-condition{matching-criterion=SideAllocation, value=0}, can-addressing-mode=STANDARD  # RBTM vorne links Status ST3 / RBTM front left state ST3
        pdu RBTM_FL_Stat_ST3: length=8, minimum-delay=0.04, transmission-mode-true-timing={cyclic-timing={time-offset=0.02, time-period=1}, event-controlled-timing=number-of-repetitions=0}, unused-bit-pattern=255  # RBTM vorne links Status / RBTM front left state
          signal PS_Curve_FL_Stat_ST3: start 2, 2 bit, little-endian, data-type-policy=OVERRIDE, i-signal-type=PRIMITIVE, init-value=3, base-type=uint8, invalid-value=3, compu-method=c02_Off_Stage1_Stage2, data-constr=c02_Off_Stage1_Stage2, transfer-property=TRIGGERED-ON-CHANGE, variation-point=post-build-variant-condition{matching-criterion=SideAllocation, value=0}  # PreSafe Curve Status vorne links / PreSafe Curve mode state front left
          signal RBTM_FL_Disp_Rq_ST3: start 24, 2 bit, little-endian, data-type-policy=OVERRIDE, i-signal-type=PRIMITIVE, init-value=0, base-type=uint8, compu-method=c02_Presf_Disp_Rq, data-constr=c02_Presf_Disp_Rq, transfer-property=TRIGGERED-ON-CHANGE, variation-point=post-build-variant-condition{matching-criterion=SideAllocation, value=0}  # Presafe Kombimeldung vorne links anzeigen / Presafe display request front left
          signal RBTM_FL_Tgl_ST3: start 26, 1 bit, little-endian, data-type-policy=OVERRIDE, i-signal-type=PRIMITIVE, init-value=0, base-type=boolean, transfer-property=PENDING  # Presafe Togglebit
          signal RevBltTns_FL_SafeCyc_Actv_ST3: start 0, 2 bit, little-endian, data-type-policy=OVERRIDE, i-signal-type=PRIMITIVE, init-value=3, base-type=uint8, invalid-value=3, compu-method=c02_Ndef_False_True_ST3, data-constr=c02_Ndef_False_True_ST3, transfer-property=TRIGGERED-ON-CHANGE, to RBTM_FL  # Reversibler Gurtstraffer vorne links Sicherheits-Straffzyklus aktiv / Reversible belt tensioner front left safety tensioning cycle active
          signal PS_Curve_FL_Stat_ST3: start 2, 2 bit, little-endian, data-type-policy=OVERRIDE, i-signal-type=PRIMITIVE, init-value=3, base-type=uint8, invalid-value=3, compu-method=c02_Off_Stage1_Stage2, data-constr=c02_Off_Stage1_Stage2, transfer-property=PENDING, variation-point=post-build-variant-condition{matching-criterion=SideAllocation, value=1}  # PreSafe Curve Status vorne links / PreSafe Curve mode state front left
          signal RBTM_FL_Disp_Rq_ST3: start 24, 2 bit, little-endian, data-type-policy=OVERRIDE, i-signal-type=PRIMITIVE, init-value=0, base-type=uint8, compu-method=c02_Presf_Disp_Rq, data-constr=c02_Presf_Disp_Rq, transfer-property=PENDING, variation-point=post-build-variant-condition{matching-criterion=SideAllocation, value=1}  # Presafe Kombimeldung vorne links anzeigen / Presafe display request front left
      frame RBTM_FR_Stat_ST3: id 0x699, to RBTM_FL, frame-length=8, variation-point=post-build-variant-condition{matching-criterion=SideAllocation, value=0}, can-addressing-mode=STANDARD  # RBTM vorne rechts Status ST3 / RBTM front right state ST3
        pdu RBTM_FR_Stat_ST3: length=8, minimum-delay=0.04, transmission-mode-true-timing={cyclic-timing={time-offset=0.01, time-period=1}, event-controlled-timing=number-of-repetitions=0}, unused-bit-pattern=255  # RBTM vorne rechts Status / RBTM front right state
          signal RevBltTns_FR_SafeCyc_Actv_ST3: start 0, 2 bit, little-endian, data-type-policy=OVERRIDE, i-signal-type=PRIMITIVE, init-value=3, base-type=uint8, invalid-value=3, compu-method=c02_Ndef_False_True_ST3, data-constr=c02_Ndef_False_True_ST3, transfer-property=TRIGGERED-ON-CHANGE, to RBTM_FL  # Reversibler Gurtstraffer vorne rechts Sicherheits-Straffzyklus aktiv / Reversible belt tensioner front right safety tensioning cycle active
          signal PS_Curve_FR_Stat_ST3: start 2, 2 bit, little-endian, data-type-policy=OVERRIDE, i-signal-type=PRIMITIVE, init-value=3, base-type=uint8, invalid-value=3, compu-method=c02_Off_Stage1_Stage2, data-constr=c02_Off_Stage1_Stage2, transfer-property=PENDING, variation-point=post-build-variant-condition{matching-criterion=SideAllocation, value=0}  # PreSafe Curve Status vorne rechts / PreSafe Curve mode state front right
          signal RBTM_FR_Disp_Rq_ST3: start 24, 2 bit, little-endian, data-type-policy=OVERRIDE, i-signal-type=PRIMITIVE, init-value=0, base-type=uint8, compu-method=c02_Presf_Disp_Rq, data-constr=c02_Presf_Disp_Rq, transfer-property=PENDING, variation-point=post-build-variant-condition{matching-criterion=SideAllocation, value=0}  # Presafe Kombimeldung vorne rechts anzeigen / Presafe display request front right
          signal RBTM_FR_Tgl_ST3: start 26, 1 bit, little-endian, data-type-policy=OVERRIDE, i-signal-type=PRIMITIVE, init-value=0, base-type=boolean, transfer-property=PENDING  # Presafe Togglebit
          signal PS_Curve_FR_Stat_ST3: start 2, 2 bit, little-endian, data-type-policy=OVERRIDE, i-signal-type=PRIMITIVE, init-value=3, base-type=uint8, invalid-value=3, compu-method=c02_Off_Stage1_Stage2, data-constr=c02_Off_Stage1_Stage2, transfer-property=TRIGGERED-ON-CHANGE, variation-point=post-build-variant-condition{matching-criterion=SideAllocation, value=1}  # PreSafe Curve Status vorne rechts / PreSafe Curve mode state front right
          signal RBTM_FR_Disp_Rq_ST3: start 24, 2 bit, little-endian, data-type-policy=OVERRIDE, i-signal-type=PRIMITIVE, init-value=0, base-type=uint8, compu-method=c02_Presf_Disp_Rq, data-constr=c02_Presf_Disp_Rq, transfer-property=TRIGGERED-ON-CHANGE, variation-point=post-build-variant-condition{matching-criterion=SideAllocation, value=1}  # Presafe Kombimeldung vorne rechts anzeigen / Presafe display request front right
      frame BeltAdj_FL_Stat_ST3: id 0x6A0, from RBTM_FL, frame-length=1, variation-point=post-build-variant-condition{matching-criterion=SideAllocation, value=0}, can-addressing-mode=STANDARD  # Gurtanpassung vorne links Status / Belt adjustment front left state
        pdu BeltAdj_FL_Stat_ST3: length=1, minimum-delay=0.04, transmission-mode-true-timing={cyclic-timing={time-offset=0.01, time-period=1}, event-controlled-timing=number-of-repetitions=0}, unused-bit-pattern=255  # Gurtanpassung vorne links Status / Belt adjustment front left state
          signal BltSlckDec_Md_FL_Stat_ST3: start 0, 2 bit, little-endian, data-type-policy=OVERRIDE, i-signal-type=PRIMITIVE, init-value=3, base-type=uint8, invalid-value=3, compu-method=c02_Off_On, data-constr=c02_Off_On, transfer-property=TRIGGERED-ON-CHANGE, variation-point=post-build-variant-condition{matching-criterion=SideAllocation, value=0}  # Modus Gurtlosereduktion Status vorne links / Belt slack decreasing mode front left state
          signal RevBltTns_FL_ComCyc_Actv_ST3: start 2, 2 bit, little-endian, data-type-policy=OVERRIDE, i-signal-type=PRIMITIVE, init-value=3, base-type=uint8, invalid-value=3, compu-method=c02_Ndef_False_True_ST3, data-constr=c02_Ndef_False_True_ST3, transfer-property=TRIGGERED-ON-CHANGE, to RBTM_FL  # Reversibler Gurtstraffer vorne links Komfort-Straffzyklus aktiv / Reversible belt tensioner front left comfort tensioning cycle active
          signal BltSlckDec_Md_FL_Stat_ST3: start 0, 2 bit, little-endian, data-type-policy=OVERRIDE, i-signal-type=PRIMITIVE, init-value=3, base-type=uint8, invalid-value=3, compu-method=c02_Off_On, data-constr=c02_Off_On, transfer-property=PENDING, variation-point=post-build-variant-condition{matching-criterion=SideAllocation, value=1}  # Modus Gurtlosereduktion Status vorne links / Belt slack decreasing mode front left state
      frame BeltAdj_FR_Stat_ST3: id 0x6A1, to RBTM_FL, frame-length=1, variation-point=post-build-variant-condition{matching-criterion=SideAllocation, value=0}, can-addressing-mode=STANDARD  # Gurtanpassung vorne rechts Status / Belt adjustment front right state
        pdu BeltAdj_FR_Stat_ST3: length=1, minimum-delay=0.04, transmission-mode-true-timing={cyclic-timing={time-offset=0.02, time-period=1}, event-controlled-timing=number-of-repetitions=0}, unused-bit-pattern=255  # Gurtanpassung vorne rechts Status / Belt adjustment front right state
          signal RevBltTns_FR_ComCyc_Actv_ST3: start 2, 2 bit, little-endian, data-type-policy=OVERRIDE, i-signal-type=PRIMITIVE, init-value=3, base-type=uint8, invalid-value=3, compu-method=c02_Ndef_False_True_ST3, data-constr=c02_Ndef_False_True_ST3, transfer-property=TRIGGERED-ON-CHANGE, to RBTM_FL  # Reversibler Gurtstraffer vorne rechts Komfort-Straffzyklus aktiv / Reversible belt tensioner front right comfort tensioning cycle active
          signal BltSlckDec_Md_FR_Stat_ST3: start 0, 2 bit, little-endian, data-type-policy=OVERRIDE, i-signal-type=PRIMITIVE, init-value=3, base-type=uint8, invalid-value=3, compu-method=c02_Off_On, data-constr=c02_Off_On, transfer-property=PENDING, variation-point=post-build-variant-condition{matching-criterion=SideAllocation, value=0}  # Modus Gurtlosereduktion Status vorne rechts / Belt slack decreasing mode front right state
          signal BltSlckDec_Md_FR_Stat_ST3: start 0, 2 bit, little-endian, data-type-policy=OVERRIDE, i-signal-type=PRIMITIVE, init-value=3, base-type=uint8, invalid-value=3, compu-method=c02_Off_On, data-constr=c02_Off_On, transfer-property=TRIGGERED-ON-CHANGE, variation-point=post-build-variant-condition{matching-criterion=SideAllocation, value=1}  # Modus Gurtlosereduktion Status vorne rechts / Belt slack decreasing mode front right state
      frame BeltAdj_UI_Set_Rq_ST3: id 0x6A2, to RBTM_FL, frame-length=1, variation-point=post-build-variant-condition{matching-criterion=SideAllocation, value=0}, can-addressing-mode=STANDARD  # Anforderung Gurtanpassung Einstellungen / Belt adjustment UI setting request
        pdu BeltAdj_UI_Set_Rq_ST3: length=1, minimum-delay=0.02, transmission-mode-true-timing={cyclic-timing={time-offset=0.08, time-period=1}, event-controlled-timing=number-of-repetitions=0}, unused-bit-pattern=255  # Anforderung Gurtanpassung Einstellungen / Belt adjustment UI setting request
          signal BltSlckDec_Md_Rq_HU_ST3: start 0, 2 bit, little-endian, data-type-policy=OVERRIDE, i-signal-type=PRIMITIVE, init-value=3, base-type=uint8, invalid-value=3, compu-method=c02_Off_On, data-constr=c02_Off_On, transfer-property=TRIGGERED-ON-CHANGE, to RBTM_FL(timeout 60.5 s)  # Anforderung Modus Gurtlosereduktion von Headunit / Belt slack decreasing mode request from Head Unit
          signal PS_Curve_FL_Rq_HU_ST3: start 2, 2 bit, little-endian, data-type-policy=OVERRIDE, i-signal-type=PRIMITIVE, init-value=3, base-type=uint8, invalid-value=3, compu-method=c02_Off_Stage1_Stage2, data-constr=c02_Off_Stage1_Stage2, transfer-property=TRIGGERED-ON-CHANGE, variation-point=post-build-variant-condition{matching-criterion=SideAllocation, value=0}, to RBTM_FL(timeout 10.1 s)  # Anforderung PreSafe Curve Modus von Headunit vorne links / PreSafe Curve mode request from headunit front left
          signal PS_Curve_FR_Rq_HU_ST3: start 4, 2 bit, little-endian, data-type-policy=OVERRIDE, i-signal-type=PRIMITIVE, init-value=3, base-type=uint8, invalid-value=3, compu-method=c02_Off_Stage1_Stage2, data-constr=c02_Off_Stage1_Stage2, transfer-property=PENDING, variation-point=post-build-variant-condition{matching-criterion=SideAllocation, value=0}, to RBTM_FL(timeout 10.1 s)  # IF PS Curve vorne rechts Anforderung HU ST3 / IF PS Curve front right Request(ed) HU ST3
          signal PS_Curve_FR_Rq_HU_ST3: start 4, 2 bit, little-endian, data-type-policy=OVERRIDE, i-signal-type=PRIMITIVE, init-value=3, base-type=uint8, invalid-value=3, compu-method=c02_Off_Stage1_Stage2, data-constr=c02_Off_Stage1_Stage2, transfer-property=TRIGGERED-ON-CHANGE, variation-point=post-build-variant-condition{matching-criterion=SideAllocation, value=1}, to RBTM_FL(timeout 10.1 s)  # IF PS Curve vorne rechts Anforderung HU ST3 / IF PS Curve front right Request(ed) HU ST3
          signal PS_Curve_FL_Rq_HU_ST3: start 2, 2 bit, little-endian, data-type-policy=OVERRIDE, i-signal-type=PRIMITIVE, init-value=3, base-type=uint8, invalid-value=3, compu-method=c02_Off_Stage1_Stage2, data-constr=c02_Off_Stage1_Stage2, transfer-property=PENDING, variation-point=post-build-variant-condition{matching-criterion=SideAllocation, value=1}, to RBTM_FL(timeout 10.1 s)  # Anforderung PreSafe Curve Modus von Headunit vorne links / PreSafe Curve mode request from headunit front left
      frame Bckl_Sw_Fx_Stat_ST3: id 0x6A3, to RBTM_FL, frame-length=8, variation-point=post-build-variant-condition{matching-criterion=SideAllocation, value=0}, can-addressing-mode=STANDARD  # Bckl Sw Fx Status ST3 / Bckl Sw Fx state ST3
        secured i pdu Bckl_Sw_Fx_Stat_ST3_secured: length=8, authentication-props=SECOC_AP_CMAC_AES_128_24, freshness-props=SECOC_FP_10000_40_8_true, payload=BODY3/Bckl_Sw_Fx_Stat_ST3_76xqik47h3rgo3857pk44xg84, secure-communication-props={authentication-retries=0, data-id=15576, freshness-value-id=1}
      frame DPC_Md_Rq_ESP_d1_ST3: id 0x6C3, to RBTM_FL, frame-length=1, variation-point=post-build-variant-condition{matching-criterion=SideAllocation, value=0}, can-addressing-mode=STANDARD  # Dynamic select Anforderung / Dynamic select request
        pdu DPC_Md_Rq_ESP_d1_ST3: length=1, minimum-delay=0.1, transmission-mode-true-timing={cyclic-timing={time-offset=0, time-period=1}, event-controlled-timing=number-of-repetitions=0}, unused-bit-pattern=255  # Dynamic select Anforderung / Dynamic select request
          signal DPC_Md_PT_Rq_ST3: start 0, 5 bit, little-endian, data-type-policy=OVERRIDE, i-signal-type=PRIMITIVE, init-value=0, base-type=uint8, invalid-value=31, compu-method=c05_DPC_Md_PT_HU, data-constr=c05_DPC_Md_PT_HU, to RBTM_FL  # Fahrprogrammwahl: Anforderung Powertrain / Driving program control: powertrain mode request
          mapping DPC_Md_Rq_ESP_Pr5_ST3_dcsny138uwpesz5bmssj1scqi: i-signal-group=DPC_Md_Rq_ESP_Pr5_ST3_dcsny138uwpesz5bmssj1scqi, packing-byte-order=little-endian, transfer-property=TRIGGERED-ON-CHANGE, update-indication-bit-position=5
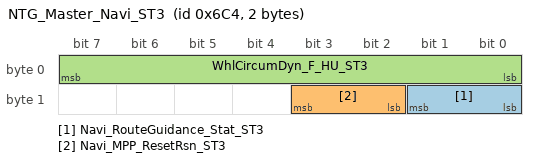
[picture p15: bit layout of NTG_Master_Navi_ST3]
      frame NTG_Master_Navi_ST3: id 0x6C4, to RBTM_FL, frame-length=2, variation-point=post-build-variant-condition{matching-criterion=SideAllocation, value=0}, can-addressing-mode=STANDARD  # New Telematics Generation Navigation Master
        pdu NTG_Master_Navi_ST3: length=2, minimum-delay=0.02, transmission-mode-true-timing={cyclic-timing={time-offset=0.01, time-period=0.2}, event-controlled-timing=number-of-repetitions=0}, unused-bit-pattern=255  # New Telematics Generation Navigation Master
          signal Navi_RouteGuidance_Stat_ST3: start 8, 2 bit, little-endian, data-type-policy=OVERRIDE, i-signal-type=PRIMITIVE, init-value=3, base-type=uint8, invalid-value=3, compu-method=c02_Inactv_Silent_Actv_ST3, data-constr=c02_Inactv_Silent_Actv_ST3, transfer-property=TRIGGERED-ON-CHANGE, to RBTM_FL(timeout 10.1 s)  # Navigation Status Zielführung / Navigation route guidance state
          signal Navi_MPP_ResetRsn_ST3: start 10, 2 bit, little-endian, data-type-policy=OVERRIDE, i-signal-type=PRIMITIVE, init-value=3, base-type=uint8, invalid-value=3, compu-method=c02_Navi_MPP_ResetRsn_ST3, data-constr=c02_Navi_MPP_ResetRsn_ST3, transfer-property=PENDING  # Navigation Grund für das Zurücksetzen des Most probable Paths / Navigation Reason for resetting the most probable path
          signal WhlCircumDyn_F_HU_ST3: start 0, 8 bit, little-endian, data-type-policy=OVERRIDE, i-signal-type=PRIMITIVE, init-value=255, base-type=uint8, invalid-value=255, compu-method=c08_m_1d6_2d87_0d005, data-constr=c08_m_1d6_2d87_0d005, transfer-property=PENDING  # Dynamische Radumfang Vorderachse von der HU / Dynamic wheel circumference front axle from HU
      frame ELC_Lvr_Stat_ST3: id 0x6C5, to RBTM_FL, frame-length=8, variation-point=post-build-variant-condition{matching-criterion=SideAllocation, value=0}, can-addressing-mode=STANDARD  # Status Bedienhebel Außenlicht / Exterior light lever state
        secured i pdu ELC_Lvr_Stat_ST3_secured: length=8, authentication-props=SECOC_AP_CMAC_AES_128_24, freshness-props=SECOC_FP_10000_40_8_true, payload=BODY3/ELC_Lvr_Stat_ST3_73cx1t6a1vhnmsct6284cefhl, secure-communication-props={authentication-retries=0, data-id=37177, freshness-value-id=1}
      frame DIAG_Stat_ST3: id 0x6D0, to RBTM_FL, frame-length=4, variation-point=post-build-variant-condition{matching-criterion=SideAllocation, value=0}, can-addressing-mode=STANDARD  # Actv Line Status Tester pres / Actv Line state Tester pres
        pdu DIAG_Stat_ST3: length=4, minimum-delay=0.04, transmission-mode-true-timing={cyclic-timing={time-offset=0.01, time-period=1}, event-controlled-timing=number-of-repetitions=0}, unused-bit-pattern=255  # Actv Line Status Tester pres / Actv Line state Tester pres
          signal DidA_ExtTest_Pres_ST3: start 2, 2 bit, little-endian, data-type-policy=OVERRIDE, i-signal-type=PRIMITIVE, init-value=3, base-type=uint8, invalid-value=3, compu-method=c02_Ndef_False_True_ST3, data-constr=c02_Ndef_False_True_ST3, transfer-property=TRIGGERED-ON-CHANGE, to RBTM_FL  # DidA Externer Tester erkannt / DidA external tester present
          signal Actv_Line_Stat_ST3: start 0, 2 bit, little-endian, data-type-policy=OVERRIDE, i-signal-type=PRIMITIVE, init-value=0, base-type=uint8, invalid-value=3, compu-method=c02_Inact_Act_ST3, data-constr=c02_Inact_Act_ST3, transfer-property=PENDING  # Aktivierungs Leitungsstatus / Activation Line state
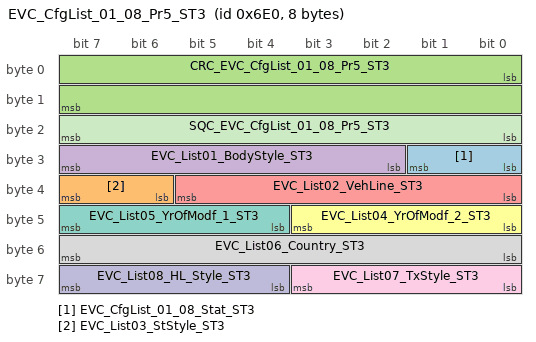
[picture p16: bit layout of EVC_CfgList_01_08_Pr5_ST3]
      frame EVC_CfgList_01_08_Pr5_ST3: id 0x6E0, to RBTM_FL, frame-length=8, variation-point=post-build-variant-condition{matching-criterion=SideAllocation, value=0}, can-addressing-mode=STANDARD  # EVC-CfgMessage[Lists:01h-08h]
        pdu EVC_CfgList_01_08_Pr5_ST3: length=8, transmission-mode-true-timing=cyclic-timing={time-offset=0.01, time-period=1}, unused-bit-pattern=255  # EVC-CfgMessage[Lists:01h-08h]
          signal EVC_CfgList_01_08_Stat_ST3: start 24, 2 bit, little-endian, data-type-policy=OVERRIDE, i-signal-type=PRIMITIVE, init-value=3, base-type=uint8, invalid-value=3, compu-method=c02_EVC_Stat, data-constr=c02_EVC_Stat, to RBTM_FL(timeout 2.5 s)  # Status EVC-CfgMessage[Listen:01h-08h] / Status EVC-CfgMessage[Lists:01h-08h]
          signal EVC_List03_StStyle_ST3: start 38, 2 bit, little-endian, data-type-policy=OVERRIDE, i-signal-type=PRIMITIVE, init-value=3, base-type=uint8, invalid-value=3, compu-method=c02_StStyle, data-constr=c02_StStyle, to RBTM_FL(timeout 2.5 s)  # Lenkungsvariante / Steering variant
          signal CRC_EVC_CfgList_01_08_Pr5_ST3: start 0, 16 bit, little-endian, data-type-policy=OVERRIDE, i-signal-type=PRIMITIVE, init-value=46137, base-type=uint16, data-constr=c16_CRC_woSNA  # CRC-Checksumme der Signal Gruppe gemäß AUTOSAR Profil 5 / CRC-checksum of signal group according to AUTOSAR Profile 5
          signal EVC_List01_BodyStyle_ST3: start 26, 6 bit, little-endian, data-type-policy=OVERRIDE, i-signal-type=PRIMITIVE, init-value=63, base-type=uint8, compu-method=c06_EVC_BodyStyle_ST3, data-constr=c06_EVC_BodyStyle_ST3  # Karosserievariante / Vehicle body style
          signal EVC_List02_VehLine_ST3: start 32, 6 bit, little-endian, data-type-policy=OVERRIDE, i-signal-type=PRIMITIVE, init-value=63, base-type=uint8, compu-method=c06_EVC_VehLine_ST3, data-constr=c06_EVC_VehLine_ST3  # Baureihe / Vehicle line
          signal EVC_List04_YrOfModf_2_ST3: start 40, 4 bit, little-endian, data-type-policy=OVERRIDE, i-signal-type=PRIMITIVE, init-value=15, base-type=uint8, compu-method=c04_EVC_YrOfModf_2_ST3, data-constr=c04_EVC_YrOfModf_2_ST3  # Änderungsjahr YY/2 / Year of Modification YY/2
          signal EVC_List05_YrOfModf_1_ST3: start 44, 4 bit, little-endian, data-type-policy=OVERRIDE, i-signal-type=PRIMITIVE, init-value=15, base-type=uint8, compu-method=c04_EVC_YrOfModf_1_ST3, data-constr=c04_EVC_YrOfModf_1_ST3  # Änderungsjahr YY/1 / Year of Modification YY/1
          signal EVC_List06_Country_ST3: start 48, 8 bit, little-endian, data-type-policy=OVERRIDE, i-signal-type=PRIMITIVE, init-value=255, base-type=uint8, compu-method=c08_EVC_Country_extended, data-constr=c08_EVC_Country_extended  # Land / Country
          signal EVC_List07_TxStyle_ST3: start 56, 4 bit, little-endian, data-type-policy=OVERRIDE, i-signal-type=PRIMITIVE, init-value=15, base-type=uint8, compu-method=c04_EVC_TxStyle_ST3, data-constr=c04_EVC_TxStyle_ST3  # Getriebeart / Transmission Style
          signal EVC_List08_HL_Style_ST3: start 60, 4 bit, little-endian, data-type-policy=OVERRIDE, i-signal-type=PRIMITIVE, init-value=15, base-type=uint8, compu-method=c04_EVC_HL_Style_ST3, data-constr=c04_EVC_HL_Style_ST3  # Scheinwerferart / Headlamp Style
          signal SQC_EVC_CfgList_01_08_Pr5_ST3: start 16, 8 bit, little-endian, data-type-policy=OVERRIDE, i-signal-type=PRIMITIVE, init-value=0, base-type=uint8, compu-method=none_1_0, data-constr=c08_0_255_1_SNA_na  # Sequenzzähler / Sequence counter
          mapping EVC_CfgList_01_08_Pr5_ST3_co3q1mwsf7pwxo2ix5jryc04x: i-signal-group=EVC_CfgList_01_08_Pr5_ST3_co3q1mwsf7pwxo2ix5jryc04x, packing-byte-order=little-endian, transfer-property=PENDING
